[part 1 of 2: packages /MICROSAR/Dem_swc/DataTypes to /MICROSAR/Dem_swc/ComponentTypes]
AUTOSAR XML (schema 4-3-0)
package /MICROSAR/Dem_swc/DataTypes
  29 x impl type:
    Dem_EventIdType: range raw 1..65535, implementation-data-type=uint16
    Dem_RatioIdType: range raw 1..65535, implementation-data-type=uint16
    Dem_DTCStatusMaskType: range raw 0..255, implementation-data-type=uint8
    Dem_OperationCycleIdType: range raw 0..255, implementation-data-type=uint8
    Dem_DTCGroupType: range raw 0..16777215, implementation-data-type=uint32
    Dem_MaxDataValueType: category=ARRAY, sw-calibration-access=READ-ONLY
      element Dem_MaxDataValueTypeElement: array-size=18, array-size-semantics=FIXED-SIZE, implementation-data-type=uint8
    Dem_EventStatusType: compu {0=DEM_EVENT_STATUS_PASSED, 1=DEM_EVENT_STATUS_FAILED, 2=DEM_EVENT_STATUS_PREPASSED, 3=DEM_EVENT_STATUS_PREFAILED, 4=DEM_EVENT_STATUS_FDC_THRESHOLD_REACHED, 5=DEM_EVENT_STATUS_PASSED_CONDITIONS_NOT_FULFILLED, 6=DEM_EVENT_STATUS_FAILED_CONDITIONS_NOT_FULFILLED, 7=DEM_EVENT_STATUS_PREPASSED_CONDITIONS_NOT_FULFILLED, 8=DEM_EVENT_STATUS_PREFAILED_CONDITIONS_NOT_FULFILLED}, implementation-data-type=uint8
    Dem_InitMonitorReasonType: compu {1=DEM_INIT_MONITOR_CLEAR, 2=DEM_INIT_MONITOR_RESTART, 3=DEM_INIT_MONITOR_REENABLED, 4=DEM_INIT_MONITOR_STORAGE_REENABLED}, implementation-data-type=uint8
    Dem_DTCOriginType: compu {1=DEM_DTC_ORIGIN_PRIMARY_MEMORY, 2=DEM_DTC_ORIGIN_MIRROR_MEMORY, 3=DEM_DTC_ORIGIN_PERMANENT_MEMORY, 4=DEM_DTC_ORIGIN_OBD_RELEVANT_MEMORY, 5=DEM_DTC_ORIGIN_SECONDARY_MEMORY, 5=DEM_DTC_ORIGIN_USERDEFINED_MEMORY_10, 5=DEM_DTC_ORIGIN_USERDEFINED_MEMORY_11, 5=DEM_DTC_ORIGIN_USERDEFINED_MEMORY_12, 5=DEM_DTC_ORIGIN_USERDEFINED_MEMORY_13, 5=DEM_DTC_ORIGIN_USERDEFINED_MEMORY_14, 5=DEM_DTC_ORIGIN_USERDEFINED_MEMORY_15, 5=DEM_DTC_ORIGIN_USERDEFINED_MEMORY_16, 5=DEM_DTC_ORIGIN_USERDEFINED_MEMORY_17, 5=DEM_DTC_ORIGIN_USERDEFINED_MEMORY_18, 5=DEM_DTC_ORIGIN_USERDEFINED_MEMORY_19, 5=DEM_DTC_ORIGIN_USERDEFINED_MEMORY_1A, 5=DEM_DTC_ORIGIN_USERDEFINED_MEMORY_1B, 5=DEM_DTC_ORIGIN_USERDEFINED_MEMORY_1C, 5=DEM_DTC_ORIGIN_USERDEFINED_MEMORY_1D, 5=DEM_DTC_ORIGIN_USERDEFINED_MEMORY_1E, 5=DEM_DTC_ORIGIN_USERDEFINED_MEMORY_1F, 5=DEM_DTC_ORIGIN_USERDEFINED_MEMORY_20, 5=DEM_DTC_ORIGIN_USERDEFINED_MEMORY_21, 5=DEM_DTC_ORIGIN_USERDEFINED_MEMORY_22, 5=DEM_DTC_ORIGIN_USERDEFINED_MEMORY_23, 5=DEM_DTC_ORIGIN_USERDEFINED_MEMORY_24, 5=DEM_DTC_ORIGIN_USERDEFINED_MEMORY_25, 5=DEM_DTC_ORIGIN_USERDEFINED_MEMORY_26, 5=DEM_DTC_ORIGIN_USERDEFINED_MEMORY_27, 5=DEM_DTC_ORIGIN_USERDEFINED_MEMORY_28, 5=DEM_DTC_ORIGIN_USERDEFINED_MEMORY_29, 5=DEM_DTC_ORIGIN_USERDEFINED_MEMORY_2A, 5=DEM_DTC_ORIGIN_USERDEFINED_MEMORY_2B, 5=DEM_DTC_ORIGIN_USERDEFINED_MEMORY_2C, 5=DEM_DTC_ORIGIN_USERDEFINED_MEMORY_2D, 5=DEM_DTC_ORIGIN_USERDEFINED_MEMORY_2E, 5=DEM_DTC_ORIGIN_USERDEFINED_MEMORY_2F, 5=DEM_DTC_ORIGIN_USERDEFINED_MEMORY_30, 5=DEM_DTC_ORIGIN_USERDEFINED_MEMORY_31, 5=DEM_DTC_ORIGIN_USERDEFINED_MEMORY_32, 5=DEM_DTC_ORIGIN_USERDEFINED_MEMORY_33, 5=DEM_DTC_ORIGIN_USERDEFINED_MEMORY_34, 5=DEM_DTC_ORIGIN_USERDEFINED_MEMORY_35, 5=DEM_DTC_ORIGIN_USERDEFINED_MEMORY_36, 5=DEM_DTC_ORIGIN_USERDEFINED_MEMORY_37, 5=DEM_DTC_ORIGIN_USERDEFINED_MEMORY_38, 5=DEM_DTC_ORIGIN_USERDEFINED_MEMORY_39, 5=DEM_DTC_ORIGIN_USERDEFINED_MEMORY_3A, 5=DEM_DTC_ORIGIN_USERDEFINED_MEMORY_3B, 5=DEM_DTC_ORIGIN_USERDEFINED_MEMORY_3C, 5=DEM_DTC_ORIGIN_USERDEFINED_MEMORY_3D, 5=DEM_DTC_ORIGIN_USERDEFINED_MEMORY_3E, 5=DEM_DTC_ORIGIN_USERDEFINED_MEMORY_3F, 5=DEM_DTC_ORIGIN_USERDEFINED_MEMORY_40, 5=DEM_DTC_ORIGIN_USERDEFINED_MEMORY_41, 5=DEM_DTC_ORIGIN_USERDEFINED_MEMORY_42, 5=DEM_DTC_ORIGIN_USERDEFINED_MEMORY_43, 5=DEM_DTC_ORIGIN_USERDEFINED_MEMORY_44, 5=DEM_DTC_ORIGIN_USERDEFINED_MEMORY_45, 5=DEM_DTC_ORIGIN_USERDEFINED_MEMORY_46, 5=DEM_DTC_ORIGIN_USERDEFINED_MEMORY_47, 5=DEM_DTC_ORIGIN_USERDEFINED_MEMORY_48, 5=DEM_DTC_ORIGIN_USERDEFINED_MEMORY_49, 5=DEM_DTC_ORIGIN_USERDEFINED_MEMORY_4A, 5=DEM_DTC_ORIGIN_USERDEFINED_MEMORY_4B, 5=DEM_DTC_ORIGIN_USERDEFINED_MEMORY_4C, 5=DEM_DTC_ORIGIN_USERDEFINED_MEMORY_4D, 5=DEM_DTC_ORIGIN_USERDEFINED_MEMORY_4E, 5=DEM_DTC_ORIGIN_USERDEFINED_MEMORY_4F, 5=DEM_DTC_ORIGIN_USERDEFINED_MEMORY_50, 5=DEM_DTC_ORIGIN_USERDEFINED_MEMORY_51, 5=DEM_DTC_ORIGIN_USERDEFINED_MEMORY_52, 5=DEM_DTC_ORIGIN_USERDEFINED_MEMORY_53, 5=DEM_DTC_ORIGIN_USERDEFINED_MEMORY_54, 5=DEM_DTC_ORIGIN_USERDEFINED_MEMORY_55, 5=DEM_DTC_ORIGIN_USERDEFINED_MEMORY_56, 5=DEM_DTC_ORIGIN_USERDEFINED_MEMORY_57, 5=DEM_DTC_ORIGIN_USERDEFINED_MEMORY_58, 5=DEM_DTC_ORIGIN_USERDEFINED_MEMORY_59, 5=DEM_DTC_ORIGIN_USERDEFINED_MEMORY_5A, 5=DEM_DTC_ORIGIN_USERDEFINED_MEMORY_5B, 5=DEM_DTC_ORIGIN_USERDEFINED_MEMORY_5C, 5=DEM_DTC_ORIGIN_USERDEFINED_MEMORY_5D, 5=DEM_DTC_ORIGIN_USERDEFINED_MEMORY_5E, 5=DEM_DTC_ORIGIN_USERDEFINED_MEMORY_5F, 5=DEM_DTC_ORIGIN_USERDEFINED_MEMORY_60, 5=DEM_DTC_ORIGIN_USERDEFINED_MEMORY_61, 5=DEM_DTC_ORIGIN_USERDEFINED_MEMORY_62, 5=DEM_DTC_ORIGIN_USERDEFINED_MEMORY_63, 5=DEM_DTC_ORIGIN_USERDEFINED_MEMORY_64, 5=DEM_DTC_ORIGIN_USERDEFINED_MEMORY_65, 5=DEM_DTC_ORIGIN_USERDEFINED_MEMORY_66, 5=DEM_DTC_ORIGIN_USERDEFINED_MEMORY_67, 5=DEM_DTC_ORIGIN_USERDEFINED_MEMORY_68, 5=DEM_DTC_ORIGIN_USERDEFINED_MEMORY_69, 5=DEM_DTC_ORIGIN_USERDEFINED_MEMORY_6A, 5=DEM_DTC_ORIGIN_USERDEFINED_MEMORY_6B, 5=DEM_DTC_ORIGIN_USERDEFINED_MEMORY_6C, 5=DEM_DTC_ORIGIN_USERDEFINED_MEMORY_6D, 5=DEM_DTC_ORIGIN_USERDEFINED_MEMORY_6E, 5=DEM_DTC_ORIGIN_USERDEFINED_MEMORY_6F, 5=DEM_DTC_ORIGIN_USERDEFINED_MEMORY_70, 5=DEM_DTC_ORIGIN_USERDEFINED_MEMORY_71, 5=DEM_DTC_ORIGIN_USERDEFINED_MEMORY_72, 5=DEM_DTC_ORIGIN_USERDEFINED_MEMORY_73, 5=DEM_DTC_ORIGIN_USERDEFINED_MEMORY_74, 5=DEM_DTC_ORIGIN_USERDEFINED_MEMORY_75, 5=DEM_DTC_ORIGIN_USERDEFINED_MEMORY_76, 5=DEM_DTC_ORIGIN_USERDEFINED_MEMORY_77, 5=DEM_DTC_ORIGIN_USERDEFINED_MEMORY_78, 5=DEM_DTC_ORIGIN_USERDEFINED_MEMORY_79, 5=DEM_DTC_ORIGIN_USERDEFINED_MEMORY_7A, 5=DEM_DTC_ORIGIN_USERDEFINED_MEMORY_7B, 5=DEM_DTC_ORIGIN_USERDEFINED_MEMORY_7C, 5=DEM_DTC_ORIGIN_USERDEFINED_MEMORY_7D, 5=DEM_DTC_ORIGIN_USERDEFINED_MEMORY_7E, 5=DEM_DTC_ORIGIN_USERDEFINED_MEMORY_7F, 5=DEM_DTC_ORIGIN_USERDEFINED_MEMORY_80, 5=DEM_DTC_ORIGIN_USERDEFINED_MEMORY_81, 5=DEM_DTC_ORIGIN_USERDEFINED_MEMORY_82, 5=DEM_DTC_ORIGIN_USERDEFINED_MEMORY_83, 5=DEM_DTC_ORIGIN_USERDEFINED_MEMORY_84, 5=DEM_DTC_ORIGIN_USERDEFINED_MEMORY_85, 5=DEM_DTC_ORIGIN_USERDEFINED_MEMORY_86, 5=DEM_DTC_ORIGIN_USERDEFINED_MEMORY_87, 5=DEM_DTC_ORIGIN_USERDEFINED_MEMORY_88, 5=DEM_DTC_ORIGIN_USERDEFINED_MEMORY_89, 5=DEM_DTC_ORIGIN_USERDEFINED_MEMORY_8A, 5=DEM_DTC_ORIGIN_USERDEFINED_MEMORY_8B, 5=DEM_DTC_ORIGIN_USERDEFINED_MEMORY_8C, 5=DEM_DTC_ORIGIN_USERDEFINED_MEMORY_8D, 5=DEM_DTC_ORIGIN_USERDEFINED_MEMORY_8E, 5=DEM_DTC_ORIGIN_USERDEFINED_MEMORY_8F, 5=DEM_DTC_ORIGIN_USERDEFINED_MEMORY_90, 5=DEM_DTC_ORIGIN_USERDEFINED_MEMORY_91, 5=DEM_DTC_ORIGIN_USERDEFINED_MEMORY_92, 5=DEM_DTC_ORIGIN_USERDEFINED_MEMORY_93, 5=DEM_DTC_ORIGIN_USERDEFINED_MEMORY_94, 5=DEM_DTC_ORIGIN_USERDEFINED_MEMORY_95, 5=DEM_DTC_ORIGIN_USERDEFINED_MEMORY_96, 5=DEM_DTC_ORIGIN_USERDEFINED_MEMORY_97, 5=DEM_DTC_ORIGIN_USERDEFINED_MEMORY_98, 5=DEM_DTC_ORIGIN_USERDEFINED_MEMORY_99, 5=DEM_DTC_ORIGIN_USERDEFINED_MEMORY_9A, 5=DEM_DTC_ORIGIN_USERDEFINED_MEMORY_9B, 5=DEM_DTC_ORIGIN_USERDEFINED_MEMORY_9C, 5=DEM_DTC_ORIGIN_USERDEFINED_MEMORY_9D, 5=DEM_DTC_ORIGIN_USERDEFINED_MEMORY_9E, 5=DEM_DTC_ORIGIN_USERDEFINED_MEMORY_9F, 5=DEM_DTC_ORIGIN_USERDEFINED_MEMORY_A0, 5=DEM_DTC_ORIGIN_USERDEFINED_MEMORY_A1, 5=DEM_DTC_ORIGIN_USERDEFINED_MEMORY_A2, 5=DEM_DTC_ORIGIN_USERDEFINED_MEMORY_A3, 5=DEM_DTC_ORIGIN_USERDEFINED_MEMORY_A4, 5=DEM_DTC_ORIGIN_USERDEFINED_MEMORY_A5, 5=DEM_DTC_ORIGIN_USERDEFINED_MEMORY_A6, 5=DEM_DTC_ORIGIN_USERDEFINED_MEMORY_A7, 5=DEM_DTC_ORIGIN_USERDEFINED_MEMORY_A8, 5=DEM_DTC_ORIGIN_USERDEFINED_MEMORY_A9, 5=DEM_DTC_ORIGIN_USERDEFINED_MEMORY_AA, 5=DEM_DTC_ORIGIN_USERDEFINED_MEMORY_AB, 5=DEM_DTC_ORIGIN_USERDEFINED_MEMORY_AC, 5=DEM_DTC_ORIGIN_USERDEFINED_MEMORY_AD, 5=DEM_DTC_ORIGIN_USERDEFINED_MEMORY_AE, 5=DEM_DTC_ORIGIN_USERDEFINED_MEMORY_AF, 5=DEM_DTC_ORIGIN_USERDEFINED_MEMORY_B0, 5=DEM_DTC_ORIGIN_USERDEFINED_MEMORY_B1, 5=DEM_DTC_ORIGIN_USERDEFINED_MEMORY_B2, 5=DEM_DTC_ORIGIN_USERDEFINED_MEMORY_B3, 5=DEM_DTC_ORIGIN_USERDEFINED_MEMORY_B4, 5=DEM_DTC_ORIGIN_USERDEFINED_MEMORY_B5, 5=DEM_DTC_ORIGIN_USERDEFINED_MEMORY_B6, 5=DEM_DTC_ORIGIN_USERDEFINED_MEMORY_B7, 5=DEM_DTC_ORIGIN_USERDEFINED_MEMORY_B8, 5=DEM_DTC_ORIGIN_USERDEFINED_MEMORY_B9, 5=DEM_DTC_ORIGIN_USERDEFINED_MEMORY_BA, 5=DEM_DTC_ORIGIN_USERDEFINED_MEMORY_BB, 5=DEM_DTC_ORIGIN_USERDEFINED_MEMORY_BC, 5=DEM_DTC_ORIGIN_USERDEFINED_MEMORY_BD, 5=DEM_DTC_ORIGIN_USERDEFINED_MEMORY_BE, 5=DEM_DTC_ORIGIN_USERDEFINED_MEMORY_BF, 5=DEM_DTC_ORIGIN_USERDEFINED_MEMORY_C0, 5=DEM_DTC_ORIGIN_USERDEFINED_MEMORY_C1, 5=DEM_DTC_ORIGIN_USERDEFINED_MEMORY_C2, 5=DEM_DTC_ORIGIN_USERDEFINED_MEMORY_C3, 5=DEM_DTC_ORIGIN_USERDEFINED_MEMORY_C4, 5=DEM_DTC_ORIGIN_USERDEFINED_MEMORY_C5, 5=DEM_DTC_ORIGIN_USERDEFINED_MEMORY_C6, 5=DEM_DTC_ORIGIN_USERDEFINED_MEMORY_C7, 5=DEM_DTC_ORIGIN_USERDEFINED_MEMORY_C8, 5=DEM_DTC_ORIGIN_USERDEFINED_MEMORY_C9, 5=DEM_DTC_ORIGIN_USERDEFINED_MEMORY_CA, 5=DEM_DTC_ORIGIN_USERDEFINED_MEMORY_CB, 5=DEM_DTC_ORIGIN_USERDEFINED_MEMORY_CC, 5=DEM_DTC_ORIGIN_USERDEFINED_MEMORY_CD, 5=DEM_DTC_ORIGIN_USERDEFINED_MEMORY_CE, 5=DEM_DTC_ORIGIN_USERDEFINED_MEMORY_CF, 5=DEM_DTC_ORIGIN_USERDEFINED_MEMORY_D0, 5=DEM_DTC_ORIGIN_USERDEFINED_MEMORY_D1, 5=DEM_DTC_ORIGIN_USERDEFINED_MEMORY_D2, 5=DEM_DTC_ORIGIN_USERDEFINED_MEMORY_D3, 5=DEM_DTC_ORIGIN_USERDEFINED_MEMORY_D4, 5=DEM_DTC_ORIGIN_USERDEFINED_MEMORY_D5, 5=DEM_DTC_ORIGIN_USERDEFINED_MEMORY_D6, 5=DEM_DTC_ORIGIN_USERDEFINED_MEMORY_D7, 5=DEM_DTC_ORIGIN_USERDEFINED_MEMORY_D8, 5=DEM_DTC_ORIGIN_USERDEFINED_MEMORY_D9, 5=DEM_DTC_ORIGIN_USERDEFINED_MEMORY_DA, 5=DEM_DTC_ORIGIN_USERDEFINED_MEMORY_DB, 5=DEM_DTC_ORIGIN_USERDEFINED_MEMORY_DC, 5=DEM_DTC_ORIGIN_USERDEFINED_MEMORY_DD, 5=DEM_DTC_ORIGIN_USERDEFINED_MEMORY_DE, 5=DEM_DTC_ORIGIN_USERDEFINED_MEMORY_DF, 5=DEM_DTC_ORIGIN_USERDEFINED_MEMORY_E0, 5=DEM_DTC_ORIGIN_USERDEFINED_MEMORY_E1, 5=DEM_DTC_ORIGIN_USERDEFINED_MEMORY_E2, 5=DEM_DTC_ORIGIN_USERDEFINED_MEMORY_E3, 5=DEM_DTC_ORIGIN_USERDEFINED_MEMORY_E4, 5=DEM_DTC_ORIGIN_USERDEFINED_MEMORY_E5, 5=DEM_DTC_ORIGIN_USERDEFINED_MEMORY_E6, 5=DEM_DTC_ORIGIN_USERDEFINED_MEMORY_E7, 5=DEM_DTC_ORIGIN_USERDEFINED_MEMORY_E8, 5=DEM_DTC_ORIGIN_USERDEFINED_MEMORY_E9, 5=DEM_DTC_ORIGIN_USERDEFINED_MEMORY_EA, 5=DEM_DTC_ORIGIN_USERDEFINED_MEMORY_EB, 5=DEM_DTC_ORIGIN_USERDEFINED_MEMORY_EC, 5=DEM_DTC_ORIGIN_USERDEFINED_MEMORY_ED, 5=DEM_DTC_ORIGIN_USERDEFINED_MEMORY_EE, 5=DEM_DTC_ORIGIN_USERDEFINED_MEMORY_EF, 5=DEM_DTC_ORIGIN_USERDEFINED_MEMORY_F0, 5=DEM_DTC_ORIGIN_USERDEFINED_MEMORY_F1, 5=DEM_DTC_ORIGIN_USERDEFINED_MEMORY_F2, 5=DEM_DTC_ORIGIN_USERDEFINED_MEMORY_F3, 5=DEM_DTC_ORIGIN_USERDEFINED_MEMORY_F4, 5=DEM_DTC_ORIGIN_USERDEFINED_MEMORY_F5, 5=DEM_DTC_ORIGIN_USERDEFINED_MEMORY_F6, 5=DEM_DTC_ORIGIN_USERDEFINED_MEMORY_F7, 5=DEM_DTC_ORIGIN_USERDEFINED_MEMORY_F8, 5=DEM_DTC_ORIGIN_USERDEFINED_MEMORY_F9, 5=DEM_DTC_ORIGIN_USERDEFINED_MEMORY_FA, 5=DEM_DTC_ORIGIN_USERDEFINED_MEMORY_FB, 5=DEM_DTC_ORIGIN_USERDEFINED_MEMORY_FC, 5=DEM_DTC_ORIGIN_USERDEFINED_MEMORY_FD, 5=DEM_DTC_ORIGIN_USERDEFINED_MEMORY_FE, 5=DEM_DTC_ORIGIN_USERDEFINED_MEMORY_FF}, implementation-data-type=uint16
    Dem_DTCFormatType: compu {0=DEM_DTC_FORMAT_OBD, 1=DEM_DTC_FORMAT_UDS, 2=DEM_DTC_FORMAT_J1939}, implementation-data-type=uint8
    Dem_OperationCycleStateType: compu {0=DEM_CYCLE_STATE_START, 1=DEM_CYCLE_STATE_END}, implementation-data-type=uint8
    Dem_IndicatorStatusType: compu {0=DEM_INDICATOR_OFF, 1=DEM_INDICATOR_CONTINUOUS, 2=DEM_INDICATOR_BLINKING, 3=DEM_INDICATOR_BLINK_CONT, 4=DEM_INDICATOR_SLOW_FLASH, 5=DEM_INDICATOR_FAST_FLASH, 6=DEM_INDICATOR_ON_DEMAND, 7=DEM_INDICATOR_SHORT}, implementation-data-type=uint8
    Dem_DTCKindType: compu {1=DEM_DTC_KIND_ALL_DTCS, 2=DEM_DTC_KIND_EMISSION_REL_DTCS}, implementation-data-type=uint8
    Dem_IumprDenomCondIdType: compu {1=DEM_IUMPR_GENERAL_DENOMINATOR, 2=DEM_IUMPR_DEN_COND_COLDSTART, 3=DEM_IUMPR_DEN_COND_EVAP, 4=DEM_IUMPR_DEN_COND_500MI}, implementation-data-type=uint8
    Dem_IumprDenomCondStatusType: compu {0=DEM_IUMPR_DEN_STATUS_NOT_REACHED, 1=DEM_IUMPR_DEN_STATUS_REACHED, 2=DEM_IUMPR_DEN_STATUS_INHIBITED}, implementation-data-type=uint8
    Dem_DebounceResetStatusType: compu {0=DEM_DEBOUNCE_STATUS_FREEZE, 1=DEM_DEBOUNCE_STATUS_RESET}, implementation-data-type=uint8
    Dem_IumprReadinessGroupType: compu {0=DEM_IUMPR_BOOSTPRS, 1=DEM_IUMPR_CAT1, 2=DEM_IUMPR_CAT2, 3=DEM_IUMPR_EGR, 4=DEM_IUMPR_EGSENSOR, 5=DEM_IUMPR_EVAP, 6=DEM_IUMPR_NMHCCAT, 7=DEM_IUMPR_NOXADSORB, 8=DEM_IUMPR_NOXCAT, 9=DEM_IUMPR_OXS1, 10=DEM_IUMPR_OXS2, 11=DEM_IUMPR_PMFILTER, 12=DEM_IUMPR_PRIVATE, 13=DEM_IUMPR_SAIR, 14=DEM_IUMPR_SECOXS1, 15=DEM_IUMPR_SECOXS2, 16=DEM_IUMPR_FLSYS, 255=DEM_IUMPR_ALLGROUPS}, implementation-data-type=uint8
    Dem_DTRControlType: compu {0=DEM_DTR_CTL_NORMAL, 1=DEM_DTR_CTL_NO_MAX, 2=DEM_DTR_CTL_NO_MIN, 3=DEM_DTR_CTL_RESET, 4=DEM_DTR_CTL_INVISIBLE}, implementation-data-type=uint8
    Dem_DebouncingStateType: compu {mask 1: 1=DEM_TEMPORARILY_DEFECTIVE, mask 2: 2=DEM_FINALLY_DEFECTIVE, mask 4: 4=DEM_TEMPORARILY_HEALED, mask 8: 8=DEM_TEST_COMPLETE, mask 16: 16=DEM_DTR_UPDATE}, range raw 0..255, implementation-data-type=uint8
    Dem_DTCSeverityType:
      compu {mask 255: 0=DEM_SEVERITY_NO_SEVERITY, mask 31: 2=DEM_SEVERITY_WWHOBD_CLASS_A, mask 31: 4=DEM_SEVERITY_WWHOBD_CLASS_B1, mask 31: 8=DEM_SEVERITY_WWHOBD_CLASS_B2, mask 31: 16=DEM_SEVERITY_WWHOBD_CLASS_C, mask 31: 1=DEM_SEVERITY_WWHOBD_CLASS_NO_CLASS, mask 224: 64=DEM_SEVERITY_CHECK_AT_NEXT_HALT, mask 224: 128=DEM_SEVERITY_CHECK_IMMEDIATELY, mask 224: 32=DEM_SEVERITY_MAINTENANCE_ONLY}
      range raw 0..255
      implementation-data-type=uint8
    Dem_UdsStatusByteType: compu {mask 1: 1=DEM_UDS_STATUS_TF, mask 2: 2=DEM_UDS_STATUS_TFTOC, mask 4: 4=DEM_UDS_STATUS_PDTC, mask 8: 8=DEM_UDS_STATUS_CDTC, mask 16: 16=DEM_UDS_STATUS_TNCSLC, mask 32: 32=DEM_UDS_STATUS_TFSLC, mask 64: 64=DEM_UDS_STATUS_TNCTOC, mask 128: 128=DEM_UDS_STATUS_WIR}, range raw 0..255, implementation-data-type=uint8
    Dem_MonitorStatusType: compu {mask 1: 1=DEM_MONITOR_STATUS_TF, mask 2: 2=DEM_MONITOR_STATUS_TNCTOC}, range raw 0..255, implementation-data-type=uint8
    DataArrayType_uint8_4: category=ARRAY, sw-calibration-access=READ-ONLY
      element DataArrayType_uint8_4Element: array-size=4, array-size-semantics=FIXED-SIZE, implementation-data-type=uint8
    DataArrayType_uint8_3: category=ARRAY, sw-calibration-access=READ-ONLY
      element DataArrayType_uint8_3Element: array-size=3, array-size-semantics=FIXED-SIZE, implementation-data-type=uint8
    DataArrayType_uint8_1: category=ARRAY, sw-calibration-access=READ-ONLY
      element DataArrayType_uint8_1Element: array-size=1, array-size-semantics=FIXED-SIZE, implementation-data-type=uint8
    DataArrayType_uint8_7: category=ARRAY, sw-calibration-access=READ-ONLY
      element DataArrayType_uint8_7Element: array-size=7, array-size-semantics=FIXED-SIZE, implementation-data-type=uint8
    DataArrayType_uint8_6: category=ARRAY, sw-calibration-access=READ-ONLY
      element DataArrayType_uint8_6Element: array-size=6, array-size-semantics=FIXED-SIZE, implementation-data-type=uint8
    DataArrayType_uint8_18: category=ARRAY, sw-calibration-access=READ-ONLY
      element DataArrayType_uint8_18Element: array-size=18, array-size-semantics=FIXED-SIZE, implementation-data-type=uint8
    DataArrayType_uint8_2: category=ARRAY, sw-calibration-access=READ-ONLY
      element DataArrayType_uint8_2Element: array-size=2, array-size-semantics=FIXED-SIZE, implementation-data-type=uint8
package /MICROSAR/Dem_swc/Interfaces
  25 x client server interface, all with is-service=true, service-kind=DIAGNOSTIC-EVENT-MANAGER:
    DemServices
      operation GetPostRunRequested: possible-error=DemServices/E_NOT_OK
        arg IsRequested: type=boolean, direction=OUT
      operation GetDTCStatusAvailabilityMask: possible-error=DemServices/E_NOT_OK
        arg ClientId: type=uint8, direction=IN
        arg DTCStatusMask: type=uint8, direction=OUT
      error E_NOT_OK: error-code=1
    CallbackClearEventAllowed
      operation ClearEventAllowed: possible-error=CallbackClearEventAllowed/E_NOT_OK
        arg Allowed: type=boolean, direction=OUT
      error E_NOT_OK: error-code=1
    ClearDTC
      operation ClearDTC: possible-error=[ClearDTC/E_NOT_OK, DEM_CLEAR_FAILED, DEM_PENDING, DEM_CLEAR_BUSY, DEM_CLEAR_MEMORY_ERROR, DEM_WRONG_DTC, DEM_WRONG_DTCORIGIN]
      operation SelectDTC: possible-error=[ClearDTC/E_OK, ClearDTC/E_NOT_OK]
        arg DTC: type=uint32, direction=IN
        arg DTCFormat: type=Dem_DTCFormatType, direction=IN
        arg DTCOrigin: type=Dem_DTCOriginType, direction=IN
      8 x error:
        E_OK: error-code=0
        E_NOT_OK: error-code=1
        DEM_CLEAR_FAILED: error-code=7
        DEM_PENDING: error-code=4
        DEM_CLEAR_BUSY: error-code=5
        DEM_CLEAR_MEMORY_ERROR: error-code=6
        DEM_WRONG_DTC: error-code=8
        DEM_WRONG_DTCORIGIN: error-code=9
    EnableCondition
      operation SetEnableCondition: possible-error=EnableCondition/E_NOT_OK
        arg ConditionFulfilled: type=boolean, direction=IN
      error E_NOT_OK: error-code=1
    EvMemOverflowIndication
      operation GetEventMemoryOverflow: possible-error=EvMemOverflowIndication/E_NOT_OK
        arg OverflowIndication: type=boolean, direction=OUT
      operation GetNumberOfEventMemoryEntries: possible-error=EvMemOverflowIndication/E_NOT_OK
        arg NumberOfEventMemoryEntries: type=uint8, direction=OUT
      error E_NOT_OK: error-code=1
    GeneralDiagnosticInfo
      11 x operation:
        GetEventUdsStatus: possible-error=GeneralDiagnosticInfo/E_NOT_OK
          arg EventId: type=Dem_EventIdType, direction=IN
          arg UDSStatusByte: type=Dem_UdsStatusByteType, direction=OUT
        GetEventStatus: possible-error=GeneralDiagnosticInfo/E_NOT_OK
          arg EventId: type=Dem_EventIdType, direction=IN
          arg UDSStatusByte: type=Dem_UdsStatusByteType, direction=OUT
        GetEventFailed: possible-error=GeneralDiagnosticInfo/E_NOT_OK
          arg EventId: type=Dem_EventIdType, direction=IN
          arg EventFailed: type=boolean, direction=OUT
        GetEventTested: possible-error=GeneralDiagnosticInfo/E_NOT_OK
          arg EventId: type=Dem_EventIdType, direction=IN
          arg EventTested: type=boolean, direction=OUT
        GetDTCOfEvent: possible-error=[GeneralDiagnosticInfo/E_NOT_OK, GeneralDiagnosticInfo/DEM_E_NO_DTC_AVAILABLE]
          arg EventId: type=Dem_EventIdType, direction=IN
          arg DTCFormat: type=Dem_DTCFormatType, direction=IN
          arg DTCOfEvent: type=uint32, direction=OUT
        GetFaultDetectionCounter: possible-error=[GeneralDiagnosticInfo/E_NOT_OK, GeneralDiagnosticInfo/DEM_E_NO_FDC_AVAILABLE]
          arg EventId: type=Dem_EventIdType, direction=IN
          arg FaultDetectionCounter: type=sint8, direction=OUT
        GetEventFreezeFrameDataEx: possible-error=[GeneralDiagnosticInfo/E_NOT_OK, GeneralDiagnosticInfo/DEM_BUFFER_TOO_SMALL, GeneralDiagnosticInfo/DEM_NO_SUCH_ELEMENT]
          5 x arg:
            EventId: type=Dem_EventIdType, direction=IN
            RecordNumber: type=uint8, direction=IN
            DataId: type=uint16, direction=IN
            DestBuffer: type=Dem_MaxDataValueType, direction=OUT
            BufSize: type=uint16, direction=INOUT
        GetEventExtendedDataRecordEx: possible-error=[GeneralDiagnosticInfo/E_NOT_OK, GeneralDiagnosticInfo/DEM_BUFFER_TOO_SMALL, GeneralDiagnosticInfo/DEM_NO_SUCH_ELEMENT]
          4 x arg:
            EventId: type=Dem_EventIdType, direction=IN
            RecordNumber: type=uint8, direction=IN
            DestBuffer: type=Dem_MaxDataValueType, direction=OUT
            BufSize: type=uint16, direction=INOUT
        GetEventEnableCondition: possible-error=GeneralDiagnosticInfo/E_NOT_OK
          arg EventId: type=Dem_EventIdType, direction=IN
          arg ConditionFullfilled: type=boolean, direction=OUT
        GetDebouncingOfEvent: possible-error=GeneralDiagnosticInfo/E_NOT_OK
          arg EventId: type=Dem_EventIdType, direction=IN
          arg DebouncingState: type=Dem_DebouncingStateType, direction=OUT
        GetMonitorStatus: possible-error=GeneralDiagnosticInfo/E_NOT_OK
          arg EventId: type=Dem_EventIdType, direction=IN
          arg MonitorStatus: type=Dem_MonitorStatusType, direction=OUT
      5 x error:
        E_NOT_OK: error-code=1
        DEM_E_NO_DTC_AVAILABLE: error-code=10
        DEM_E_NO_FDC_AVAILABLE: error-code=14
        DEM_BUFFER_TOO_SMALL: error-code=21
        DEM_NO_SUCH_ELEMENT: error-code=48
    OperationCycle
      operation GetOperationCycleState: possible-error=[OperationCycle/E_OK, OperationCycle/E_NOT_OK]
        arg CycleState: type=Dem_OperationCycleStateType, direction=OUT
      operation SetOperationCycleState: possible-error=[OperationCycle/E_OK, OperationCycle/E_NOT_OK]
        arg CycleState: type=Dem_OperationCycleStateType, direction=IN
      error E_OK: error-code=0
      error E_NOT_OK: error-code=1
    CSDataServices_DemDataElementClass_Systemzeit
      operation ReadData: possible-error=CSDataServices_DemDataElementClass_Systemzeit/E_NOT_OK
        arg Data: type=DataArrayType_uint8_4, direction=OUT
      error E_NOT_OK: error-code=1
    CSDataServices_DemDataElementClass_KmStand
      operation ReadData: possible-error=CSDataServices_DemDataElementClass_KmStand/E_NOT_OK
        arg Data: type=DataArrayType_uint8_3, direction=OUT
      error E_NOT_OK: error-code=1
    CSDataServices_DemDataElementClass_EthDiscardedArpEntry
      operation ReadData: possible-error=CSDataServices_DemDataElementClass_EthDiscardedArpEntry/E_NOT_OK
        arg Data: type=DataArrayType_uint8_1, direction=OUT
      error E_NOT_OK: error-code=1
    CSDataServices_DemDataElementClass_SwtVin
      operation ReadData: possible-error=CSDataServices_DemDataElementClass_SwtVin/E_NOT_OK
        arg Data: type=DataArrayType_uint8_7, direction=OUT
      error E_NOT_OK: error-code=1
    CSDataServices_DemDataElementClass_FUwBn
      operation ReadData: possible-error=CSDataServices_DemDataElementClass_FUwBn/E_NOT_OK
        arg Data: type=DataArrayType_uint8_1, direction=OUT
      error E_NOT_OK: error-code=1
    CSDataServices_DemDataElementClass_Port0LowSignalQualityStatus
      operation ReadData: possible-error=CSDataServices_DemDataElementClass_Port0LowSignalQualityStatus/E_NOT_OK
        arg Data: type=DataArrayType_uint8_1, direction=OUT
      error E_NOT_OK: error-code=1
    CSDataServices_DemDataElementClass_Port0CrcErrorCount
      operation ReadData: possible-error=CSDataServices_DemDataElementClass_Port0CrcErrorCount/E_NOT_OK
        arg Data: type=DataArrayType_uint8_1, direction=OUT
      error E_NOT_OK: error-code=1
    CSDataServices_DemDataElementClass_EthSourceMacOfDuplicateIpAddress
      operation ReadData: possible-error=CSDataServices_DemDataElementClass_EthSourceMacOfDuplicateIpAddress/E_NOT_OK
        arg Data: type=DataArrayType_uint8_6, direction=OUT
      error E_NOT_OK: error-code=1
    CSDataServices_DemDataElementClass_FileManipulated
      operation ReadData: possible-error=CSDataServices_DemDataElementClass_FileManipulated/E_NOT_OK
        arg Data: type=DataArrayType_uint8_18, direction=OUT
      error E_NOT_OK: error-code=1
    CSDataServices_DemDataElementClass_SwtFehlerwert
      operation ReadData: possible-error=CSDataServices_DemDataElementClass_SwtFehlerwert/E_NOT_OK
        arg Data: type=DataArrayType_uint8_1, direction=OUT
      error E_NOT_OK: error-code=1
    CSDataServices_DemDataElementClass_FUwTn
      operation ReadData: possible-error=CSDataServices_DemDataElementClass_FUwTn/E_NOT_OK
        arg Data: type=DataArrayType_uint8_3, direction=OUT
      error E_NOT_OK: error-code=1
    CSDataServices_DemDataElementClass_EthDroppedFrameStatus
      operation ReadData: possible-error=CSDataServices_DemDataElementClass_EthDroppedFrameStatus/E_NOT_OK
        arg Data: type=DataArrayType_uint8_1, direction=OUT
      error E_NOT_OK: error-code=1
    CSDataServices_DemDataElementClass_EthArpDiscardType
      operation ReadData: possible-error=CSDataServices_DemDataElementClass_EthArpDiscardType/E_NOT_OK
        arg Data: type=DataArrayType_uint8_1, direction=OUT
      error E_NOT_OK: error-code=1
    CSDataServices_DemDataElementClass_SwtSwid
      operation ReadData: possible-error=CSDataServices_DemDataElementClass_SwtSwid/E_NOT_OK
        arg Data: type=DataArrayType_uint8_4, direction=OUT
      error E_NOT_OK: error-code=1
    CSDataServices_DemDataElementClass_StartApplication
      operation ReadData: possible-error=CSDataServices_DemDataElementClass_StartApplication/E_NOT_OK
        arg Data: type=DataArrayType_uint8_2, direction=OUT
      error E_NOT_OK: error-code=1
    DiagnosticInfo
      11 x operation:
        GetEventUdsStatus: possible-error=DiagnosticInfo/E_NOT_OK
          arg UDSStatusByte: type=Dem_UdsStatusByteType, direction=OUT
        GetEventStatus: possible-error=DiagnosticInfo/E_NOT_OK
          arg UDSStatusByte: type=Dem_UdsStatusByteType, direction=OUT
        GetEventFailed: possible-error=DiagnosticInfo/E_NOT_OK
          arg EventFailed: type=boolean, direction=OUT
        GetEventTested: possible-error=DiagnosticInfo/E_NOT_OK
          arg EventTested: type=boolean, direction=OUT
        GetDTCOfEvent: possible-error=[DiagnosticInfo/E_NOT_OK, DiagnosticInfo/DEM_E_NO_DTC_AVAILABLE]
          arg DTCFormat: type=Dem_DTCFormatType, direction=IN
          arg DTCOfEvent: type=uint32, direction=OUT
        GetFaultDetectionCounter: possible-error=[DiagnosticInfo/E_NOT_OK, DiagnosticInfo/DEM_E_NO_FDC_AVAILABLE]
          arg FaultDetectionCounter: type=sint8, direction=OUT
        GetEventFreezeFrameDataEx: possible-error=[DiagnosticInfo/E_NOT_OK, DiagnosticInfo/DEM_BUFFER_TOO_SMALL, DiagnosticInfo/DEM_NO_SUCH_ELEMENT]
          4 x arg:
            RecordNumber: type=uint8, direction=IN
            DataId: type=uint16, direction=IN
            DestBuffer: type=Dem_MaxDataValueType, direction=OUT
            BufSize: type=uint16, direction=INOUT
        GetEventExtendedDataRecordEx: possible-error=[DiagnosticInfo/E_NOT_OK, DiagnosticInfo/DEM_BUFFER_TOO_SMALL, DiagnosticInfo/DEM_NO_SUCH_ELEMENT]
          arg RecordNumber: type=uint8, direction=IN
          arg DestBuffer: type=Dem_MaxDataValueType, direction=OUT
          arg BufSize: type=uint16, direction=INOUT
        GetEventEnableCondition: possible-error=DiagnosticInfo/E_NOT_OK
          arg ConditionFullfilled: type=boolean, direction=OUT
        GetDebouncingOfEvent: possible-error=DiagnosticInfo/E_NOT_OK
          arg DebouncingState: type=Dem_DebouncingStateType, direction=OUT
        GetMonitorStatus: possible-error=DiagnosticInfo/E_NOT_OK
          arg MonitorStatus: type=Dem_MonitorStatusType, direction=OUT
      5 x error:
        E_NOT_OK: error-code=1
        DEM_E_NO_DTC_AVAILABLE: error-code=10
        DEM_E_NO_FDC_AVAILABLE: error-code=14
        DEM_BUFFER_TOO_SMALL: error-code=21
        DEM_NO_SUCH_ELEMENT: error-code=48
    DiagnosticMonitor
      11 x operation:
        SetEventStatus: possible-error=DiagnosticMonitor/E_NOT_OK
          arg EventStatus: type=Dem_EventStatusType, direction=IN
        ResetEventStatus: possible-error=DiagnosticMonitor/E_NOT_OK
        ResetEventDebounceStatus: possible-error=DiagnosticMonitor/E_NOT_OK
          arg DebounceResetStatus: type=Dem_DebounceResetStatusType, direction=IN
        GetEventUdsStatus: possible-error=DiagnosticMonitor/E_NOT_OK
          arg UDSStatusByte: type=Dem_UdsStatusByteType, direction=OUT
        GetEventStatus: possible-error=DiagnosticMonitor/E_NOT_OK
          arg UDSStatusByte: type=Dem_UdsStatusByteType, direction=OUT
        GetEventFailed: possible-error=DiagnosticMonitor/E_NOT_OK
          arg EventFailed: type=boolean, direction=OUT
        GetEventTested: possible-error=DiagnosticMonitor/E_NOT_OK
          arg EventTested: type=boolean, direction=OUT
        GetDTCOfEvent: possible-error=[DiagnosticMonitor/E_NOT_OK, DiagnosticMonitor/DEM_E_NO_DTC_AVAILABLE]
          arg DTCFormat: type=Dem_DTCFormatType, direction=IN
          arg DTCOfEvent: type=uint32, direction=OUT
        GetFaultDetectionCounter: possible-error=[DiagnosticMonitor/E_NOT_OK, DiagnosticMonitor/DEM_E_NO_FDC_AVAILABLE]
          arg FaultDetectionCounter: type=sint8, direction=OUT
        GetEventFreezeFrameDataEx: possible-error=[DiagnosticMonitor/E_NOT_OK, DiagnosticMonitor/DEM_BUFFER_TOO_SMALL, DiagnosticMonitor/DEM_NO_SUCH_ELEMENT]
          4 x arg:
            RecordNumber: type=uint8, direction=IN
            DataId: type=uint16, direction=IN
            DestBuffer: type=Dem_MaxDataValueType, direction=OUT
            BufSize: type=uint16, direction=INOUT
        GetEventExtendedDataRecordEx: possible-error=[DiagnosticMonitor/E_NOT_OK, DiagnosticMonitor/DEM_BUFFER_TOO_SMALL, DiagnosticMonitor/DEM_NO_SUCH_ELEMENT]
          arg RecordNumber: type=uint8, direction=IN
          arg DestBuffer: type=Dem_MaxDataValueType, direction=OUT
          arg BufSize: type=uint16, direction=INOUT
      5 x error:
        E_NOT_OK: error-code=1
        DEM_E_NO_DTC_AVAILABLE: error-code=10
        DEM_E_NO_FDC_AVAILABLE: error-code=14
        DEM_BUFFER_TOO_SMALL: error-code=21
        DEM_NO_SUCH_ELEMENT: error-code=48
    GeneralCallbackEventDataChanged
      operation EventDataChanged
        arg EventId: type=Dem_EventIdType, direction=IN
package /MICROSAR/Dem_swc/ComponentTypes
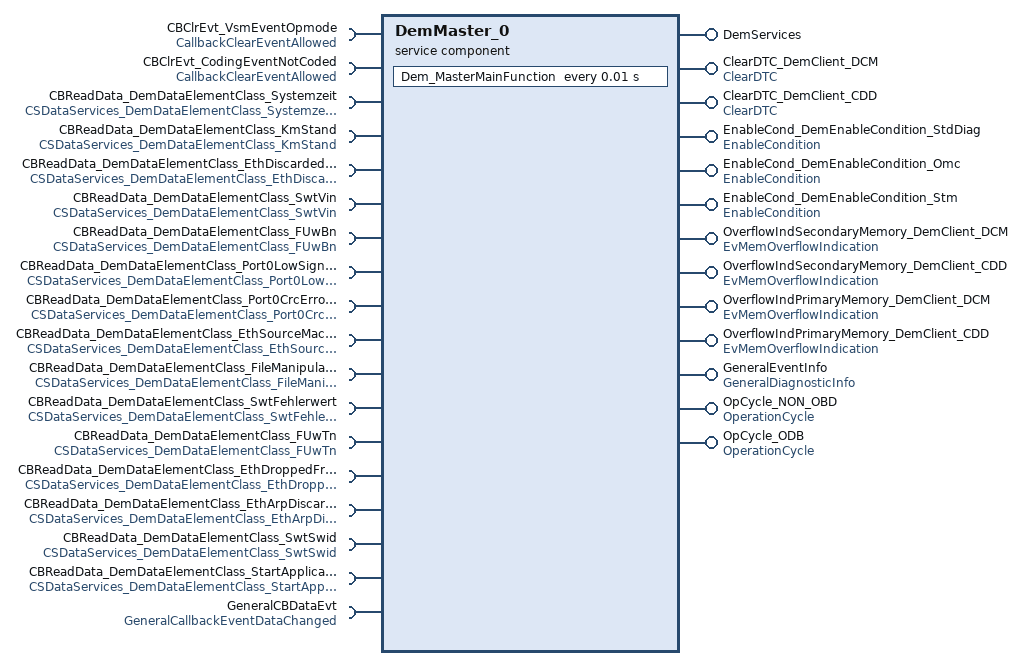
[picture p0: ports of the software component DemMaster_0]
  service sw component type DemMaster_0: category=SERVICE_COMPONENT
    provide port DemServices: provided-interface=DemServices
    require port CBClrEvt_VsmEventOpmode: required-interface=CallbackClearEventAllowed
    require port CBClrEvt_CodingEventNotCoded: required-interface=CallbackClearEventAllowed
    12 x provide port:
      ClearDTC_DemClient_DCM: provided-interface=ClearDTC
      ClearDTC_DemClient_CDD: provided-interface=ClearDTC
      EnableCond_DemEnableCondition_StdDiag: provided-interface=EnableCondition
      EnableCond_DemEnableCondition_Omc: provided-interface=EnableCondition
      EnableCond_DemEnableCondition_Stm: provided-interface=EnableCondition
      OverflowIndSecondaryMemory_DemClient_DCM: provided-interface=EvMemOverflowIndication
      OverflowIndSecondaryMemory_DemClient_CDD: provided-interface=EvMemOverflowIndication
      OverflowIndPrimaryMemory_DemClient_DCM: provided-interface=EvMemOverflowIndication
      OverflowIndPrimaryMemory_DemClient_CDD: provided-interface=EvMemOverflowIndication
      GeneralEventInfo: provided-interface=GeneralDiagnosticInfo
      OpCycle_NON_OBD: provided-interface=OperationCycle
      OpCycle_ODB: provided-interface=OperationCycle
    16 x require port:
      CBReadData_DemDataElementClass_Systemzeit: required-interface=CSDataServices_DemDataElementClass_Systemzeit
      CBReadData_DemDataElementClass_KmStand: required-interface=CSDataServices_DemDataElementClass_KmStand
      CBReadData_DemDataElementClass_EthDiscardedArpEntry: required-interface=CSDataServices_DemDataElementClass_EthDiscardedArpEntry
      CBReadData_DemDataElementClass_SwtVin: required-interface=CSDataServices_DemDataElementClass_SwtVin
      CBReadData_DemDataElementClass_FUwBn: required-interface=CSDataServices_DemDataElementClass_FUwBn
      CBReadData_DemDataElementClass_Port0LowSignalQualityStatus: required-interface=CSDataServices_DemDataElementClass_Port0LowSignalQualityStatus
      CBReadData_DemDataElementClass_Port0CrcErrorCount: required-interface=CSDataServices_DemDataElementClass_Port0CrcErrorCount
      CBReadData_DemDataElementClass_EthSourceMacOfDuplicateIpAddress: required-interface=CSDataServices_DemDataElementClass_EthSourceMacOfDuplicateIpAddress
      CBReadData_DemDataElementClass_FileManipulated: required-interface=CSDataServices_DemDataElementClass_FileManipulated
      CBReadData_DemDataElementClass_SwtFehlerwert: required-interface=CSDataServices_DemDataElementClass_SwtFehlerwert
      CBReadData_DemDataElementClass_FUwTn: required-interface=CSDataServices_DemDataElementClass_FUwTn
      CBReadData_DemDataElementClass_EthDroppedFrameStatus: required-interface=CSDataServices_DemDataElementClass_EthDroppedFrameStatus
      CBReadData_DemDataElementClass_EthArpDiscardType: required-interface=CSDataServices_DemDataElementClass_EthArpDiscardType
      CBReadData_DemDataElementClass_SwtSwid: required-interface=CSDataServices_DemDataElementClass_SwtSwid
      CBReadData_DemDataElementClass_StartApplication: required-interface=CSDataServices_DemDataElementClass_StartApplication
      GeneralCBDataEvt: required-interface=GeneralCallbackEventDataChanged
    behavior DemMaster_0InternalBehavior: handle-termination-and-restart=NO-SUPPORT, included-data-type-set=data-type=[Dem_EventIdType, Dem_RatioIdType, Dem_EventStatusType, Dem_UdsStatusByteType, Dem_DTCFormatType, Dem_InitMonitorReasonType, Dem_OperationCycleStateType, Dem_DTCStatusMaskType, Dem_IndicatorStatusType, Dem_MaxDataValueType, Dem_DTCKindType, Dem_DTCGroupType, Dem_IumprDenomCondIdType, Dem_IumprDenomCondStatusType, Dem_DebounceResetStatusType, Dem_DebouncingStateType, Dem_IumprReadinessGroupType, Dem_DTRControlType, Dem_DTCSeverityType, Dem_MonitorStatusType]
      timing event Timer_Dem_MasterMainFunction: start-on-event=Dem_MasterMainFunction, period=0.01
      32 x operation invoked event:
        OpEventPostRunRequested_GetPostRunRequested_DemServices: start-on-event=PostRunRequested, operation=DemServices.GetPostRunRequested
        OpEventGetDTCStatusAvailabilityMask_GetDTCStatusAvailabilityMask_DemServices: start-on-event=GetDTCStatusAvailabilityMask, operation=DemServices.GetDTCStatusAvailabilityMask
        OpEventClearDTC_ClearDTC_ClearDTC_DemClient_DCM: start-on-event=ClearDTC, operation=ClearDTC_DemClient_DCM.ClearDTC
        OpEventClearDTC_ClearDTC_ClearDTC_DemClient_CDD: start-on-event=ClearDTC, operation=ClearDTC_DemClient_CDD.ClearDTC
        OpEventSelectDTC_SelectDTC_ClearDTC_DemClient_DCM: start-on-event=SelectDTC, operation=ClearDTC_DemClient_DCM.SelectDTC
        OpEventSelectDTC_SelectDTC_ClearDTC_DemClient_CDD: start-on-event=SelectDTC, operation=ClearDTC_DemClient_CDD.SelectDTC
        OpEventSetEnableCondition_SetEnableCondition_EnableCond_DemEnableCondition_StdDiag: start-on-event=SetEnableCondition, operation=EnableCond_DemEnableCondition_StdDiag.SetEnableCondition
        OpEventSetEnableCondition_SetEnableCondition_EnableCond_DemEnableCondition_Omc: start-on-event=SetEnableCondition, operation=EnableCond_DemEnableCondition_Omc.SetEnableCondition
        OpEventSetEnableCondition_SetEnableCondition_EnableCond_DemEnableCondition_Stm: start-on-event=SetEnableCondition, operation=EnableCond_DemEnableCondition_Stm.SetEnableCondition
        OpEventGetEventMemoryOverflow_GetEventMemoryOverflow_OverflowIndSecondaryMemory_DemClient_DCM: start-on-event=GetEventMemoryOverflow, operation=OverflowIndSecondaryMemory_DemClient_DCM.GetEventMemoryOverflow
        OpEventGetEventMemoryOverflow_GetEventMemoryOverflow_OverflowIndSecondaryMemory_DemClient_CDD: start-on-event=GetEventMemoryOverflow, operation=OverflowIndSecondaryMemory_DemClient_CDD.GetEventMemoryOverflow
        OpEventGetEventMemoryOverflow_GetEventMemoryOverflow_OverflowIndPrimaryMemory_DemClient_DCM: start-on-event=GetEventMemoryOverflow, operation=OverflowIndPrimaryMemory_DemClient_DCM.GetEventMemoryOverflow
        OpEventGetEventMemoryOverflow_GetEventMemoryOverflow_OverflowIndPrimaryMemory_DemClient_CDD: start-on-event=GetEventMemoryOverflow, operation=OverflowIndPrimaryMemory_DemClient_CDD.GetEventMemoryOverflow
        OpEventGetNumberOfEventMemoryEntries_GetNumberOfEventMemoryEntries_OverflowIndSecondaryMemory_DemClient_DCM: start-on-event=GetNumberOfEventMemoryEntries, operation=OverflowIndSecondaryMemory_DemClient_DCM.GetNumberOfEventMemoryEntries
        OpEventGetNumberOfEventMemoryEntries_GetNumberOfEventMemoryEntries_OverflowIndSecondaryMemory_DemClient_CDD: start-on-event=GetNumberOfEventMemoryEntries, operation=OverflowIndSecondaryMemory_DemClient_CDD.GetNumberOfEventMemoryEntries
        OpEventGetNumberOfEventMemoryEntries_GetNumberOfEventMemoryEntries_OverflowIndPrimaryMemory_DemClient_DCM: start-on-event=GetNumberOfEventMemoryEntries, operation=OverflowIndPrimaryMemory_DemClient_DCM.GetNumberOfEventMemoryEntries
        OpEventGetNumberOfEventMemoryEntries_GetNumberOfEventMemoryEntries_OverflowIndPrimaryMemory_DemClient_CDD: start-on-event=GetNumberOfEventMemoryEntries, operation=OverflowIndPrimaryMemory_DemClient_CDD.GetNumberOfEventMemoryEntries
        OpEventGetEventUdsStatus_GetEventUdsStatus_GeneralEventInfo: start-on-event=DemMaster_0InternalBehavior/GetEventUdsStatus, operation=GeneralEventInfo.GetEventUdsStatus
        OpEventGetEventStatus_GetEventStatus_GeneralEventInfo: start-on-event=DemMaster_0InternalBehavior/GetEventStatus, operation=GeneralEventInfo.GetEventStatus
        OpEventGetEventFailed_GetEventFailed_GeneralEventInfo: start-on-event=DemMaster_0InternalBehavior/GetEventFailed, operation=GeneralEventInfo.GetEventFailed
        OpEventGetEventTested_GetEventTested_GeneralEventInfo: start-on-event=DemMaster_0InternalBehavior/GetEventTested, operation=GeneralEventInfo.GetEventTested
        OpEventGetDTCOfEvent_GetDTCOfEvent_GeneralEventInfo: start-on-event=DemMaster_0InternalBehavior/GetDTCOfEvent, operation=GeneralEventInfo.GetDTCOfEvent
        OpEventGetFaultDetectionCounter_GetFaultDetectionCounter_GeneralEventInfo: start-on-event=DemMaster_0InternalBehavior/GetFaultDetectionCounter, operation=GeneralEventInfo.GetFaultDetectionCounter
        OpEventGetEventFreezeFrameDataEx_GetEventFreezeFrameDataEx_GeneralEventInfo: start-on-event=DemMaster_0InternalBehavior/GetEventFreezeFrameDataEx, operation=GeneralEventInfo.GetEventFreezeFrameDataEx
        OpEventGetEventExtendedDataRecordEx_GetEventExtendedDataRecordEx_GeneralEventInfo: start-on-event=DemMaster_0InternalBehavior/GetEventExtendedDataRecordEx, operation=GeneralEventInfo.GetEventExtendedDataRecordEx
        OpEventGetEventEnableCondition_GetEventEnableCondition_GeneralEventInfo: start-on-event=DemMaster_0InternalBehavior/GetEventEnableCondition, operation=GeneralEventInfo.GetEventEnableCondition
        OpEventGetDebouncingOfEvent_GetDebouncingOfEvent_GeneralEventInfo: start-on-event=DemMaster_0InternalBehavior/GetDebouncingOfEvent, operation=GeneralEventInfo.GetDebouncingOfEvent
        OpEventGetMonitorStatus_GetMonitorStatus_GeneralEventInfo: start-on-event=DemMaster_0InternalBehavior/GetMonitorStatus, operation=GeneralEventInfo.GetMonitorStatus
        OpEventGetOperationCycleState_GetOperationCycleState_OpCycle_NON_OBD: start-on-event=GetOperationCycleState, operation=OpCycle_NON_OBD.GetOperationCycleState
        OpEventGetOperationCycleState_GetOperationCycleState_OpCycle_ODB: start-on-event=GetOperationCycleState, operation=OpCycle_ODB.GetOperationCycleState
        OpEventSetOperationCycleState_SetOperationCycleState_OpCycle_NON_OBD: start-on-event=SetOperationCycleState, operation=OpCycle_NON_OBD.SetOperationCycleState
        OpEventSetOperationCycleState_SetOperationCycleState_OpCycle_ODB: start-on-event=SetOperationCycleState, operation=OpCycle_ODB.SetOperationCycleState
      port-api-options:
        enable-take-address=true, indirect-api=false, port=DemServices
        enable-take-address=true, indirect-api=false, port=CBClrEvt_VsmEventOpmode
        enable-take-address=true, indirect-api=false, port=CBClrEvt_CodingEventNotCoded
        {enable-take-address=true, indirect-api=false, port-defined-argument-value{value=1, value-type=uint8}, port=ClearDTC_DemClient_DCM}
        {enable-take-address=true, indirect-api=false, port-defined-argument-value{value=0, value-type=uint8}, port=ClearDTC_DemClient_CDD}
        {enable-take-address=true, indirect-api=false, port-defined-argument-value{value=2, value-type=uint8}, port=EnableCond_DemEnableCondition_StdDiag}
        {enable-take-address=true, indirect-api=false, port-defined-argument-value{value=1, value-type=uint8}, port=EnableCond_DemEnableCondition_Omc}
        {enable-take-address=true, indirect-api=false, port-defined-argument-value{value=3, value-type=uint8}, port=EnableCond_DemEnableCondition_Stm}
        {enable-take-address=true, indirect-api=false, port-arg-values=[{value=1, value-type=uint8}, {value=5, value-type=Dem_DTCOriginType}], port=OverflowIndSecondaryMemory_DemClient_DCM}
        {enable-take-address=true, indirect-api=false, port-arg-values=[{value=0, value-type=uint8}, {value=5, value-type=Dem_DTCOriginType}], port=OverflowIndSecondaryMemory_DemClient_CDD}
        {enable-take-address=true, indirect-api=false, port-arg-values=[{value=1, value-type=uint8}, {value=1, value-type=Dem_DTCOriginType}], port=OverflowIndPrimaryMemory_DemClient_DCM}
        {enable-take-address=true, indirect-api=false, port-arg-values=[{value=0, value-type=uint8}, {value=1, value-type=Dem_DTCOriginType}], port=OverflowIndPrimaryMemory_DemClient_CDD}
        enable-take-address=true, indirect-api=false, port=DemMaster_0/GeneralEventInfo
        {enable-take-address=true, indirect-api=false, port-defined-argument-value{value=0, value-type=Dem_OperationCycleIdType}, port=OpCycle_NON_OBD}
        {enable-take-address=true, indirect-api=false, port-defined-argument-value{value=1, value-type=Dem_OperationCycleIdType}, port=OpCycle_ODB}
        enable-take-address=true, indirect-api=false, port=CBReadData_DemDataElementClass_Systemzeit
        enable-take-address=true, indirect-api=false, port=CBReadData_DemDataElementClass_KmStand
        enable-take-address=true, indirect-api=false, port=CBReadData_DemDataElementClass_EthDiscardedArpEntry
        enable-take-address=true, indirect-api=false, port=CBReadData_DemDataElementClass_SwtVin
        enable-take-address=true, indirect-api=false, port=CBReadData_DemDataElementClass_FUwBn
        enable-take-address=true, indirect-api=false, port=CBReadData_DemDataElementClass_Port0LowSignalQualityStatus
        enable-take-address=true, indirect-api=false, port=CBReadData_DemDataElementClass_Port0CrcErrorCount
        enable-take-address=true, indirect-api=false, port=CBReadData_DemDataElementClass_EthSourceMacOfDuplicateIpAddress
        enable-take-address=true, indirect-api=false, port=CBReadData_DemDataElementClass_FileManipulated
        enable-take-address=true, indirect-api=false, port=CBReadData_DemDataElementClass_SwtFehlerwert
        enable-take-address=true, indirect-api=false, port=CBReadData_DemDataElementClass_FUwTn
        enable-take-address=true, indirect-api=false, port=CBReadData_DemDataElementClass_EthDroppedFrameStatus
        enable-take-address=true, indirect-api=false, port=CBReadData_DemDataElementClass_EthArpDiscardType
        enable-take-address=true, indirect-api=false, port=CBReadData_DemDataElementClass_SwtSwid
        enable-take-address=true, indirect-api=false, port=CBReadData_DemDataElementClass_StartApplication
        enable-take-address=true, indirect-api=false, port=GeneralCBDataEvt
      21 x runnable:
        Dem_MasterMainFunction
          18 x sync call, all with timeout=0:
            OpServerCallDem_MasterMainFunction_ClearEventAllowed_CBClrEvt_VsmEventOpmode: operation=CBClrEvt_VsmEventOpmode.ClearEventAllowed
            OpServerCallDem_MasterMainFunction_ClearEventAllowed_CBClrEvt_CodingEventNotCoded: operation=CBClrEvt_CodingEventNotCoded.ClearEventAllowed
            OpServerCallDem_MasterMainFunction_ReadData_CBReadData_DemDataElementClass_Systemzeit: operation=CBReadData_DemDataElementClass_Systemzeit.ReadData
            OpServerCallDem_MasterMainFunction_ReadData_CBReadData_DemDataElementClass_KmStand: operation=CBReadData_DemDataElementClass_KmStand.ReadData
            OpServerCallDem_MasterMainFunction_ReadData_CBReadData_DemDataElementClass_EthDiscardedArpEntry: operation=CBReadData_DemDataElementClass_EthDiscardedArpEntry.ReadData
            OpServerCallDem_MasterMainFunction_ReadData_CBReadData_DemDataElementClass_SwtVin: operation=CBReadData_DemDataElementClass_SwtVin.ReadData
            OpServerCallDem_MasterMainFunction_ReadData_CBReadData_DemDataElementClass_FUwBn: operation=CBReadData_DemDataElementClass_FUwBn.ReadData
            OpServerCallDem_MasterMainFunction_ReadData_CBReadData_DemDataElementClass_Port0LowSignalQualityStatus: operation=CBReadData_DemDataElementClass_Port0LowSignalQualityStatus.ReadData
            OpServerCallDem_MasterMainFunction_ReadData_CBReadData_DemDataElementClass_Port0CrcErrorCount: operation=CBReadData_DemDataElementClass_Port0CrcErrorCount.ReadData
            OpServerCallDem_MasterMainFunction_ReadData_CBReadData_DemDataElementClass_EthSourceMacOfDuplicateIpAddress: operation=CBReadData_DemDataElementClass_EthSourceMacOfDuplicateIpAddress.ReadData
            OpServerCallDem_MasterMainFunction_ReadData_CBReadData_DemDataElementClass_FileManipulated: operation=CBReadData_DemDataElementClass_FileManipulated.ReadData
            OpServerCallDem_MasterMainFunction_ReadData_CBReadData_DemDataElementClass_SwtFehlerwert: operation=CBReadData_DemDataElementClass_SwtFehlerwert.ReadData
            OpServerCallDem_MasterMainFunction_ReadData_CBReadData_DemDataElementClass_FUwTn: operation=CBReadData_DemDataElementClass_FUwTn.ReadData
            OpServerCallDem_MasterMainFunction_ReadData_CBReadData_DemDataElementClass_EthDroppedFrameStatus: operation=CBReadData_DemDataElementClass_EthDroppedFrameStatus.ReadData
            OpServerCallDem_MasterMainFunction_ReadData_CBReadData_DemDataElementClass_EthArpDiscardType: operation=CBReadData_DemDataElementClass_EthArpDiscardType.ReadData
            OpServerCallDem_MasterMainFunction_ReadData_CBReadData_DemDataElementClass_SwtSwid: operation=CBReadData_DemDataElementClass_SwtSwid.ReadData
            OpServerCallDem_MasterMainFunction_ReadData_CBReadData_DemDataElementClass_StartApplication: operation=CBReadData_DemDataElementClass_StartApplication.ReadData
            OpServerCallDem_MasterMainFunction_EventDataChanged_GeneralCBDataEvt: operation=GeneralCBDataEvt.EventDataChanged
        PostRunRequested: can-be-invoked-concurrently=true, symbol=Dem_PostRunRequested
        GetDTCStatusAvailabilityMask: can-be-invoked-concurrently=true, symbol=Dem_GetDTCStatusAvailabilityMask
        ClearDTC: can-be-invoked-concurrently=true, symbol=Dem_ClearDTC
        SelectDTC: can-be-invoked-concurrently=true, symbol=Dem_SelectDTC
        SetEnableCondition: can-be-invoked-concurrently=true, symbol=Dem_SetEnableCondition
        GetEventMemoryOverflow: can-be-invoked-concurrently=true, symbol=Dem_GetEventMemoryOverflow
        GetNumberOfEventMemoryEntries: can-be-invoked-concurrently=true, symbol=Dem_GetNumberOfEventMemoryEntries
        GetEventUdsStatus: can-be-invoked-concurrently=true, symbol=Dem_GetEventUdsStatus
        GetEventStatus: can-be-invoked-concurrently=true, symbol=Dem_GetEventUdsStatus
        GetEventFailed: can-be-invoked-concurrently=true, symbol=Dem_GetEventFailed
        GetEventTested: can-be-invoked-concurrently=true, symbol=Dem_GetEventTested
        GetDTCOfEvent: can-be-invoked-concurrently=true, symbol=Dem_GetDTCOfEvent
        GetFaultDetectionCounter: can-be-invoked-concurrently=true, symbol=Dem_GetFaultDetectionCounter
        GetEventFreezeFrameDataEx: can-be-invoked-concurrently=true, symbol=Dem_GetEventFreezeFrameDataEx
        GetEventExtendedDataRecordEx: can-be-invoked-concurrently=true, symbol=Dem_GetEventExtendedDataRecordEx
        GetEventEnableCondition: can-be-invoked-concurrently=true, symbol=Dem_GetEventEnableCondition
        GetDebouncingOfEvent: can-be-invoked-concurrently=true, symbol=Dem_GetDebouncingOfEvent
        GetMonitorStatus: can-be-invoked-concurrently=true, symbol=Dem_GetMonitorStatus
        GetOperationCycleState: can-be-invoked-concurrently=true, symbol=Dem_GetOperationCycleState
        SetOperationCycleState: can-be-invoked-concurrently=true, symbol=Dem_SetOperationCycleState
  swc implementation DemMaster_0Implementation: programming-language=C, behavior=DemMaster_0InternalBehavior
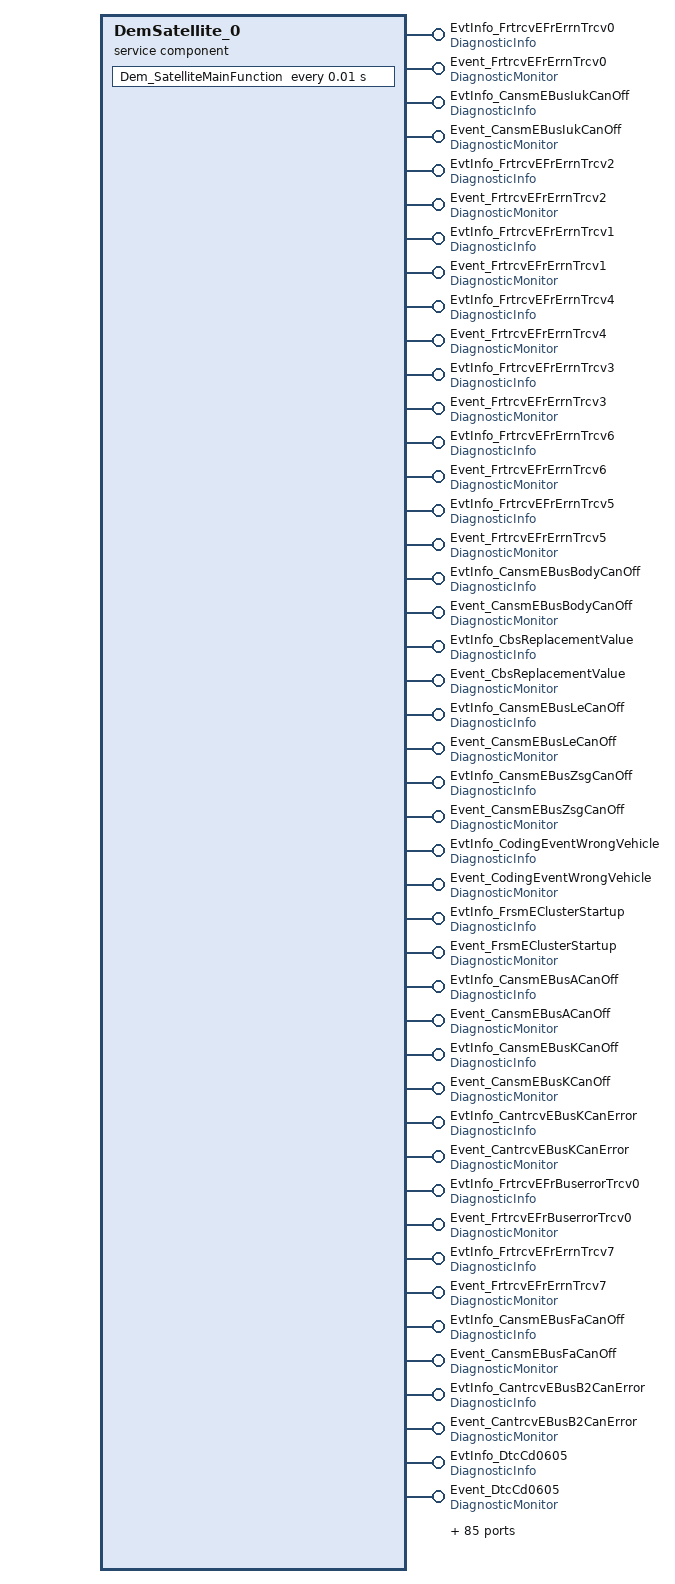
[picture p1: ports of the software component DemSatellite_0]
  service sw component type DemSatellite_0: category=SERVICE_COMPONENT
    129 x provide port:
      EvtInfo_FrtrcvEFrErrnTrcv0: provided-interface=DiagnosticInfo
      Event_FrtrcvEFrErrnTrcv0: provided-interface=DiagnosticMonitor
      EvtInfo_CansmEBusIukCanOff: provided-interface=DiagnosticInfo
      Event_CansmEBusIukCanOff: provided-interface=DiagnosticMonitor
      EvtInfo_FrtrcvEFrErrnTrcv2: provided-interface=DiagnosticInfo
      Event_FrtrcvEFrErrnTrcv2: provided-interface=DiagnosticMonitor
      EvtInfo_FrtrcvEFrErrnTrcv1: provided-interface=DiagnosticInfo
      Event_FrtrcvEFrErrnTrcv1: provided-interface=DiagnosticMonitor
      EvtInfo_FrtrcvEFrErrnTrcv4: provided-interface=DiagnosticInfo
      Event_FrtrcvEFrErrnTrcv4: provided-interface=DiagnosticMonitor
      EvtInfo_FrtrcvEFrErrnTrcv3: provided-interface=DiagnosticInfo
      Event_FrtrcvEFrErrnTrcv3: provided-interface=DiagnosticMonitor
      EvtInfo_FrtrcvEFrErrnTrcv6: provided-interface=DiagnosticInfo
      Event_FrtrcvEFrErrnTrcv6: provided-interface=DiagnosticMonitor
      EvtInfo_FrtrcvEFrErrnTrcv5: provided-interface=DiagnosticInfo
      Event_FrtrcvEFrErrnTrcv5: provided-interface=DiagnosticMonitor
      EvtInfo_CansmEBusBodyCanOff: provided-interface=DiagnosticInfo
      Event_CansmEBusBodyCanOff: provided-interface=DiagnosticMonitor
      EvtInfo_CbsReplacementValue: provided-interface=DiagnosticInfo
      Event_CbsReplacementValue: provided-interface=DiagnosticMonitor
      EvtInfo_CansmEBusLeCanOff: provided-interface=DiagnosticInfo
      Event_CansmEBusLeCanOff: provided-interface=DiagnosticMonitor
      EvtInfo_CansmEBusZsgCanOff: provided-interface=DiagnosticInfo
      Event_CansmEBusZsgCanOff: provided-interface=DiagnosticMonitor
      EvtInfo_CodingEventWrongVehicle: provided-interface=DiagnosticInfo
      Event_CodingEventWrongVehicle: provided-interface=DiagnosticMonitor
      EvtInfo_FrsmEClusterStartup: provided-interface=DiagnosticInfo
      Event_FrsmEClusterStartup: provided-interface=DiagnosticMonitor
      EvtInfo_CansmEBusACanOff: provided-interface=DiagnosticInfo
      Event_CansmEBusACanOff: provided-interface=DiagnosticMonitor
      EvtInfo_CansmEBusKCanOff: provided-interface=DiagnosticInfo
      Event_CansmEBusKCanOff: provided-interface=DiagnosticMonitor
      EvtInfo_CantrcvEBusKCanError: provided-interface=DiagnosticInfo
      Event_CantrcvEBusKCanError: provided-interface=DiagnosticMonitor
      EvtInfo_FrtrcvEFrBuserrorTrcv0: provided-interface=DiagnosticInfo
      Event_FrtrcvEFrBuserrorTrcv0: provided-interface=DiagnosticMonitor
      EvtInfo_FrtrcvEFrErrnTrcv7: provided-interface=DiagnosticInfo
      Event_FrtrcvEFrErrnTrcv7: provided-interface=DiagnosticMonitor
      EvtInfo_CansmEBusFaCanOff: provided-interface=DiagnosticInfo
      Event_CansmEBusFaCanOff: provided-interface=DiagnosticMonitor
      EvtInfo_CantrcvEBusB2CanError: provided-interface=DiagnosticInfo
      Event_CantrcvEBusB2CanError: provided-interface=DiagnosticMonitor
      EvtInfo_DtcCd0605: provided-interface=DiagnosticInfo
      Event_DtcCd0605: provided-interface=DiagnosticMonitor
      EvtInfo_DtcCd0606: provided-interface=DiagnosticInfo
      Event_DtcCd0606: provided-interface=DiagnosticMonitor
      EvtInfo_DtcCd0607: provided-interface=DiagnosticInfo
      Event_DtcCd0607: provided-interface=DiagnosticMonitor
      EvtInfo_PiaEIoError: provided-interface=DiagnosticInfo
      Event_PiaEIoError: provided-interface=DiagnosticMonitor
      EvtInfo_DtcCd0601: provided-interface=DiagnosticInfo
      Event_DtcCd0601: provided-interface=DiagnosticMonitor
      EvtInfo_SwtExternalCheckFailure: provided-interface=DiagnosticInfo
      Event_SwtExternalCheckFailure: provided-interface=DiagnosticMonitor
      EvtInfo_CantrcvEBusBodyCanError: provided-interface=DiagnosticInfo
      Event_CantrcvEBusBodyCanError: provided-interface=DiagnosticMonitor
      EvtInfo_CantrcvEBusIukError: provided-interface=DiagnosticInfo
      Event_CantrcvEBusIukError: provided-interface=DiagnosticMonitor
      EvtInfo_SwtInternalCheckFailure: provided-interface=DiagnosticInfo
      Event_SwtInternalCheckFailure: provided-interface=DiagnosticMonitor
      EvtInfo_DmTestAppl: provided-interface=DiagnosticInfo
      Event_DmTestAppl: provided-interface=DiagnosticMonitor
      EvtInfo_Dtc000032: provided-interface=DiagnosticInfo
      Event_Dtc000032: provided-interface=DiagnosticMonitor
      EvtInfo_Dtc000031: provided-interface=DiagnosticInfo
      Event_Dtc000031: provided-interface=DiagnosticMonitor
      EvtInfo_FrsmEClusterSyncLoss: provided-interface=DiagnosticInfo
      Event_FrsmEClusterSyncLoss: provided-interface=DiagnosticMonitor
      EvtInfo_Dtc000030: provided-interface=DiagnosticInfo
      Event_Dtc000030: provided-interface=DiagnosticMonitor
      EvtInfo_Dtc000034: provided-interface=DiagnosticInfo
      Event_Dtc000034: provided-interface=DiagnosticMonitor
      EvtInfo_Dtc000033: provided-interface=DiagnosticInfo
      Event_Dtc000033: provided-interface=DiagnosticMonitor
      EvtInfo_Undervoltage: provided-interface=DiagnosticInfo
      Event_Undervoltage: provided-interface=DiagnosticMonitor
      EvtInfo_CodingEventTransactionFailed: provided-interface=DiagnosticInfo
      Event_CodingEventTransactionFailed: provided-interface=DiagnosticMonitor
      EvtInfo_FrifENitChA: provided-interface=DiagnosticInfo
      Event_FrifENitChA: provided-interface=DiagnosticMonitor
      EvtInfo_CansmEBusLpCanOff: provided-interface=DiagnosticInfo
      Event_CansmEBusLpCanOff: provided-interface=DiagnosticMonitor
      EvtInfo_NVM_E_HARDWARE: provided-interface=DiagnosticInfo
      EvtInfo_VsmEventOpmode: provided-interface=DiagnosticInfo
      Event_VsmEventOpmode: provided-interface=DiagnosticMonitor
      EvtInfo_LIN_E_TIMEOUT: provided-interface=DiagnosticInfo
      EvtInfo_CantrcvEBusACanError: provided-interface=DiagnosticInfo
      Event_CantrcvEBusACanError: provided-interface=DiagnosticMonitor
      EvtInfo_UDPNM_E_TCPIP_TRANSMIT_ERROR: provided-interface=DiagnosticInfo
      EvtInfo_DmTestCom: provided-interface=DiagnosticInfo
      Event_DmTestCom: provided-interface=DiagnosticMonitor
      EvtInfo_CodingEventSignatureError: provided-interface=DiagnosticInfo
      Event_CodingEventSignatureError: provided-interface=DiagnosticMonitor
      EvtInfo_CodingEventUnqualifiedData: provided-interface=DiagnosticInfo
      Event_CodingEventUnqualifiedData: provided-interface=DiagnosticMonitor
      EvtInfo_CodingEventInvalidData: provided-interface=DiagnosticInfo
      Event_CodingEventInvalidData: provided-interface=DiagnosticMonitor
      EvtInfo_CansmEBusB2CanOff: provided-interface=DiagnosticInfo
      Event_CansmEBusB2CanOff: provided-interface=DiagnosticMonitor
      EvtInfo_Overvoltage: provided-interface=DiagnosticInfo
      Event_Overvoltage: provided-interface=DiagnosticMonitor
      EvtInfo_CodingEventNotCoded: provided-interface=DiagnosticInfo
      Event_CodingEventNotCoded: provided-interface=DiagnosticMonitor
      EvtInfo_FrifEAcsChA: provided-interface=DiagnosticInfo
      Event_FrifEAcsChA: provided-interface=DiagnosticMonitor
      EvtInfo_CantrcvEBusFaCanError: provided-interface=DiagnosticInfo
      Event_CantrcvEBusFaCanError: provided-interface=DiagnosticMonitor
      EvtInfo_CantrcvEBusLeCanError: provided-interface=DiagnosticInfo
      Event_CantrcvEBusLeCanError: provided-interface=DiagnosticMonitor
      EvtInfo_CantrcvEBusLpCanError: provided-interface=DiagnosticInfo
      Event_CantrcvEBusLpCanError: provided-interface=DiagnosticMonitor
      EvtInfo_CantrcvEBusZsgCanError: provided-interface=DiagnosticInfo
      Event_CantrcvEBusZsgCanError: provided-interface=DiagnosticMonitor
      EvtInfo_EthSignalQualityLow: provided-interface=DiagnosticInfo
      Event_EthSignalQualityLow: provided-interface=DiagnosticMonitor
      EvtInfo_DemEventParameter_FlsConfigSet_FLS_E_COMPARE_FAILED: provided-interface=DiagnosticInfo
      EvtInfo_DemEventParameter_FlsConfigSet_FLS_E_ERASE_FAILED: provided-interface=DiagnosticInfo
      EvtInfo_DemEventParameter_FlsConfigSet_FLS_E_READ_FAILED: provided-interface=DiagnosticInfo
      EvtInfo_DemEventParameter_FlsConfigSet_FLS_E_WRITE_FAILED: provided-interface=DiagnosticInfo
      EvtInfo_DemEventParameter_FlsConfigSet_FLS_E_READ_DED_FAILED: provided-interface=DiagnosticInfo
      EvtInfo_DemEventParameter_FlsConfigSet_FLS_E_UNEXPECTED_FLASH_ID: provided-interface=DiagnosticInfo
      EvtInfo_DemEventParameter_FlsConfigSet_MCU_E_CLOCK_FAILED: provided-interface=DiagnosticInfo
      EvtInfo_DemEventParameter_FlsConfigSet_MCU_E_HW_FAILED: provided-interface=DiagnosticInfo
      EvtInfo_DemEventParameter_FlsConfigSet_MCU_E_STARTUP_FAILED: provided-interface=DiagnosticInfo
      EvtInfo_DemEventParameter_FlsConfigSet_FLS_E_ECC_FAILED: provided-interface=DiagnosticInfo
      EvtInfo_DemEventParameter_FlsConfigSet_FLS_E_VRFY_FAILED: provided-interface=DiagnosticInfo
      EvtInfo_DemEventParameter_FlsConfigSet_FLS_E_INT_FAILED: provided-interface=DiagnosticInfo
      EvtInfo_DemEventParameter_FlsConfigSet_FLS_E_HW_FAILED: provided-interface=DiagnosticInfo
      GeneralEventInfo: provided-interface=GeneralDiagnosticInfo
    behavior DemSatellite_0InternalBehavior: handle-termination-and-restart=NO-SUPPORT, included-data-type-set=data-type=[Dem_EventIdType, Dem_RatioIdType, Dem_EventStatusType, Dem_UdsStatusByteType, Dem_DTCFormatType, Dem_InitMonitorReasonType, Dem_OperationCycleStateType, Dem_DTCStatusMaskType, Dem_IndicatorStatusType, Dem_MaxDataValueType, Dem_DTCKindType, Dem_DTCGroupType, Dem_IumprDenomCondIdType, Dem_IumprDenomCondStatusType, Dem_DebounceResetStatusType, Dem_DebouncingStateType, Dem_IumprReadinessGroupType, Dem_DTRControlType, Dem_DTCSeverityType, Dem_MonitorStatusType]
      timing event Timer_Dem_SatelliteMainFunction: start-on-event=Dem_SatelliteMainFunction, period=0.01
      1419 x operation invoked event:
        OpEventGetEventUdsStatus_GetEventUdsStatus_EvtInfo_FrtrcvEFrErrnTrcv0: start-on-event=DemSatellite_0InternalBehavior/GetEventUdsStatus, operation=EvtInfo_FrtrcvEFrErrnTrcv0.GetEventUdsStatus
        OpEventGetEventUdsStatus_GetEventUdsStatus_Event_FrtrcvEFrErrnTrcv0: start-on-event=DemSatellite_0InternalBehavior/GetEventUdsStatus, operation=Event_FrtrcvEFrErrnTrcv0.GetEventUdsStatus
        OpEventGetEventUdsStatus_GetEventUdsStatus_EvtInfo_CansmEBusIukCanOff: start-on-event=DemSatellite_0InternalBehavior/GetEventUdsStatus, operation=EvtInfo_CansmEBusIukCanOff.GetEventUdsStatus
        OpEventGetEventUdsStatus_GetEventUdsStatus_Event_CansmEBusIukCanOff: start-on-event=DemSatellite_0InternalBehavior/GetEventUdsStatus, operation=Event_CansmEBusIukCanOff.GetEventUdsStatus
        OpEventGetEventUdsStatus_GetEventUdsStatus_EvtInfo_FrtrcvEFrErrnTrcv2: start-on-event=DemSatellite_0InternalBehavior/GetEventUdsStatus, operation=EvtInfo_FrtrcvEFrErrnTrcv2.GetEventUdsStatus
        OpEventGetEventUdsStatus_GetEventUdsStatus_Event_FrtrcvEFrErrnTrcv2: start-on-event=DemSatellite_0InternalBehavior/GetEventUdsStatus, operation=Event_FrtrcvEFrErrnTrcv2.GetEventUdsStatus
        OpEventGetEventUdsStatus_GetEventUdsStatus_EvtInfo_FrtrcvEFrErrnTrcv1: start-on-event=DemSatellite_0InternalBehavior/GetEventUdsStatus, operation=EvtInfo_FrtrcvEFrErrnTrcv1.GetEventUdsStatus
        OpEventGetEventUdsStatus_GetEventUdsStatus_Event_FrtrcvEFrErrnTrcv1: start-on-event=DemSatellite_0InternalBehavior/GetEventUdsStatus, operation=Event_FrtrcvEFrErrnTrcv1.GetEventUdsStatus
        OpEventGetEventUdsStatus_GetEventUdsStatus_EvtInfo_FrtrcvEFrErrnTrcv4: start-on-event=DemSatellite_0InternalBehavior/GetEventUdsStatus, operation=EvtInfo_FrtrcvEFrErrnTrcv4.GetEventUdsStatus
        OpEventGetEventUdsStatus_GetEventUdsStatus_Event_FrtrcvEFrErrnTrcv4: start-on-event=DemSatellite_0InternalBehavior/GetEventUdsStatus, operation=Event_FrtrcvEFrErrnTrcv4.GetEventUdsStatus
        OpEventGetEventUdsStatus_GetEventUdsStatus_EvtInfo_FrtrcvEFrErrnTrcv3: start-on-event=DemSatellite_0InternalBehavior/GetEventUdsStatus, operation=EvtInfo_FrtrcvEFrErrnTrcv3.GetEventUdsStatus
        OpEventGetEventUdsStatus_GetEventUdsStatus_Event_FrtrcvEFrErrnTrcv3: start-on-event=DemSatellite_0InternalBehavior/GetEventUdsStatus, operation=Event_FrtrcvEFrErrnTrcv3.GetEventUdsStatus
        OpEventGetEventUdsStatus_GetEventUdsStatus_EvtInfo_FrtrcvEFrErrnTrcv6: start-on-event=DemSatellite_0InternalBehavior/GetEventUdsStatus, operation=EvtInfo_FrtrcvEFrErrnTrcv6.GetEventUdsStatus
        OpEventGetEventUdsStatus_GetEventUdsStatus_Event_FrtrcvEFrErrnTrcv6: start-on-event=DemSatellite_0InternalBehavior/GetEventUdsStatus, operation=Event_FrtrcvEFrErrnTrcv6.GetEventUdsStatus
        OpEventGetEventUdsStatus_GetEventUdsStatus_EvtInfo_FrtrcvEFrErrnTrcv5: start-on-event=DemSatellite_0InternalBehavior/GetEventUdsStatus, operation=EvtInfo_FrtrcvEFrErrnTrcv5.GetEventUdsStatus
        OpEventGetEventUdsStatus_GetEventUdsStatus_Event_FrtrcvEFrErrnTrcv5: start-on-event=DemSatellite_0InternalBehavior/GetEventUdsStatus, operation=Event_FrtrcvEFrErrnTrcv5.GetEventUdsStatus
        OpEventGetEventUdsStatus_GetEventUdsStatus_EvtInfo_CansmEBusBodyCanOff: start-on-event=DemSatellite_0InternalBehavior/GetEventUdsStatus, operation=EvtInfo_CansmEBusBodyCanOff.GetEventUdsStatus
        OpEventGetEventUdsStatus_GetEventUdsStatus_Event_CansmEBusBodyCanOff: start-on-event=DemSatellite_0InternalBehavior/GetEventUdsStatus, operation=Event_CansmEBusBodyCanOff.GetEventUdsStatus
        OpEventGetEventUdsStatus_GetEventUdsStatus_EvtInfo_CbsReplacementValue: start-on-event=DemSatellite_0InternalBehavior/GetEventUdsStatus, operation=EvtInfo_CbsReplacementValue.GetEventUdsStatus
        OpEventGetEventUdsStatus_GetEventUdsStatus_Event_CbsReplacementValue: start-on-event=DemSatellite_0InternalBehavior/GetEventUdsStatus, operation=Event_CbsReplacementValue.GetEventUdsStatus
        OpEventGetEventUdsStatus_GetEventUdsStatus_EvtInfo_CansmEBusLeCanOff: start-on-event=DemSatellite_0InternalBehavior/GetEventUdsStatus, operation=EvtInfo_CansmEBusLeCanOff.GetEventUdsStatus
        OpEventGetEventUdsStatus_GetEventUdsStatus_Event_CansmEBusLeCanOff: start-on-event=DemSatellite_0InternalBehavior/GetEventUdsStatus, operation=Event_CansmEBusLeCanOff.GetEventUdsStatus
        OpEventGetEventUdsStatus_GetEventUdsStatus_EvtInfo_CansmEBusZsgCanOff: start-on-event=DemSatellite_0InternalBehavior/GetEventUdsStatus, operation=EvtInfo_CansmEBusZsgCanOff.GetEventUdsStatus
        OpEventGetEventUdsStatus_GetEventUdsStatus_Event_CansmEBusZsgCanOff: start-on-event=DemSatellite_0InternalBehavior/GetEventUdsStatus, operation=Event_CansmEBusZsgCanOff.GetEventUdsStatus
        OpEventGetEventUdsStatus_GetEventUdsStatus_EvtInfo_CodingEventWrongVehicle: start-on-event=DemSatellite_0InternalBehavior/GetEventUdsStatus, operation=EvtInfo_CodingEventWrongVehicle.GetEventUdsStatus
        OpEventGetEventUdsStatus_GetEventUdsStatus_Event_CodingEventWrongVehicle: start-on-event=DemSatellite_0InternalBehavior/GetEventUdsStatus, operation=Event_CodingEventWrongVehicle.GetEventUdsStatus
        OpEventGetEventUdsStatus_GetEventUdsStatus_EvtInfo_FrsmEClusterStartup: start-on-event=DemSatellite_0InternalBehavior/GetEventUdsStatus, operation=EvtInfo_FrsmEClusterStartup.GetEventUdsStatus
        OpEventGetEventUdsStatus_GetEventUdsStatus_Event_FrsmEClusterStartup: start-on-event=DemSatellite_0InternalBehavior/GetEventUdsStatus, operation=Event_FrsmEClusterStartup.GetEventUdsStatus
        OpEventGetEventUdsStatus_GetEventUdsStatus_EvtInfo_CansmEBusACanOff: start-on-event=DemSatellite_0InternalBehavior/GetEventUdsStatus, operation=EvtInfo_CansmEBusACanOff.GetEventUdsStatus
        OpEventGetEventUdsStatus_GetEventUdsStatus_Event_CansmEBusACanOff: start-on-event=DemSatellite_0InternalBehavior/GetEventUdsStatus, operation=Event_CansmEBusACanOff.GetEventUdsStatus
        OpEventGetEventUdsStatus_GetEventUdsStatus_EvtInfo_CansmEBusKCanOff: start-on-event=DemSatellite_0InternalBehavior/GetEventUdsStatus, operation=EvtInfo_CansmEBusKCanOff.GetEventUdsStatus
        OpEventGetEventUdsStatus_GetEventUdsStatus_Event_CansmEBusKCanOff: start-on-event=DemSatellite_0InternalBehavior/GetEventUdsStatus, operation=Event_CansmEBusKCanOff.GetEventUdsStatus
        OpEventGetEventUdsStatus_GetEventUdsStatus_EvtInfo_CantrcvEBusKCanError: start-on-event=DemSatellite_0InternalBehavior/GetEventUdsStatus, operation=EvtInfo_CantrcvEBusKCanError.GetEventUdsStatus
        OpEventGetEventUdsStatus_GetEventUdsStatus_Event_CantrcvEBusKCanError: start-on-event=DemSatellite_0InternalBehavior/GetEventUdsStatus, operation=Event_CantrcvEBusKCanError.GetEventUdsStatus
        OpEventGetEventUdsStatus_GetEventUdsStatus_EvtInfo_FrtrcvEFrBuserrorTrcv0: start-on-event=DemSatellite_0InternalBehavior/GetEventUdsStatus, operation=EvtInfo_FrtrcvEFrBuserrorTrcv0.GetEventUdsStatus
        OpEventGetEventUdsStatus_GetEventUdsStatus_Event_FrtrcvEFrBuserrorTrcv0: start-on-event=DemSatellite_0InternalBehavior/GetEventUdsStatus, operation=Event_FrtrcvEFrBuserrorTrcv0.GetEventUdsStatus
        OpEventGetEventUdsStatus_GetEventUdsStatus_EvtInfo_FrtrcvEFrErrnTrcv7: start-on-event=DemSatellite_0InternalBehavior/GetEventUdsStatus, operation=EvtInfo_FrtrcvEFrErrnTrcv7.GetEventUdsStatus
        OpEventGetEventUdsStatus_GetEventUdsStatus_Event_FrtrcvEFrErrnTrcv7: start-on-event=DemSatellite_0InternalBehavior/GetEventUdsStatus, operation=Event_FrtrcvEFrErrnTrcv7.GetEventUdsStatus
        OpEventGetEventUdsStatus_GetEventUdsStatus_EvtInfo_CansmEBusFaCanOff: start-on-event=DemSatellite_0InternalBehavior/GetEventUdsStatus, operation=EvtInfo_CansmEBusFaCanOff.GetEventUdsStatus
        OpEventGetEventUdsStatus_GetEventUdsStatus_Event_CansmEBusFaCanOff: start-on-event=DemSatellite_0InternalBehavior/GetEventUdsStatus, operation=Event_CansmEBusFaCanOff.GetEventUdsStatus
        OpEventGetEventUdsStatus_GetEventUdsStatus_EvtInfo_CantrcvEBusB2CanError: start-on-event=DemSatellite_0InternalBehavior/GetEventUdsStatus, operation=EvtInfo_CantrcvEBusB2CanError.GetEventUdsStatus
        OpEventGetEventUdsStatus_GetEventUdsStatus_Event_CantrcvEBusB2CanError: start-on-event=DemSatellite_0InternalBehavior/GetEventUdsStatus, operation=Event_CantrcvEBusB2CanError.GetEventUdsStatus
        OpEventGetEventUdsStatus_GetEventUdsStatus_EvtInfo_DtcCd0605: start-on-event=DemSatellite_0InternalBehavior/GetEventUdsStatus, operation=EvtInfo_DtcCd0605.GetEventUdsStatus
        OpEventGetEventUdsStatus_GetEventUdsStatus_Event_DtcCd0605: start-on-event=DemSatellite_0InternalBehavior/GetEventUdsStatus, operation=Event_DtcCd0605.GetEventUdsStatus
        OpEventGetEventUdsStatus_GetEventUdsStatus_EvtInfo_DtcCd0606: start-on-event=DemSatellite_0InternalBehavior/GetEventUdsStatus, operation=EvtInfo_DtcCd0606.GetEventUdsStatus
        OpEventGetEventUdsStatus_GetEventUdsStatus_Event_DtcCd0606: start-on-event=DemSatellite_0InternalBehavior/GetEventUdsStatus, operation=Event_DtcCd0606.GetEventUdsStatus
        OpEventGetEventUdsStatus_GetEventUdsStatus_EvtInfo_DtcCd0607: start-on-event=DemSatellite_0InternalBehavior/GetEventUdsStatus, operation=EvtInfo_DtcCd0607.GetEventUdsStatus
        OpEventGetEventUdsStatus_GetEventUdsStatus_Event_DtcCd0607: start-on-event=DemSatellite_0InternalBehavior/GetEventUdsStatus, operation=Event_DtcCd0607.GetEventUdsStatus
        OpEventGetEventUdsStatus_GetEventUdsStatus_EvtInfo_PiaEIoError: start-on-event=DemSatellite_0InternalBehavior/GetEventUdsStatus, operation=EvtInfo_PiaEIoError.GetEventUdsStatus
        OpEventGetEventUdsStatus_GetEventUdsStatus_Event_PiaEIoError: start-on-event=DemSatellite_0InternalBehavior/GetEventUdsStatus, operation=Event_PiaEIoError.GetEventUdsStatus
        OpEventGetEventUdsStatus_GetEventUdsStatus_EvtInfo_DtcCd0601: start-on-event=DemSatellite_0InternalBehavior/GetEventUdsStatus, operation=EvtInfo_DtcCd0601.GetEventUdsStatus
        OpEventGetEventUdsStatus_GetEventUdsStatus_Event_DtcCd0601: start-on-event=DemSatellite_0InternalBehavior/GetEventUdsStatus, operation=Event_DtcCd0601.GetEventUdsStatus
        OpEventGetEventUdsStatus_GetEventUdsStatus_EvtInfo_SwtExternalCheckFailure: start-on-event=DemSatellite_0InternalBehavior/GetEventUdsStatus, operation=EvtInfo_SwtExternalCheckFailure.GetEventUdsStatus
        OpEventGetEventUdsStatus_GetEventUdsStatus_Event_SwtExternalCheckFailure: start-on-event=DemSatellite_0InternalBehavior/GetEventUdsStatus, operation=Event_SwtExternalCheckFailure.GetEventUdsStatus
        OpEventGetEventUdsStatus_GetEventUdsStatus_EvtInfo_CantrcvEBusBodyCanError: start-on-event=DemSatellite_0InternalBehavior/GetEventUdsStatus, operation=EvtInfo_CantrcvEBusBodyCanError.GetEventUdsStatus
        OpEventGetEventUdsStatus_GetEventUdsStatus_Event_CantrcvEBusBodyCanError: start-on-event=DemSatellite_0InternalBehavior/GetEventUdsStatus, operation=Event_CantrcvEBusBodyCanError.GetEventUdsStatus
        OpEventGetEventUdsStatus_GetEventUdsStatus_EvtInfo_CantrcvEBusIukError: start-on-event=DemSatellite_0InternalBehavior/GetEventUdsStatus, operation=EvtInfo_CantrcvEBusIukError.GetEventUdsStatus
        OpEventGetEventUdsStatus_GetEventUdsStatus_Event_CantrcvEBusIukError: start-on-event=DemSatellite_0InternalBehavior/GetEventUdsStatus, operation=Event_CantrcvEBusIukError.GetEventUdsStatus
        OpEventGetEventUdsStatus_GetEventUdsStatus_EvtInfo_SwtInternalCheckFailure: start-on-event=DemSatellite_0InternalBehavior/GetEventUdsStatus, operation=EvtInfo_SwtInternalCheckFailure.GetEventUdsStatus
        OpEventGetEventUdsStatus_GetEventUdsStatus_Event_SwtInternalCheckFailure: start-on-event=DemSatellite_0InternalBehavior/GetEventUdsStatus, operation=Event_SwtInternalCheckFailure.GetEventUdsStatus
        OpEventGetEventUdsStatus_GetEventUdsStatus_EvtInfo_DmTestAppl: start-on-event=DemSatellite_0InternalBehavior/GetEventUdsStatus, operation=EvtInfo_DmTestAppl.GetEventUdsStatus
        OpEventGetEventUdsStatus_GetEventUdsStatus_Event_DmTestAppl: start-on-event=DemSatellite_0InternalBehavior/GetEventUdsStatus, operation=Event_DmTestAppl.GetEventUdsStatus
        OpEventGetEventUdsStatus_GetEventUdsStatus_EvtInfo_Dtc000032: start-on-event=DemSatellite_0InternalBehavior/GetEventUdsStatus, operation=EvtInfo_Dtc000032.GetEventUdsStatus
        OpEventGetEventUdsStatus_GetEventUdsStatus_Event_Dtc000032: start-on-event=DemSatellite_0InternalBehavior/GetEventUdsStatus, operation=Event_Dtc000032.GetEventUdsStatus
        OpEventGetEventUdsStatus_GetEventUdsStatus_EvtInfo_Dtc000031: start-on-event=DemSatellite_0InternalBehavior/GetEventUdsStatus, operation=EvtInfo_Dtc000031.GetEventUdsStatus
        OpEventGetEventUdsStatus_GetEventUdsStatus_Event_Dtc000031: start-on-event=DemSatellite_0InternalBehavior/GetEventUdsStatus, operation=Event_Dtc000031.GetEventUdsStatus
        OpEventGetEventUdsStatus_GetEventUdsStatus_EvtInfo_FrsmEClusterSyncLoss: start-on-event=DemSatellite_0InternalBehavior/GetEventUdsStatus, operation=EvtInfo_FrsmEClusterSyncLoss.GetEventUdsStatus
        OpEventGetEventUdsStatus_GetEventUdsStatus_Event_FrsmEClusterSyncLoss: start-on-event=DemSatellite_0InternalBehavior/GetEventUdsStatus, operation=Event_FrsmEClusterSyncLoss.GetEventUdsStatus
        OpEventGetEventUdsStatus_GetEventUdsStatus_EvtInfo_Dtc000030: start-on-event=DemSatellite_0InternalBehavior/GetEventUdsStatus, operation=EvtInfo_Dtc000030.GetEventUdsStatus
        OpEventGetEventUdsStatus_GetEventUdsStatus_Event_Dtc000030: start-on-event=DemSatellite_0InternalBehavior/GetEventUdsStatus, operation=Event_Dtc000030.GetEventUdsStatus
        OpEventGetEventUdsStatus_GetEventUdsStatus_EvtInfo_Dtc000034: start-on-event=DemSatellite_0InternalBehavior/GetEventUdsStatus, operation=EvtInfo_Dtc000034.GetEventUdsStatus
        OpEventGetEventUdsStatus_GetEventUdsStatus_Event_Dtc000034: start-on-event=DemSatellite_0InternalBehavior/GetEventUdsStatus, operation=Event_Dtc000034.GetEventUdsStatus
        OpEventGetEventUdsStatus_GetEventUdsStatus_EvtInfo_Dtc000033: start-on-event=DemSatellite_0InternalBehavior/GetEventUdsStatus, operation=EvtInfo_Dtc000033.GetEventUdsStatus
        OpEventGetEventUdsStatus_GetEventUdsStatus_Event_Dtc000033: start-on-event=DemSatellite_0InternalBehavior/GetEventUdsStatus, operation=Event_Dtc000033.GetEventUdsStatus
        OpEventGetEventUdsStatus_GetEventUdsStatus_EvtInfo_Undervoltage: start-on-event=DemSatellite_0InternalBehavior/GetEventUdsStatus, operation=EvtInfo_Undervoltage.GetEventUdsStatus
        OpEventGetEventUdsStatus_GetEventUdsStatus_Event_Undervoltage: start-on-event=DemSatellite_0InternalBehavior/GetEventUdsStatus, operation=Event_Undervoltage.GetEventUdsStatus
        OpEventGetEventUdsStatus_GetEventUdsStatus_EvtInfo_CodingEventTransactionFailed: start-on-event=DemSatellite_0InternalBehavior/GetEventUdsStatus, operation=EvtInfo_CodingEventTransactionFailed.GetEventUdsStatus
        OpEventGetEventUdsStatus_GetEventUdsStatus_Event_CodingEventTransactionFailed: start-on-event=DemSatellite_0InternalBehavior/GetEventUdsStatus, operation=Event_CodingEventTransactionFailed.GetEventUdsStatus
        OpEventGetEventUdsStatus_GetEventUdsStatus_EvtInfo_FrifENitChA: start-on-event=DemSatellite_0InternalBehavior/GetEventUdsStatus, operation=EvtInfo_FrifENitChA.GetEventUdsStatus
        OpEventGetEventUdsStatus_GetEventUdsStatus_Event_FrifENitChA: start-on-event=DemSatellite_0InternalBehavior/GetEventUdsStatus, operation=Event_FrifENitChA.GetEventUdsStatus
        OpEventGetEventUdsStatus_GetEventUdsStatus_EvtInfo_CansmEBusLpCanOff: start-on-event=DemSatellite_0InternalBehavior/GetEventUdsStatus, operation=EvtInfo_CansmEBusLpCanOff.GetEventUdsStatus
        OpEventGetEventUdsStatus_GetEventUdsStatus_Event_CansmEBusLpCanOff: start-on-event=DemSatellite_0InternalBehavior/GetEventUdsStatus, operation=Event_CansmEBusLpCanOff.GetEventUdsStatus
        OpEventGetEventUdsStatus_GetEventUdsStatus_EvtInfo_NVM_E_HARDWARE: start-on-event=DemSatellite_0InternalBehavior/GetEventUdsStatus, operation=EvtInfo_NVM_E_HARDWARE.GetEventUdsStatus
        OpEventGetEventUdsStatus_GetEventUdsStatus_EvtInfo_VsmEventOpmode: start-on-event=DemSatellite_0InternalBehavior/GetEventUdsStatus, operation=EvtInfo_VsmEventOpmode.GetEventUdsStatus
        OpEventGetEventUdsStatus_GetEventUdsStatus_Event_VsmEventOpmode: start-on-event=DemSatellite_0InternalBehavior/GetEventUdsStatus, operation=Event_VsmEventOpmode.GetEventUdsStatus
        OpEventGetEventUdsStatus_GetEventUdsStatus_EvtInfo_LIN_E_TIMEOUT: start-on-event=DemSatellite_0InternalBehavior/GetEventUdsStatus, operation=EvtInfo_LIN_E_TIMEOUT.GetEventUdsStatus
        OpEventGetEventUdsStatus_GetEventUdsStatus_EvtInfo_CantrcvEBusACanError: start-on-event=DemSatellite_0InternalBehavior/GetEventUdsStatus, operation=EvtInfo_CantrcvEBusACanError.GetEventUdsStatus
        OpEventGetEventUdsStatus_GetEventUdsStatus_Event_CantrcvEBusACanError: start-on-event=DemSatellite_0InternalBehavior/GetEventUdsStatus, operation=Event_CantrcvEBusACanError.GetEventUdsStatus
        OpEventGetEventUdsStatus_GetEventUdsStatus_EvtInfo_UDPNM_E_TCPIP_TRANSMIT_ERROR: start-on-event=DemSatellite_0InternalBehavior/GetEventUdsStatus, operation=EvtInfo_UDPNM_E_TCPIP_TRANSMIT_ERROR.GetEventUdsStatus
        OpEventGetEventUdsStatus_GetEventUdsStatus_EvtInfo_DmTestCom: start-on-event=DemSatellite_0InternalBehavior/GetEventUdsStatus, operation=EvtInfo_DmTestCom.GetEventUdsStatus
        OpEventGetEventUdsStatus_GetEventUdsStatus_Event_DmTestCom: start-on-event=DemSatellite_0InternalBehavior/GetEventUdsStatus, operation=Event_DmTestCom.GetEventUdsStatus
        OpEventGetEventUdsStatus_GetEventUdsStatus_EvtInfo_CodingEventSignatureError: start-on-event=DemSatellite_0InternalBehavior/GetEventUdsStatus, operation=EvtInfo_CodingEventSignatureError.GetEventUdsStatus
        OpEventGetEventUdsStatus_GetEventUdsStatus_Event_CodingEventSignatureError: start-on-event=DemSatellite_0InternalBehavior/GetEventUdsStatus, operation=Event_CodingEventSignatureError.GetEventUdsStatus
        OpEventGetEventUdsStatus_GetEventUdsStatus_EvtInfo_CodingEventUnqualifiedData: start-on-event=DemSatellite_0InternalBehavior/GetEventUdsStatus, operation=EvtInfo_CodingEventUnqualifiedData.GetEventUdsStatus
        OpEventGetEventUdsStatus_GetEventUdsStatus_Event_CodingEventUnqualifiedData: start-on-event=DemSatellite_0InternalBehavior/GetEventUdsStatus, operation=Event_CodingEventUnqualifiedData.GetEventUdsStatus
        OpEventGetEventUdsStatus_GetEventUdsStatus_EvtInfo_CodingEventInvalidData: start-on-event=DemSatellite_0InternalBehavior/GetEventUdsStatus, operation=EvtInfo_CodingEventInvalidData.GetEventUdsStatus
        OpEventGetEventUdsStatus_GetEventUdsStatus_Event_CodingEventInvalidData: start-on-event=DemSatellite_0InternalBehavior/GetEventUdsStatus, operation=Event_CodingEventInvalidData.GetEventUdsStatus
        OpEventGetEventUdsStatus_GetEventUdsStatus_EvtInfo_CansmEBusB2CanOff: start-on-event=DemSatellite_0InternalBehavior/GetEventUdsStatus, operation=EvtInfo_CansmEBusB2CanOff.GetEventUdsStatus
        OpEventGetEventUdsStatus_GetEventUdsStatus_Event_CansmEBusB2CanOff: start-on-event=DemSatellite_0InternalBehavior/GetEventUdsStatus, operation=Event_CansmEBusB2CanOff.GetEventUdsStatus
        OpEventGetEventUdsStatus_GetEventUdsStatus_EvtInfo_Overvoltage: start-on-event=DemSatellite_0InternalBehavior/GetEventUdsStatus, operation=EvtInfo_Overvoltage.GetEventUdsStatus
        OpEventGetEventUdsStatus_GetEventUdsStatus_Event_Overvoltage: start-on-event=DemSatellite_0InternalBehavior/GetEventUdsStatus, operation=Event_Overvoltage.GetEventUdsStatus
        OpEventGetEventUdsStatus_GetEventUdsStatus_EvtInfo_CodingEventNotCoded: start-on-event=DemSatellite_0InternalBehavior/GetEventUdsStatus, operation=EvtInfo_CodingEventNotCoded.GetEventUdsStatus
        OpEventGetEventUdsStatus_GetEventUdsStatus_Event_CodingEventNotCoded: start-on-event=DemSatellite_0InternalBehavior/GetEventUdsStatus, operation=Event_CodingEventNotCoded.GetEventUdsStatus
        OpEventGetEventUdsStatus_GetEventUdsStatus_EvtInfo_FrifEAcsChA: start-on-event=DemSatellite_0InternalBehavior/GetEventUdsStatus, operation=EvtInfo_FrifEAcsChA.GetEventUdsStatus
        OpEventGetEventUdsStatus_GetEventUdsStatus_Event_FrifEAcsChA: start-on-event=DemSatellite_0InternalBehavior/GetEventUdsStatus, operation=Event_FrifEAcsChA.GetEventUdsStatus
        OpEventGetEventUdsStatus_GetEventUdsStatus_EvtInfo_CantrcvEBusFaCanError: start-on-event=DemSatellite_0InternalBehavior/GetEventUdsStatus, operation=EvtInfo_CantrcvEBusFaCanError.GetEventUdsStatus
        OpEventGetEventUdsStatus_GetEventUdsStatus_Event_CantrcvEBusFaCanError: start-on-event=DemSatellite_0InternalBehavior/GetEventUdsStatus, operation=Event_CantrcvEBusFaCanError.GetEventUdsStatus
        OpEventGetEventUdsStatus_GetEventUdsStatus_EvtInfo_CantrcvEBusLeCanError: start-on-event=DemSatellite_0InternalBehavior/GetEventUdsStatus, operation=EvtInfo_CantrcvEBusLeCanError.GetEventUdsStatus
        OpEventGetEventUdsStatus_GetEventUdsStatus_Event_CantrcvEBusLeCanError: start-on-event=DemSatellite_0InternalBehavior/GetEventUdsStatus, operation=Event_CantrcvEBusLeCanError.GetEventUdsStatus
        OpEventGetEventUdsStatus_GetEventUdsStatus_EvtInfo_CantrcvEBusLpCanError: start-on-event=DemSatellite_0InternalBehavior/GetEventUdsStatus, operation=EvtInfo_CantrcvEBusLpCanError.GetEventUdsStatus
        OpEventGetEventUdsStatus_GetEventUdsStatus_Event_CantrcvEBusLpCanError: start-on-event=DemSatellite_0InternalBehavior/GetEventUdsStatus, operation=Event_CantrcvEBusLpCanError.GetEventUdsStatus
        OpEventGetEventUdsStatus_GetEventUdsStatus_EvtInfo_CantrcvEBusZsgCanError: start-on-event=DemSatellite_0InternalBehavior/GetEventUdsStatus, operation=EvtInfo_CantrcvEBusZsgCanError.GetEventUdsStatus
        OpEventGetEventUdsStatus_GetEventUdsStatus_Event_CantrcvEBusZsgCanError: start-on-event=DemSatellite_0InternalBehavior/GetEventUdsStatus, operation=Event_CantrcvEBusZsgCanError.GetEventUdsStatus
        OpEventGetEventUdsStatus_GetEventUdsStatus_EvtInfo_EthSignalQualityLow: start-on-event=DemSatellite_0InternalBehavior/GetEventUdsStatus, operation=EvtInfo_EthSignalQualityLow.GetEventUdsStatus
        OpEventGetEventUdsStatus_GetEventUdsStatus_Event_EthSignalQualityLow: start-on-event=DemSatellite_0InternalBehavior/GetEventUdsStatus, operation=Event_EthSignalQualityLow.GetEventUdsStatus
        OpEventGetEventUdsStatus_GetEventUdsStatus_EvtInfo_DemEventParameter_FlsConfigSet_FLS_E_COMPARE_FAILED: start-on-event=DemSatellite_0InternalBehavior/GetEventUdsStatus, operation=EvtInfo_DemEventParameter_FlsConfigSet_FLS_E_COMPARE_FAILED.GetEventUdsStatus
        OpEventGetEventUdsStatus_GetEventUdsStatus_EvtInfo_DemEventParameter_FlsConfigSet_FLS_E_ERASE_FAILED: start-on-event=DemSatellite_0InternalBehavior/GetEventUdsStatus, operation=EvtInfo_DemEventParameter_FlsConfigSet_FLS_E_ERASE_FAILED.GetEventUdsStatus
        OpEventGetEventUdsStatus_GetEventUdsStatus_EvtInfo_DemEventParameter_FlsConfigSet_FLS_E_READ_FAILED: start-on-event=DemSatellite_0InternalBehavior/GetEventUdsStatus, operation=EvtInfo_DemEventParameter_FlsConfigSet_FLS_E_READ_FAILED.GetEventUdsStatus
        OpEventGetEventUdsStatus_GetEventUdsStatus_EvtInfo_DemEventParameter_FlsConfigSet_FLS_E_WRITE_FAILED: start-on-event=DemSatellite_0InternalBehavior/GetEventUdsStatus, operation=EvtInfo_DemEventParameter_FlsConfigSet_FLS_E_WRITE_FAILED.GetEventUdsStatus
        OpEventGetEventUdsStatus_GetEventUdsStatus_EvtInfo_DemEventParameter_FlsConfigSet_FLS_E_READ_DED_FAILED: start-on-event=DemSatellite_0InternalBehavior/GetEventUdsStatus, operation=EvtInfo_DemEventParameter_FlsConfigSet_FLS_E_READ_DED_FAILED.GetEventUdsStatus
        OpEventGetEventUdsStatus_GetEventUdsStatus_EvtInfo_DemEventParameter_FlsConfigSet_FLS_E_UNEXPECTED_FLASH_ID: start-on-event=DemSatellite_0InternalBehavior/GetEventUdsStatus, operation=EvtInfo_DemEventParameter_FlsConfigSet_FLS_E_UNEXPECTED_FLASH_ID.GetEventUdsStatus
        OpEventGetEventUdsStatus_GetEventUdsStatus_EvtInfo_DemEventParameter_FlsConfigSet_MCU_E_CLOCK_FAILED: start-on-event=DemSatellite_0InternalBehavior/GetEventUdsStatus, operation=EvtInfo_DemEventParameter_FlsConfigSet_MCU_E_CLOCK_FAILED.GetEventUdsStatus
        OpEventGetEventUdsStatus_GetEventUdsStatus_EvtInfo_DemEventParameter_FlsConfigSet_MCU_E_HW_FAILED: start-on-event=DemSatellite_0InternalBehavior/GetEventUdsStatus, operation=EvtInfo_DemEventParameter_FlsConfigSet_MCU_E_HW_FAILED.GetEventUdsStatus
        OpEventGetEventUdsStatus_GetEventUdsStatus_EvtInfo_DemEventParameter_FlsConfigSet_MCU_E_STARTUP_FAILED: start-on-event=DemSatellite_0InternalBehavior/GetEventUdsStatus, operation=EvtInfo_DemEventParameter_FlsConfigSet_MCU_E_STARTUP_FAILED.GetEventUdsStatus
        OpEventGetEventUdsStatus_GetEventUdsStatus_EvtInfo_DemEventParameter_FlsConfigSet_FLS_E_ECC_FAILED: start-on-event=DemSatellite_0InternalBehavior/GetEventUdsStatus, operation=EvtInfo_DemEventParameter_FlsConfigSet_FLS_E_ECC_FAILED.GetEventUdsStatus
        OpEventGetEventUdsStatus_GetEventUdsStatus_EvtInfo_DemEventParameter_FlsConfigSet_FLS_E_VRFY_FAILED: start-on-event=DemSatellite_0InternalBehavior/GetEventUdsStatus, operation=EvtInfo_DemEventParameter_FlsConfigSet_FLS_E_VRFY_FAILED.GetEventUdsStatus
        OpEventGetEventUdsStatus_GetEventUdsStatus_EvtInfo_DemEventParameter_FlsConfigSet_FLS_E_INT_FAILED: start-on-event=DemSatellite_0InternalBehavior/GetEventUdsStatus, operation=EvtInfo_DemEventParameter_FlsConfigSet_FLS_E_INT_FAILED.GetEventUdsStatus
        OpEventGetEventUdsStatus_GetEventUdsStatus_EvtInfo_DemEventParameter_FlsConfigSet_FLS_E_HW_FAILED: start-on-event=DemSatellite_0InternalBehavior/GetEventUdsStatus, operation=EvtInfo_DemEventParameter_FlsConfigSet_FLS_E_HW_FAILED.GetEventUdsStatus
        OpEventGetEventUdsStatus_GetEventUdsStatus_GeneralEventInfo: start-on-event=DemSatellite_0InternalBehavior/GetEventUdsStatus, operation=GeneralEventInfo.GetEventUdsStatus
        OpEventGetEventStatus_GetEventStatus_EvtInfo_FrtrcvEFrErrnTrcv0: start-on-event=DemSatellite_0InternalBehavior/GetEventStatus, operation=EvtInfo_FrtrcvEFrErrnTrcv0.GetEventStatus
        OpEventGetEventStatus_GetEventStatus_Event_FrtrcvEFrErrnTrcv0: start-on-event=DemSatellite_0InternalBehavior/GetEventStatus, operation=Event_FrtrcvEFrErrnTrcv0.GetEventStatus
        OpEventGetEventStatus_GetEventStatus_EvtInfo_CansmEBusIukCanOff: start-on-event=DemSatellite_0InternalBehavior/GetEventStatus, operation=EvtInfo_CansmEBusIukCanOff.GetEventStatus
        OpEventGetEventStatus_GetEventStatus_Event_CansmEBusIukCanOff: start-on-event=DemSatellite_0InternalBehavior/GetEventStatus, operation=Event_CansmEBusIukCanOff.GetEventStatus
        OpEventGetEventStatus_GetEventStatus_EvtInfo_FrtrcvEFrErrnTrcv2: start-on-event=DemSatellite_0InternalBehavior/GetEventStatus, operation=EvtInfo_FrtrcvEFrErrnTrcv2.GetEventStatus
        OpEventGetEventStatus_GetEventStatus_Event_FrtrcvEFrErrnTrcv2: start-on-event=DemSatellite_0InternalBehavior/GetEventStatus, operation=Event_FrtrcvEFrErrnTrcv2.GetEventStatus
        OpEventGetEventStatus_GetEventStatus_EvtInfo_FrtrcvEFrErrnTrcv1: start-on-event=DemSatellite_0InternalBehavior/GetEventStatus, operation=EvtInfo_FrtrcvEFrErrnTrcv1.GetEventStatus
        OpEventGetEventStatus_GetEventStatus_Event_FrtrcvEFrErrnTrcv1: start-on-event=DemSatellite_0InternalBehavior/GetEventStatus, operation=Event_FrtrcvEFrErrnTrcv1.GetEventStatus
        OpEventGetEventStatus_GetEventStatus_EvtInfo_FrtrcvEFrErrnTrcv4: start-on-event=DemSatellite_0InternalBehavior/GetEventStatus, operation=EvtInfo_FrtrcvEFrErrnTrcv4.GetEventStatus
        OpEventGetEventStatus_GetEventStatus_Event_FrtrcvEFrErrnTrcv4: start-on-event=DemSatellite_0InternalBehavior/GetEventStatus, operation=Event_FrtrcvEFrErrnTrcv4.GetEventStatus
        OpEventGetEventStatus_GetEventStatus_EvtInfo_FrtrcvEFrErrnTrcv3: start-on-event=DemSatellite_0InternalBehavior/GetEventStatus, operation=EvtInfo_FrtrcvEFrErrnTrcv3.GetEventStatus
        OpEventGetEventStatus_GetEventStatus_Event_FrtrcvEFrErrnTrcv3: start-on-event=DemSatellite_0InternalBehavior/GetEventStatus, operation=Event_FrtrcvEFrErrnTrcv3.GetEventStatus
        OpEventGetEventStatus_GetEventStatus_EvtInfo_FrtrcvEFrErrnTrcv6: start-on-event=DemSatellite_0InternalBehavior/GetEventStatus, operation=EvtInfo_FrtrcvEFrErrnTrcv6.GetEventStatus
        OpEventGetEventStatus_GetEventStatus_Event_FrtrcvEFrErrnTrcv6: start-on-event=DemSatellite_0InternalBehavior/GetEventStatus, operation=Event_FrtrcvEFrErrnTrcv6.GetEventStatus
        OpEventGetEventStatus_GetEventStatus_EvtInfo_FrtrcvEFrErrnTrcv5: start-on-event=DemSatellite_0InternalBehavior/GetEventStatus, operation=EvtInfo_FrtrcvEFrErrnTrcv5.GetEventStatus
        OpEventGetEventStatus_GetEventStatus_Event_FrtrcvEFrErrnTrcv5: start-on-event=DemSatellite_0InternalBehavior/GetEventStatus, operation=Event_FrtrcvEFrErrnTrcv5.GetEventStatus
        OpEventGetEventStatus_GetEventStatus_EvtInfo_CansmEBusBodyCanOff: start-on-event=DemSatellite_0InternalBehavior/GetEventStatus, operation=EvtInfo_CansmEBusBodyCanOff.GetEventStatus
        OpEventGetEventStatus_GetEventStatus_Event_CansmEBusBodyCanOff: start-on-event=DemSatellite_0InternalBehavior/GetEventStatus, operation=Event_CansmEBusBodyCanOff.GetEventStatus
        OpEventGetEventStatus_GetEventStatus_EvtInfo_CbsReplacementValue: start-on-event=DemSatellite_0InternalBehavior/GetEventStatus, operation=EvtInfo_CbsReplacementValue.GetEventStatus
        OpEventGetEventStatus_GetEventStatus_Event_CbsReplacementValue: start-on-event=DemSatellite_0InternalBehavior/GetEventStatus, operation=Event_CbsReplacementValue.GetEventStatus
        OpEventGetEventStatus_GetEventStatus_EvtInfo_CansmEBusLeCanOff: start-on-event=DemSatellite_0InternalBehavior/GetEventStatus, operation=EvtInfo_CansmEBusLeCanOff.GetEventStatus
        OpEventGetEventStatus_GetEventStatus_Event_CansmEBusLeCanOff: start-on-event=DemSatellite_0InternalBehavior/GetEventStatus, operation=Event_CansmEBusLeCanOff.GetEventStatus
        OpEventGetEventStatus_GetEventStatus_EvtInfo_CansmEBusZsgCanOff: start-on-event=DemSatellite_0InternalBehavior/GetEventStatus, operation=EvtInfo_CansmEBusZsgCanOff.GetEventStatus
        OpEventGetEventStatus_GetEventStatus_Event_CansmEBusZsgCanOff: start-on-event=DemSatellite_0InternalBehavior/GetEventStatus, operation=Event_CansmEBusZsgCanOff.GetEventStatus
        OpEventGetEventStatus_GetEventStatus_EvtInfo_CodingEventWrongVehicle: start-on-event=DemSatellite_0InternalBehavior/GetEventStatus, operation=EvtInfo_CodingEventWrongVehicle.GetEventStatus
        OpEventGetEventStatus_GetEventStatus_Event_CodingEventWrongVehicle: start-on-event=DemSatellite_0InternalBehavior/GetEventStatus, operation=Event_CodingEventWrongVehicle.GetEventStatus
        OpEventGetEventStatus_GetEventStatus_EvtInfo_FrsmEClusterStartup: start-on-event=DemSatellite_0InternalBehavior/GetEventStatus, operation=EvtInfo_FrsmEClusterStartup.GetEventStatus
        OpEventGetEventStatus_GetEventStatus_Event_FrsmEClusterStartup: start-on-event=DemSatellite_0InternalBehavior/GetEventStatus, operation=Event_FrsmEClusterStartup.GetEventStatus
        OpEventGetEventStatus_GetEventStatus_EvtInfo_CansmEBusACanOff: start-on-event=DemSatellite_0InternalBehavior/GetEventStatus, operation=EvtInfo_CansmEBusACanOff.GetEventStatus
        OpEventGetEventStatus_GetEventStatus_Event_CansmEBusACanOff: start-on-event=DemSatellite_0InternalBehavior/GetEventStatus, operation=Event_CansmEBusACanOff.GetEventStatus
        OpEventGetEventStatus_GetEventStatus_EvtInfo_CansmEBusKCanOff: start-on-event=DemSatellite_0InternalBehavior/GetEventStatus, operation=EvtInfo_CansmEBusKCanOff.GetEventStatus
        OpEventGetEventStatus_GetEventStatus_Event_CansmEBusKCanOff: start-on-event=DemSatellite_0InternalBehavior/GetEventStatus, operation=Event_CansmEBusKCanOff.GetEventStatus
        OpEventGetEventStatus_GetEventStatus_EvtInfo_CantrcvEBusKCanError: start-on-event=DemSatellite_0InternalBehavior/GetEventStatus, operation=EvtInfo_CantrcvEBusKCanError.GetEventStatus
        OpEventGetEventStatus_GetEventStatus_Event_CantrcvEBusKCanError: start-on-event=DemSatellite_0InternalBehavior/GetEventStatus, operation=Event_CantrcvEBusKCanError.GetEventStatus
        OpEventGetEventStatus_GetEventStatus_EvtInfo_FrtrcvEFrBuserrorTrcv0: start-on-event=DemSatellite_0InternalBehavior/GetEventStatus, operation=EvtInfo_FrtrcvEFrBuserrorTrcv0.GetEventStatus
        OpEventGetEventStatus_GetEventStatus_Event_FrtrcvEFrBuserrorTrcv0: start-on-event=DemSatellite_0InternalBehavior/GetEventStatus, operation=Event_FrtrcvEFrBuserrorTrcv0.GetEventStatus
        OpEventGetEventStatus_GetEventStatus_EvtInfo_FrtrcvEFrErrnTrcv7: start-on-event=DemSatellite_0InternalBehavior/GetEventStatus, operation=EvtInfo_FrtrcvEFrErrnTrcv7.GetEventStatus
        OpEventGetEventStatus_GetEventStatus_Event_FrtrcvEFrErrnTrcv7: start-on-event=DemSatellite_0InternalBehavior/GetEventStatus, operation=Event_FrtrcvEFrErrnTrcv7.GetEventStatus
        OpEventGetEventStatus_GetEventStatus_EvtInfo_CansmEBusFaCanOff: start-on-event=DemSatellite_0InternalBehavior/GetEventStatus, operation=EvtInfo_CansmEBusFaCanOff.GetEventStatus
        OpEventGetEventStatus_GetEventStatus_Event_CansmEBusFaCanOff: start-on-event=DemSatellite_0InternalBehavior/GetEventStatus, operation=Event_CansmEBusFaCanOff.GetEventStatus
        OpEventGetEventStatus_GetEventStatus_EvtInfo_CantrcvEBusB2CanError: start-on-event=DemSatellite_0InternalBehavior/GetEventStatus, operation=EvtInfo_CantrcvEBusB2CanError.GetEventStatus
        OpEventGetEventStatus_GetEventStatus_Event_CantrcvEBusB2CanError: start-on-event=DemSatellite_0InternalBehavior/GetEventStatus, operation=Event_CantrcvEBusB2CanError.GetEventStatus
        OpEventGetEventStatus_GetEventStatus_EvtInfo_DtcCd0605: start-on-event=DemSatellite_0InternalBehavior/GetEventStatus, operation=EvtInfo_DtcCd0605.GetEventStatus
        OpEventGetEventStatus_GetEventStatus_Event_DtcCd0605: start-on-event=DemSatellite_0InternalBehavior/GetEventStatus, operation=Event_DtcCd0605.GetEventStatus
        OpEventGetEventStatus_GetEventStatus_EvtInfo_DtcCd0606: start-on-event=DemSatellite_0InternalBehavior/GetEventStatus, operation=EvtInfo_DtcCd0606.GetEventStatus
        OpEventGetEventStatus_GetEventStatus_Event_DtcCd0606: start-on-event=DemSatellite_0InternalBehavior/GetEventStatus, operation=Event_DtcCd0606.GetEventStatus
        OpEventGetEventStatus_GetEventStatus_EvtInfo_DtcCd0607: start-on-event=DemSatellite_0InternalBehavior/GetEventStatus, operation=EvtInfo_DtcCd0607.GetEventStatus
        OpEventGetEventStatus_GetEventStatus_Event_DtcCd0607: start-on-event=DemSatellite_0InternalBehavior/GetEventStatus, operation=Event_DtcCd0607.GetEventStatus
        OpEventGetEventStatus_GetEventStatus_EvtInfo_PiaEIoError: start-on-event=DemSatellite_0InternalBehavior/GetEventStatus, operation=EvtInfo_PiaEIoError.GetEventStatus
        OpEventGetEventStatus_GetEventStatus_Event_PiaEIoError: start-on-event=DemSatellite_0InternalBehavior/GetEventStatus, operation=Event_PiaEIoError.GetEventStatus
        OpEventGetEventStatus_GetEventStatus_EvtInfo_DtcCd0601: start-on-event=DemSatellite_0InternalBehavior/GetEventStatus, operation=EvtInfo_DtcCd0601.GetEventStatus
        OpEventGetEventStatus_GetEventStatus_Event_DtcCd0601: start-on-event=DemSatellite_0InternalBehavior/GetEventStatus, operation=Event_DtcCd0601.GetEventStatus
        OpEventGetEventStatus_GetEventStatus_EvtInfo_SwtExternalCheckFailure: start-on-event=DemSatellite_0InternalBehavior/GetEventStatus, operation=EvtInfo_SwtExternalCheckFailure.GetEventStatus
        OpEventGetEventStatus_GetEventStatus_Event_SwtExternalCheckFailure: start-on-event=DemSatellite_0InternalBehavior/GetEventStatus, operation=Event_SwtExternalCheckFailure.GetEventStatus
        OpEventGetEventStatus_GetEventStatus_EvtInfo_CantrcvEBusBodyCanError: start-on-event=DemSatellite_0InternalBehavior/GetEventStatus, operation=EvtInfo_CantrcvEBusBodyCanError.GetEventStatus
        OpEventGetEventStatus_GetEventStatus_Event_CantrcvEBusBodyCanError: start-on-event=DemSatellite_0InternalBehavior/GetEventStatus, operation=Event_CantrcvEBusBodyCanError.GetEventStatus
        OpEventGetEventStatus_GetEventStatus_EvtInfo_CantrcvEBusIukError: start-on-event=DemSatellite_0InternalBehavior/GetEventStatus, operation=EvtInfo_CantrcvEBusIukError.GetEventStatus
        OpEventGetEventStatus_GetEventStatus_Event_CantrcvEBusIukError: start-on-event=DemSatellite_0InternalBehavior/GetEventStatus, operation=Event_CantrcvEBusIukError.GetEventStatus
        OpEventGetEventStatus_GetEventStatus_EvtInfo_SwtInternalCheckFailure: start-on-event=DemSatellite_0InternalBehavior/GetEventStatus, operation=EvtInfo_SwtInternalCheckFailure.GetEventStatus
        OpEventGetEventStatus_GetEventStatus_Event_SwtInternalCheckFailure: start-on-event=DemSatellite_0InternalBehavior/GetEventStatus, operation=Event_SwtInternalCheckFailure.GetEventStatus
        OpEventGetEventStatus_GetEventStatus_EvtInfo_DmTestAppl: start-on-event=DemSatellite_0InternalBehavior/GetEventStatus, operation=EvtInfo_DmTestAppl.GetEventStatus
        OpEventGetEventStatus_GetEventStatus_Event_DmTestAppl: start-on-event=DemSatellite_0InternalBehavior/GetEventStatus, operation=Event_DmTestAppl.GetEventStatus
        OpEventGetEventStatus_GetEventStatus_EvtInfo_Dtc000032: start-on-event=DemSatellite_0InternalBehavior/GetEventStatus, operation=EvtInfo_Dtc000032.GetEventStatus
        OpEventGetEventStatus_GetEventStatus_Event_Dtc000032: start-on-event=DemSatellite_0InternalBehavior/GetEventStatus, operation=Event_Dtc000032.GetEventStatus
        OpEventGetEventStatus_GetEventStatus_EvtInfo_Dtc000031: start-on-event=DemSatellite_0InternalBehavior/GetEventStatus, operation=EvtInfo_Dtc000031.GetEventStatus
        OpEventGetEventStatus_GetEventStatus_Event_Dtc000031: start-on-event=DemSatellite_0InternalBehavior/GetEventStatus, operation=Event_Dtc000031.GetEventStatus
        OpEventGetEventStatus_GetEventStatus_EvtInfo_FrsmEClusterSyncLoss: start-on-event=DemSatellite_0InternalBehavior/GetEventStatus, operation=EvtInfo_FrsmEClusterSyncLoss.GetEventStatus
        OpEventGetEventStatus_GetEventStatus_Event_FrsmEClusterSyncLoss: start-on-event=DemSatellite_0InternalBehavior/GetEventStatus, operation=Event_FrsmEClusterSyncLoss.GetEventStatus
        OpEventGetEventStatus_GetEventStatus_EvtInfo_Dtc000030: start-on-event=DemSatellite_0InternalBehavior/GetEventStatus, operation=EvtInfo_Dtc000030.GetEventStatus
        OpEventGetEventStatus_GetEventStatus_Event_Dtc000030: start-on-event=DemSatellite_0InternalBehavior/GetEventStatus, operation=Event_Dtc000030.GetEventStatus
        OpEventGetEventStatus_GetEventStatus_EvtInfo_Dtc000034: start-on-event=DemSatellite_0InternalBehavior/GetEventStatus, operation=EvtInfo_Dtc000034.GetEventStatus
        OpEventGetEventStatus_GetEventStatus_Event_Dtc000034: start-on-event=DemSatellite_0InternalBehavior/GetEventStatus, operation=Event_Dtc000034.GetEventStatus
        OpEventGetEventStatus_GetEventStatus_EvtInfo_Dtc000033: start-on-event=DemSatellite_0InternalBehavior/GetEventStatus, operation=EvtInfo_Dtc000033.GetEventStatus
        OpEventGetEventStatus_GetEventStatus_Event_Dtc000033: start-on-event=DemSatellite_0InternalBehavior/GetEventStatus, operation=Event_Dtc000033.GetEventStatus
        OpEventGetEventStatus_GetEventStatus_EvtInfo_Undervoltage: start-on-event=DemSatellite_0InternalBehavior/GetEventStatus, operation=EvtInfo_Undervoltage.GetEventStatus
        OpEventGetEventStatus_GetEventStatus_Event_Undervoltage: start-on-event=DemSatellite_0InternalBehavior/GetEventStatus, operation=Event_Undervoltage.GetEventStatus
        OpEventGetEventStatus_GetEventStatus_EvtInfo_CodingEventTransactionFailed: start-on-event=DemSatellite_0InternalBehavior/GetEventStatus, operation=EvtInfo_CodingEventTransactionFailed.GetEventStatus
        OpEventGetEventStatus_GetEventStatus_Event_CodingEventTransactionFailed: start-on-event=DemSatellite_0InternalBehavior/GetEventStatus, operation=Event_CodingEventTransactionFailed.GetEventStatus
        OpEventGetEventStatus_GetEventStatus_EvtInfo_FrifENitChA: start-on-event=DemSatellite_0InternalBehavior/GetEventStatus, operation=EvtInfo_FrifENitChA.GetEventStatus
        OpEventGetEventStatus_GetEventStatus_Event_FrifENitChA: start-on-event=DemSatellite_0InternalBehavior/GetEventStatus, operation=Event_FrifENitChA.GetEventStatus
        OpEventGetEventStatus_GetEventStatus_EvtInfo_CansmEBusLpCanOff: start-on-event=DemSatellite_0InternalBehavior/GetEventStatus, operation=EvtInfo_CansmEBusLpCanOff.GetEventStatus
        OpEventGetEventStatus_GetEventStatus_Event_CansmEBusLpCanOff: start-on-event=DemSatellite_0InternalBehavior/GetEventStatus, operation=Event_CansmEBusLpCanOff.GetEventStatus
        OpEventGetEventStatus_GetEventStatus_EvtInfo_NVM_E_HARDWARE: start-on-event=DemSatellite_0InternalBehavior/GetEventStatus, operation=EvtInfo_NVM_E_HARDWARE.GetEventStatus
        OpEventGetEventStatus_GetEventStatus_EvtInfo_VsmEventOpmode: start-on-event=DemSatellite_0InternalBehavior/GetEventStatus, operation=EvtInfo_VsmEventOpmode.GetEventStatus
        OpEventGetEventStatus_GetEventStatus_Event_VsmEventOpmode: start-on-event=DemSatellite_0InternalBehavior/GetEventStatus, operation=Event_VsmEventOpmode.GetEventStatus
        OpEventGetEventStatus_GetEventStatus_EvtInfo_LIN_E_TIMEOUT: start-on-event=DemSatellite_0InternalBehavior/GetEventStatus, operation=EvtInfo_LIN_E_TIMEOUT.GetEventStatus
        OpEventGetEventStatus_GetEventStatus_EvtInfo_CantrcvEBusACanError: start-on-event=DemSatellite_0InternalBehavior/GetEventStatus, operation=EvtInfo_CantrcvEBusACanError.GetEventStatus
        OpEventGetEventStatus_GetEventStatus_Event_CantrcvEBusACanError: start-on-event=DemSatellite_0InternalBehavior/GetEventStatus, operation=Event_CantrcvEBusACanError.GetEventStatus
        OpEventGetEventStatus_GetEventStatus_EvtInfo_UDPNM_E_TCPIP_TRANSMIT_ERROR: start-on-event=DemSatellite_0InternalBehavior/GetEventStatus, operation=EvtInfo_UDPNM_E_TCPIP_TRANSMIT_ERROR.GetEventStatus
        OpEventGetEventStatus_GetEventStatus_EvtInfo_DmTestCom: start-on-event=DemSatellite_0InternalBehavior/GetEventStatus, operation=EvtInfo_DmTestCom.GetEventStatus
        OpEventGetEventStatus_GetEventStatus_Event_DmTestCom: start-on-event=DemSatellite_0InternalBehavior/GetEventStatus, operation=Event_DmTestCom.GetEventStatus
        OpEventGetEventStatus_GetEventStatus_EvtInfo_CodingEventSignatureError: start-on-event=DemSatellite_0InternalBehavior/GetEventStatus, operation=EvtInfo_CodingEventSignatureError.GetEventStatus
        OpEventGetEventStatus_GetEventStatus_Event_CodingEventSignatureError: start-on-event=DemSatellite_0InternalBehavior/GetEventStatus, operation=Event_CodingEventSignatureError.GetEventStatus
        OpEventGetEventStatus_GetEventStatus_EvtInfo_CodingEventUnqualifiedData: start-on-event=DemSatellite_0InternalBehavior/GetEventStatus, operation=EvtInfo_CodingEventUnqualifiedData.GetEventStatus
        OpEventGetEventStatus_GetEventStatus_Event_CodingEventUnqualifiedData: start-on-event=DemSatellite_0InternalBehavior/GetEventStatus, operation=Event_CodingEventUnqualifiedData.GetEventStatus
        OpEventGetEventStatus_GetEventStatus_EvtInfo_CodingEventInvalidData: start-on-event=DemSatellite_0InternalBehavior/GetEventStatus, operation=EvtInfo_CodingEventInvalidData.GetEventStatus
        OpEventGetEventStatus_GetEventStatus_Event_CodingEventInvalidData: start-on-event=DemSatellite_0InternalBehavior/GetEventStatus, operation=Event_CodingEventInvalidData.GetEventStatus
        OpEventGetEventStatus_GetEventStatus_EvtInfo_CansmEBusB2CanOff: start-on-event=DemSatellite_0InternalBehavior/GetEventStatus, operation=EvtInfo_CansmEBusB2CanOff.GetEventStatus
        OpEventGetEventStatus_GetEventStatus_Event_CansmEBusB2CanOff: start-on-event=DemSatellite_0InternalBehavior/GetEventStatus, operation=Event_CansmEBusB2CanOff.GetEventStatus
        OpEventGetEventStatus_GetEventStatus_EvtInfo_Overvoltage: start-on-event=DemSatellite_0InternalBehavior/GetEventStatus, operation=EvtInfo_Overvoltage.GetEventStatus
        OpEventGetEventStatus_GetEventStatus_Event_Overvoltage: start-on-event=DemSatellite_0InternalBehavior/GetEventStatus, operation=Event_Overvoltage.GetEventStatus
        OpEventGetEventStatus_GetEventStatus_EvtInfo_CodingEventNotCoded: start-on-event=DemSatellite_0InternalBehavior/GetEventStatus, operation=EvtInfo_CodingEventNotCoded.GetEventStatus
        OpEventGetEventStatus_GetEventStatus_Event_CodingEventNotCoded: start-on-event=DemSatellite_0InternalBehavior/GetEventStatus, operation=Event_CodingEventNotCoded.GetEventStatus
        OpEventGetEventStatus_GetEventStatus_EvtInfo_FrifEAcsChA: start-on-event=DemSatellite_0InternalBehavior/GetEventStatus, operation=EvtInfo_FrifEAcsChA.GetEventStatus
        OpEventGetEventStatus_GetEventStatus_Event_FrifEAcsChA: start-on-event=DemSatellite_0InternalBehavior/GetEventStatus, operation=Event_FrifEAcsChA.GetEventStatus
        OpEventGetEventStatus_GetEventStatus_EvtInfo_CantrcvEBusFaCanError: start-on-event=DemSatellite_0InternalBehavior/GetEventStatus, operation=EvtInfo_CantrcvEBusFaCanError.GetEventStatus
        OpEventGetEventStatus_GetEventStatus_Event_CantrcvEBusFaCanError: start-on-event=DemSatellite_0InternalBehavior/GetEventStatus, operation=Event_CantrcvEBusFaCanError.GetEventStatus
        OpEventGetEventStatus_GetEventStatus_EvtInfo_CantrcvEBusLeCanError: start-on-event=DemSatellite_0InternalBehavior/GetEventStatus, operation=EvtInfo_CantrcvEBusLeCanError.GetEventStatus
        OpEventGetEventStatus_GetEventStatus_Event_CantrcvEBusLeCanError: start-on-event=DemSatellite_0InternalBehavior/GetEventStatus, operation=Event_CantrcvEBusLeCanError.GetEventStatus
        OpEventGetEventStatus_GetEventStatus_EvtInfo_CantrcvEBusLpCanError: start-on-event=DemSatellite_0InternalBehavior/GetEventStatus, operation=EvtInfo_CantrcvEBusLpCanError.GetEventStatus
        OpEventGetEventStatus_GetEventStatus_Event_CantrcvEBusLpCanError: start-on-event=DemSatellite_0InternalBehavior/GetEventStatus, operation=Event_CantrcvEBusLpCanError.GetEventStatus
        OpEventGetEventStatus_GetEventStatus_EvtInfo_CantrcvEBusZsgCanError: start-on-event=DemSatellite_0InternalBehavior/GetEventStatus, operation=EvtInfo_CantrcvEBusZsgCanError.GetEventStatus
        OpEventGetEventStatus_GetEventStatus_Event_CantrcvEBusZsgCanError: start-on-event=DemSatellite_0InternalBehavior/GetEventStatus, operation=Event_CantrcvEBusZsgCanError.GetEventStatus
        OpEventGetEventStatus_GetEventStatus_EvtInfo_EthSignalQualityLow: start-on-event=DemSatellite_0InternalBehavior/GetEventStatus, operation=EvtInfo_EthSignalQualityLow.GetEventStatus
        OpEventGetEventStatus_GetEventStatus_Event_EthSignalQualityLow: start-on-event=DemSatellite_0InternalBehavior/GetEventStatus, operation=Event_EthSignalQualityLow.GetEventStatus
        OpEventGetEventStatus_GetEventStatus_EvtInfo_DemEventParameter_FlsConfigSet_FLS_E_COMPARE_FAILED: start-on-event=DemSatellite_0InternalBehavior/GetEventStatus, operation=EvtInfo_DemEventParameter_FlsConfigSet_FLS_E_COMPARE_FAILED.GetEventStatus
        OpEventGetEventStatus_GetEventStatus_EvtInfo_DemEventParameter_FlsConfigSet_FLS_E_ERASE_FAILED: start-on-event=DemSatellite_0InternalBehavior/GetEventStatus, operation=EvtInfo_DemEventParameter_FlsConfigSet_FLS_E_ERASE_FAILED.GetEventStatus
        OpEventGetEventStatus_GetEventStatus_EvtInfo_DemEventParameter_FlsConfigSet_FLS_E_READ_FAILED: start-on-event=DemSatellite_0InternalBehavior/GetEventStatus, operation=EvtInfo_DemEventParameter_FlsConfigSet_FLS_E_READ_FAILED.GetEventStatus
        OpEventGetEventStatus_GetEventStatus_EvtInfo_DemEventParameter_FlsConfigSet_FLS_E_WRITE_FAILED: start-on-event=DemSatellite_0InternalBehavior/GetEventStatus, operation=EvtInfo_DemEventParameter_FlsConfigSet_FLS_E_WRITE_FAILED.GetEventStatus
        OpEventGetEventStatus_GetEventStatus_EvtInfo_DemEventParameter_FlsConfigSet_FLS_E_READ_DED_FAILED: start-on-event=DemSatellite_0InternalBehavior/GetEventStatus, operation=EvtInfo_DemEventParameter_FlsConfigSet_FLS_E_READ_DED_FAILED.GetEventStatus
        OpEventGetEventStatus_GetEventStatus_EvtInfo_DemEventParameter_FlsConfigSet_FLS_E_UNEXPECTED_FLASH_ID: start-on-event=DemSatellite_0InternalBehavior/GetEventStatus, operation=EvtInfo_DemEventParameter_FlsConfigSet_FLS_E_UNEXPECTED_FLASH_ID.GetEventStatus
        OpEventGetEventStatus_GetEventStatus_EvtInfo_DemEventParameter_FlsConfigSet_MCU_E_CLOCK_FAILED: start-on-event=DemSatellite_0InternalBehavior/GetEventStatus, operation=EvtInfo_DemEventParameter_FlsConfigSet_MCU_E_CLOCK_FAILED.GetEventStatus
        OpEventGetEventStatus_GetEventStatus_EvtInfo_DemEventParameter_FlsConfigSet_MCU_E_HW_FAILED: start-on-event=DemSatellite_0InternalBehavior/GetEventStatus, operation=EvtInfo_DemEventParameter_FlsConfigSet_MCU_E_HW_FAILED.GetEventStatus
        OpEventGetEventStatus_GetEventStatus_EvtInfo_DemEventParameter_FlsConfigSet_MCU_E_STARTUP_FAILED: start-on-event=DemSatellite_0InternalBehavior/GetEventStatus, operation=EvtInfo_DemEventParameter_FlsConfigSet_MCU_E_STARTUP_FAILED.GetEventStatus
        OpEventGetEventStatus_GetEventStatus_EvtInfo_DemEventParameter_FlsConfigSet_FLS_E_ECC_FAILED: start-on-event=DemSatellite_0InternalBehavior/GetEventStatus, operation=EvtInfo_DemEventParameter_FlsConfigSet_FLS_E_ECC_FAILED.GetEventStatus
        OpEventGetEventStatus_GetEventStatus_EvtInfo_DemEventParameter_FlsConfigSet_FLS_E_VRFY_FAILED: start-on-event=DemSatellite_0InternalBehavior/GetEventStatus, operation=EvtInfo_DemEventParameter_FlsConfigSet_FLS_E_VRFY_FAILED.GetEventStatus
        OpEventGetEventStatus_GetEventStatus_EvtInfo_DemEventParameter_FlsConfigSet_FLS_E_INT_FAILED: start-on-event=DemSatellite_0InternalBehavior/GetEventStatus, operation=EvtInfo_DemEventParameter_FlsConfigSet_FLS_E_INT_FAILED.GetEventStatus
        OpEventGetEventStatus_GetEventStatus_EvtInfo_DemEventParameter_FlsConfigSet_FLS_E_HW_FAILED: start-on-event=DemSatellite_0InternalBehavior/GetEventStatus, operation=EvtInfo_DemEventParameter_FlsConfigSet_FLS_E_HW_FAILED.GetEventStatus
        OpEventGetEventStatus_GetEventStatus_GeneralEventInfo: start-on-event=DemSatellite_0InternalBehavior/GetEventStatus, operation=GeneralEventInfo.GetEventStatus
        OpEventGetEventFailed_GetEventFailed_EvtInfo_FrtrcvEFrErrnTrcv0: start-on-event=DemSatellite_0InternalBehavior/GetEventFailed, operation=EvtInfo_FrtrcvEFrErrnTrcv0.GetEventFailed
        OpEventGetEventFailed_GetEventFailed_Event_FrtrcvEFrErrnTrcv0: start-on-event=DemSatellite_0InternalBehavior/GetEventFailed, operation=Event_FrtrcvEFrErrnTrcv0.GetEventFailed
        OpEventGetEventFailed_GetEventFailed_EvtInfo_CansmEBusIukCanOff: start-on-event=DemSatellite_0InternalBehavior/GetEventFailed, operation=EvtInfo_CansmEBusIukCanOff.GetEventFailed
        OpEventGetEventFailed_GetEventFailed_Event_CansmEBusIukCanOff: start-on-event=DemSatellite_0InternalBehavior/GetEventFailed, operation=Event_CansmEBusIukCanOff.GetEventFailed
        OpEventGetEventFailed_GetEventFailed_EvtInfo_FrtrcvEFrErrnTrcv2: start-on-event=DemSatellite_0InternalBehavior/GetEventFailed, operation=EvtInfo_FrtrcvEFrErrnTrcv2.GetEventFailed
        OpEventGetEventFailed_GetEventFailed_Event_FrtrcvEFrErrnTrcv2: start-on-event=DemSatellite_0InternalBehavior/GetEventFailed, operation=Event_FrtrcvEFrErrnTrcv2.GetEventFailed
        OpEventGetEventFailed_GetEventFailed_EvtInfo_FrtrcvEFrErrnTrcv1: start-on-event=DemSatellite_0InternalBehavior/GetEventFailed, operation=EvtInfo_FrtrcvEFrErrnTrcv1.GetEventFailed
        OpEventGetEventFailed_GetEventFailed_Event_FrtrcvEFrErrnTrcv1: start-on-event=DemSatellite_0InternalBehavior/GetEventFailed, operation=Event_FrtrcvEFrErrnTrcv1.GetEventFailed
        OpEventGetEventFailed_GetEventFailed_EvtInfo_FrtrcvEFrErrnTrcv4: start-on-event=DemSatellite_0InternalBehavior/GetEventFailed, operation=EvtInfo_FrtrcvEFrErrnTrcv4.GetEventFailed
        OpEventGetEventFailed_GetEventFailed_Event_FrtrcvEFrErrnTrcv4: start-on-event=DemSatellite_0InternalBehavior/GetEventFailed, operation=Event_FrtrcvEFrErrnTrcv4.GetEventFailed
        OpEventGetEventFailed_GetEventFailed_EvtInfo_FrtrcvEFrErrnTrcv3: start-on-event=DemSatellite_0InternalBehavior/GetEventFailed, operation=EvtInfo_FrtrcvEFrErrnTrcv3.GetEventFailed
        OpEventGetEventFailed_GetEventFailed_Event_FrtrcvEFrErrnTrcv3: start-on-event=DemSatellite_0InternalBehavior/GetEventFailed, operation=Event_FrtrcvEFrErrnTrcv3.GetEventFailed
        OpEventGetEventFailed_GetEventFailed_EvtInfo_FrtrcvEFrErrnTrcv6: start-on-event=DemSatellite_0InternalBehavior/GetEventFailed, operation=EvtInfo_FrtrcvEFrErrnTrcv6.GetEventFailed
        OpEventGetEventFailed_GetEventFailed_Event_FrtrcvEFrErrnTrcv6: start-on-event=DemSatellite_0InternalBehavior/GetEventFailed, operation=Event_FrtrcvEFrErrnTrcv6.GetEventFailed
        OpEventGetEventFailed_GetEventFailed_EvtInfo_FrtrcvEFrErrnTrcv5: start-on-event=DemSatellite_0InternalBehavior/GetEventFailed, operation=EvtInfo_FrtrcvEFrErrnTrcv5.GetEventFailed
        OpEventGetEventFailed_GetEventFailed_Event_FrtrcvEFrErrnTrcv5: start-on-event=DemSatellite_0InternalBehavior/GetEventFailed, operation=Event_FrtrcvEFrErrnTrcv5.GetEventFailed
        OpEventGetEventFailed_GetEventFailed_EvtInfo_CansmEBusBodyCanOff: start-on-event=DemSatellite_0InternalBehavior/GetEventFailed, operation=EvtInfo_CansmEBusBodyCanOff.GetEventFailed
        OpEventGetEventFailed_GetEventFailed_Event_CansmEBusBodyCanOff: start-on-event=DemSatellite_0InternalBehavior/GetEventFailed, operation=Event_CansmEBusBodyCanOff.GetEventFailed
        OpEventGetEventFailed_GetEventFailed_EvtInfo_CbsReplacementValue: start-on-event=DemSatellite_0InternalBehavior/GetEventFailed, operation=EvtInfo_CbsReplacementValue.GetEventFailed
        OpEventGetEventFailed_GetEventFailed_Event_CbsReplacementValue: start-on-event=DemSatellite_0InternalBehavior/GetEventFailed, operation=Event_CbsReplacementValue.GetEventFailed
        OpEventGetEventFailed_GetEventFailed_EvtInfo_CansmEBusLeCanOff: start-on-event=DemSatellite_0InternalBehavior/GetEventFailed, operation=EvtInfo_CansmEBusLeCanOff.GetEventFailed
        OpEventGetEventFailed_GetEventFailed_Event_CansmEBusLeCanOff: start-on-event=DemSatellite_0InternalBehavior/GetEventFailed, operation=Event_CansmEBusLeCanOff.GetEventFailed
        OpEventGetEventFailed_GetEventFailed_EvtInfo_CansmEBusZsgCanOff: start-on-event=DemSatellite_0InternalBehavior/GetEventFailed, operation=EvtInfo_CansmEBusZsgCanOff.GetEventFailed
        OpEventGetEventFailed_GetEventFailed_Event_CansmEBusZsgCanOff: start-on-event=DemSatellite_0InternalBehavior/GetEventFailed, operation=Event_CansmEBusZsgCanOff.GetEventFailed
        OpEventGetEventFailed_GetEventFailed_EvtInfo_CodingEventWrongVehicle: start-on-event=DemSatellite_0InternalBehavior/GetEventFailed, operation=EvtInfo_CodingEventWrongVehicle.GetEventFailed
        OpEventGetEventFailed_GetEventFailed_Event_CodingEventWrongVehicle: start-on-event=DemSatellite_0InternalBehavior/GetEventFailed, operation=Event_CodingEventWrongVehicle.GetEventFailed
        OpEventGetEventFailed_GetEventFailed_EvtInfo_FrsmEClusterStartup: start-on-event=DemSatellite_0InternalBehavior/GetEventFailed, operation=EvtInfo_FrsmEClusterStartup.GetEventFailed
        OpEventGetEventFailed_GetEventFailed_Event_FrsmEClusterStartup: start-on-event=DemSatellite_0InternalBehavior/GetEventFailed, operation=Event_FrsmEClusterStartup.GetEventFailed
        OpEventGetEventFailed_GetEventFailed_EvtInfo_CansmEBusACanOff: start-on-event=DemSatellite_0InternalBehavior/GetEventFailed, operation=EvtInfo_CansmEBusACanOff.GetEventFailed
        OpEventGetEventFailed_GetEventFailed_Event_CansmEBusACanOff: start-on-event=DemSatellite_0InternalBehavior/GetEventFailed, operation=Event_CansmEBusACanOff.GetEventFailed
        OpEventGetEventFailed_GetEventFailed_EvtInfo_CansmEBusKCanOff: start-on-event=DemSatellite_0InternalBehavior/GetEventFailed, operation=EvtInfo_CansmEBusKCanOff.GetEventFailed
        OpEventGetEventFailed_GetEventFailed_Event_CansmEBusKCanOff: start-on-event=DemSatellite_0InternalBehavior/GetEventFailed, operation=Event_CansmEBusKCanOff.GetEventFailed
        OpEventGetEventFailed_GetEventFailed_EvtInfo_CantrcvEBusKCanError: start-on-event=DemSatellite_0InternalBehavior/GetEventFailed, operation=EvtInfo_CantrcvEBusKCanError.GetEventFailed
        OpEventGetEventFailed_GetEventFailed_Event_CantrcvEBusKCanError: start-on-event=DemSatellite_0InternalBehavior/GetEventFailed, operation=Event_CantrcvEBusKCanError.GetEventFailed
        OpEventGetEventFailed_GetEventFailed_EvtInfo_FrtrcvEFrBuserrorTrcv0: start-on-event=DemSatellite_0InternalBehavior/GetEventFailed, operation=EvtInfo_FrtrcvEFrBuserrorTrcv0.GetEventFailed
        OpEventGetEventFailed_GetEventFailed_Event_FrtrcvEFrBuserrorTrcv0: start-on-event=DemSatellite_0InternalBehavior/GetEventFailed, operation=Event_FrtrcvEFrBuserrorTrcv0.GetEventFailed
        OpEventGetEventFailed_GetEventFailed_EvtInfo_FrtrcvEFrErrnTrcv7: start-on-event=DemSatellite_0InternalBehavior/GetEventFailed, operation=EvtInfo_FrtrcvEFrErrnTrcv7.GetEventFailed
        OpEventGetEventFailed_GetEventFailed_Event_FrtrcvEFrErrnTrcv7: start-on-event=DemSatellite_0InternalBehavior/GetEventFailed, operation=Event_FrtrcvEFrErrnTrcv7.GetEventFailed
        OpEventGetEventFailed_GetEventFailed_EvtInfo_CansmEBusFaCanOff: start-on-event=DemSatellite_0InternalBehavior/GetEventFailed, operation=EvtInfo_CansmEBusFaCanOff.GetEventFailed
        OpEventGetEventFailed_GetEventFailed_Event_CansmEBusFaCanOff: start-on-event=DemSatellite_0InternalBehavior/GetEventFailed, operation=Event_CansmEBusFaCanOff.GetEventFailed
        OpEventGetEventFailed_GetEventFailed_EvtInfo_CantrcvEBusB2CanError: start-on-event=DemSatellite_0InternalBehavior/GetEventFailed, operation=EvtInfo_CantrcvEBusB2CanError.GetEventFailed
        OpEventGetEventFailed_GetEventFailed_Event_CantrcvEBusB2CanError: start-on-event=DemSatellite_0InternalBehavior/GetEventFailed, operation=Event_CantrcvEBusB2CanError.GetEventFailed
        OpEventGetEventFailed_GetEventFailed_EvtInfo_DtcCd0605: start-on-event=DemSatellite_0InternalBehavior/GetEventFailed, operation=EvtInfo_DtcCd0605.GetEventFailed
        OpEventGetEventFailed_GetEventFailed_Event_DtcCd0605: start-on-event=DemSatellite_0InternalBehavior/GetEventFailed, operation=Event_DtcCd0605.GetEventFailed
        OpEventGetEventFailed_GetEventFailed_EvtInfo_DtcCd0606: start-on-event=DemSatellite_0InternalBehavior/GetEventFailed, operation=EvtInfo_DtcCd0606.GetEventFailed
        OpEventGetEventFailed_GetEventFailed_Event_DtcCd0606: start-on-event=DemSatellite_0InternalBehavior/GetEventFailed, operation=Event_DtcCd0606.GetEventFailed
        OpEventGetEventFailed_GetEventFailed_EvtInfo_DtcCd0607: start-on-event=DemSatellite_0InternalBehavior/GetEventFailed, operation=EvtInfo_DtcCd0607.GetEventFailed
        OpEventGetEventFailed_GetEventFailed_Event_DtcCd0607: start-on-event=DemSatellite_0InternalBehavior/GetEventFailed, operation=Event_DtcCd0607.GetEventFailed
        OpEventGetEventFailed_GetEventFailed_EvtInfo_PiaEIoError: start-on-event=DemSatellite_0InternalBehavior/GetEventFailed, operation=EvtInfo_PiaEIoError.GetEventFailed
        OpEventGetEventFailed_GetEventFailed_Event_PiaEIoError: start-on-event=DemSatellite_0InternalBehavior/GetEventFailed, operation=Event_PiaEIoError.GetEventFailed
        OpEventGetEventFailed_GetEventFailed_EvtInfo_DtcCd0601: start-on-event=DemSatellite_0InternalBehavior/GetEventFailed, operation=EvtInfo_DtcCd0601.GetEventFailed
        OpEventGetEventFailed_GetEventFailed_Event_DtcCd0601: start-on-event=DemSatellite_0InternalBehavior/GetEventFailed, operation=Event_DtcCd0601.GetEventFailed
        OpEventGetEventFailed_GetEventFailed_EvtInfo_SwtExternalCheckFailure: start-on-event=DemSatellite_0InternalBehavior/GetEventFailed, operation=EvtInfo_SwtExternalCheckFailure.GetEventFailed
        OpEventGetEventFailed_GetEventFailed_Event_SwtExternalCheckFailure: start-on-event=DemSatellite_0InternalBehavior/GetEventFailed, operation=Event_SwtExternalCheckFailure.GetEventFailed
        OpEventGetEventFailed_GetEventFailed_EvtInfo_CantrcvEBusBodyCanError: start-on-event=DemSatellite_0InternalBehavior/GetEventFailed, operation=EvtInfo_CantrcvEBusBodyCanError.GetEventFailed
        OpEventGetEventFailed_GetEventFailed_Event_CantrcvEBusBodyCanError: start-on-event=DemSatellite_0InternalBehavior/GetEventFailed, operation=Event_CantrcvEBusBodyCanError.GetEventFailed
        OpEventGetEventFailed_GetEventFailed_EvtInfo_CantrcvEBusIukError: start-on-event=DemSatellite_0InternalBehavior/GetEventFailed, operation=EvtInfo_CantrcvEBusIukError.GetEventFailed
        OpEventGetEventFailed_GetEventFailed_Event_CantrcvEBusIukError: start-on-event=DemSatellite_0InternalBehavior/GetEventFailed, operation=Event_CantrcvEBusIukError.GetEventFailed
        OpEventGetEventFailed_GetEventFailed_EvtInfo_SwtInternalCheckFailure: start-on-event=DemSatellite_0InternalBehavior/GetEventFailed, operation=EvtInfo_SwtInternalCheckFailure.GetEventFailed
        OpEventGetEventFailed_GetEventFailed_Event_SwtInternalCheckFailure: start-on-event=DemSatellite_0InternalBehavior/GetEventFailed, operation=Event_SwtInternalCheckFailure.GetEventFailed
        OpEventGetEventFailed_GetEventFailed_EvtInfo_DmTestAppl: start-on-event=DemSatellite_0InternalBehavior/GetEventFailed, operation=EvtInfo_DmTestAppl.GetEventFailed
        OpEventGetEventFailed_GetEventFailed_Event_DmTestAppl: start-on-event=DemSatellite_0InternalBehavior/GetEventFailed, operation=Event_DmTestAppl.GetEventFailed
        OpEventGetEventFailed_GetEventFailed_EvtInfo_Dtc000032: start-on-event=DemSatellite_0InternalBehavior/GetEventFailed, operation=EvtInfo_Dtc000032.GetEventFailed
        OpEventGetEventFailed_GetEventFailed_Event_Dtc000032: start-on-event=DemSatellite_0InternalBehavior/GetEventFailed, operation=Event_Dtc000032.GetEventFailed
        OpEventGetEventFailed_GetEventFailed_EvtInfo_Dtc000031: start-on-event=DemSatellite_0InternalBehavior/GetEventFailed, operation=EvtInfo_Dtc000031.GetEventFailed
        OpEventGetEventFailed_GetEventFailed_Event_Dtc000031: start-on-event=DemSatellite_0InternalBehavior/GetEventFailed, operation=Event_Dtc000031.GetEventFailed
        OpEventGetEventFailed_GetEventFailed_EvtInfo_FrsmEClusterSyncLoss: start-on-event=DemSatellite_0InternalBehavior/GetEventFailed, operation=EvtInfo_FrsmEClusterSyncLoss.GetEventFailed
        OpEventGetEventFailed_GetEventFailed_Event_FrsmEClusterSyncLoss: start-on-event=DemSatellite_0InternalBehavior/GetEventFailed, operation=Event_FrsmEClusterSyncLoss.GetEventFailed
        OpEventGetEventFailed_GetEventFailed_EvtInfo_Dtc000030: start-on-event=DemSatellite_0InternalBehavior/GetEventFailed, operation=EvtInfo_Dtc000030.GetEventFailed
        OpEventGetEventFailed_GetEventFailed_Event_Dtc000030: start-on-event=DemSatellite_0InternalBehavior/GetEventFailed, operation=Event_Dtc000030.GetEventFailed
        OpEventGetEventFailed_GetEventFailed_EvtInfo_Dtc000034: start-on-event=DemSatellite_0InternalBehavior/GetEventFailed, operation=EvtInfo_Dtc000034.GetEventFailed
        OpEventGetEventFailed_GetEventFailed_Event_Dtc000034: start-on-event=DemSatellite_0InternalBehavior/GetEventFailed, operation=Event_Dtc000034.GetEventFailed
        OpEventGetEventFailed_GetEventFailed_EvtInfo_Dtc000033: start-on-event=DemSatellite_0InternalBehavior/GetEventFailed, operation=EvtInfo_Dtc000033.GetEventFailed
        OpEventGetEventFailed_GetEventFailed_Event_Dtc000033: start-on-event=DemSatellite_0InternalBehavior/GetEventFailed, operation=Event_Dtc000033.GetEventFailed
        OpEventGetEventFailed_GetEventFailed_EvtInfo_Undervoltage: start-on-event=DemSatellite_0InternalBehavior/GetEventFailed, operation=EvtInfo_Undervoltage.GetEventFailed
        OpEventGetEventFailed_GetEventFailed_Event_Undervoltage: start-on-event=DemSatellite_0InternalBehavior/GetEventFailed, operation=Event_Undervoltage.GetEventFailed
        OpEventGetEventFailed_GetEventFailed_EvtInfo_CodingEventTransactionFailed: start-on-event=DemSatellite_0InternalBehavior/GetEventFailed, operation=EvtInfo_CodingEventTransactionFailed.GetEventFailed
        OpEventGetEventFailed_GetEventFailed_Event_CodingEventTransactionFailed: start-on-event=DemSatellite_0InternalBehavior/GetEventFailed, operation=Event_CodingEventTransactionFailed.GetEventFailed
        OpEventGetEventFailed_GetEventFailed_EvtInfo_FrifENitChA: start-on-event=DemSatellite_0InternalBehavior/GetEventFailed, operation=EvtInfo_FrifENitChA.GetEventFailed
        OpEventGetEventFailed_GetEventFailed_Event_FrifENitChA: start-on-event=DemSatellite_0InternalBehavior/GetEventFailed, operation=Event_FrifENitChA.GetEventFailed
        OpEventGetEventFailed_GetEventFailed_EvtInfo_CansmEBusLpCanOff: start-on-event=DemSatellite_0InternalBehavior/GetEventFailed, operation=EvtInfo_CansmEBusLpCanOff.GetEventFailed
        OpEventGetEventFailed_GetEventFailed_Event_CansmEBusLpCanOff: start-on-event=DemSatellite_0InternalBehavior/GetEventFailed, operation=Event_CansmEBusLpCanOff.GetEventFailed
        OpEventGetEventFailed_GetEventFailed_EvtInfo_NVM_E_HARDWARE: start-on-event=DemSatellite_0InternalBehavior/GetEventFailed, operation=EvtInfo_NVM_E_HARDWARE.GetEventFailed
        OpEventGetEventFailed_GetEventFailed_EvtInfo_VsmEventOpmode: start-on-event=DemSatellite_0InternalBehavior/GetEventFailed, operation=EvtInfo_VsmEventOpmode.GetEventFailed
        OpEventGetEventFailed_GetEventFailed_Event_VsmEventOpmode: start-on-event=DemSatellite_0InternalBehavior/GetEventFailed, operation=Event_VsmEventOpmode.GetEventFailed
        OpEventGetEventFailed_GetEventFailed_EvtInfo_LIN_E_TIMEOUT: start-on-event=DemSatellite_0InternalBehavior/GetEventFailed, operation=EvtInfo_LIN_E_TIMEOUT.GetEventFailed
        OpEventGetEventFailed_GetEventFailed_EvtInfo_CantrcvEBusACanError: start-on-event=DemSatellite_0InternalBehavior/GetEventFailed, operation=EvtInfo_CantrcvEBusACanError.GetEventFailed
        OpEventGetEventFailed_GetEventFailed_Event_CantrcvEBusACanError: start-on-event=DemSatellite_0InternalBehavior/GetEventFailed, operation=Event_CantrcvEBusACanError.GetEventFailed
        OpEventGetEventFailed_GetEventFailed_EvtInfo_UDPNM_E_TCPIP_TRANSMIT_ERROR: start-on-event=DemSatellite_0InternalBehavior/GetEventFailed, operation=EvtInfo_UDPNM_E_TCPIP_TRANSMIT_ERROR.GetEventFailed
        OpEventGetEventFailed_GetEventFailed_EvtInfo_DmTestCom: start-on-event=DemSatellite_0InternalBehavior/GetEventFailed, operation=EvtInfo_DmTestCom.GetEventFailed
        OpEventGetEventFailed_GetEventFailed_Event_DmTestCom: start-on-event=DemSatellite_0InternalBehavior/GetEventFailed, operation=Event_DmTestCom.GetEventFailed
        OpEventGetEventFailed_GetEventFailed_EvtInfo_CodingEventSignatureError: start-on-event=DemSatellite_0InternalBehavior/GetEventFailed, operation=EvtInfo_CodingEventSignatureError.GetEventFailed
        OpEventGetEventFailed_GetEventFailed_Event_CodingEventSignatureError: start-on-event=DemSatellite_0InternalBehavior/GetEventFailed, operation=Event_CodingEventSignatureError.GetEventFailed
        OpEventGetEventFailed_GetEventFailed_EvtInfo_CodingEventUnqualifiedData: start-on-event=DemSatellite_0InternalBehavior/GetEventFailed, operation=EvtInfo_CodingEventUnqualifiedData.GetEventFailed
        OpEventGetEventFailed_GetEventFailed_Event_CodingEventUnqualifiedData: start-on-event=DemSatellite_0InternalBehavior/GetEventFailed, operation=Event_CodingEventUnqualifiedData.GetEventFailed
        OpEventGetEventFailed_GetEventFailed_EvtInfo_CodingEventInvalidData: start-on-event=DemSatellite_0InternalBehavior/GetEventFailed, operation=EvtInfo_CodingEventInvalidData.GetEventFailed
        OpEventGetEventFailed_GetEventFailed_Event_CodingEventInvalidData: start-on-event=DemSatellite_0InternalBehavior/GetEventFailed, operation=Event_CodingEventInvalidData.GetEventFailed
        OpEventGetEventFailed_GetEventFailed_EvtInfo_CansmEBusB2CanOff: start-on-event=DemSatellite_0InternalBehavior/GetEventFailed, operation=EvtInfo_CansmEBusB2CanOff.GetEventFailed
        OpEventGetEventFailed_GetEventFailed_Event_CansmEBusB2CanOff: start-on-event=DemSatellite_0InternalBehavior/GetEventFailed, operation=Event_CansmEBusB2CanOff.GetEventFailed
        OpEventGetEventFailed_GetEventFailed_EvtInfo_Overvoltage: start-on-event=DemSatellite_0InternalBehavior/GetEventFailed, operation=EvtInfo_Overvoltage.GetEventFailed
        OpEventGetEventFailed_GetEventFailed_Event_Overvoltage: start-on-event=DemSatellite_0InternalBehavior/GetEventFailed, operation=Event_Overvoltage.GetEventFailed
        OpEventGetEventFailed_GetEventFailed_EvtInfo_CodingEventNotCoded: start-on-event=DemSatellite_0InternalBehavior/GetEventFailed, operation=EvtInfo_CodingEventNotCoded.GetEventFailed
        OpEventGetEventFailed_GetEventFailed_Event_CodingEventNotCoded: start-on-event=DemSatellite_0InternalBehavior/GetEventFailed, operation=Event_CodingEventNotCoded.GetEventFailed
        OpEventGetEventFailed_GetEventFailed_EvtInfo_FrifEAcsChA: start-on-event=DemSatellite_0InternalBehavior/GetEventFailed, operation=EvtInfo_FrifEAcsChA.GetEventFailed
        OpEventGetEventFailed_GetEventFailed_Event_FrifEAcsChA: start-on-event=DemSatellite_0InternalBehavior/GetEventFailed, operation=Event_FrifEAcsChA.GetEventFailed
        OpEventGetEventFailed_GetEventFailed_EvtInfo_CantrcvEBusFaCanError: start-on-event=DemSatellite_0InternalBehavior/GetEventFailed, operation=EvtInfo_CantrcvEBusFaCanError.GetEventFailed
        OpEventGetEventFailed_GetEventFailed_Event_CantrcvEBusFaCanError: start-on-event=DemSatellite_0InternalBehavior/GetEventFailed, operation=Event_CantrcvEBusFaCanError.GetEventFailed
        OpEventGetEventFailed_GetEventFailed_EvtInfo_CantrcvEBusLeCanError: start-on-event=DemSatellite_0InternalBehavior/GetEventFailed, operation=EvtInfo_CantrcvEBusLeCanError.GetEventFailed
        OpEventGetEventFailed_GetEventFailed_Event_CantrcvEBusLeCanError: start-on-event=DemSatellite_0InternalBehavior/GetEventFailed, operation=Event_CantrcvEBusLeCanError.GetEventFailed
        OpEventGetEventFailed_GetEventFailed_EvtInfo_CantrcvEBusLpCanError: start-on-event=DemSatellite_0InternalBehavior/GetEventFailed, operation=EvtInfo_CantrcvEBusLpCanError.GetEventFailed
        OpEventGetEventFailed_GetEventFailed_Event_CantrcvEBusLpCanError: start-on-event=DemSatellite_0InternalBehavior/GetEventFailed, operation=Event_CantrcvEBusLpCanError.GetEventFailed
        OpEventGetEventFailed_GetEventFailed_EvtInfo_CantrcvEBusZsgCanError: start-on-event=DemSatellite_0InternalBehavior/GetEventFailed, operation=EvtInfo_CantrcvEBusZsgCanError.GetEventFailed
        OpEventGetEventFailed_GetEventFailed_Event_CantrcvEBusZsgCanError: start-on-event=DemSatellite_0InternalBehavior/GetEventFailed, operation=Event_CantrcvEBusZsgCanError.GetEventFailed
        OpEventGetEventFailed_GetEventFailed_EvtInfo_EthSignalQualityLow: start-on-event=DemSatellite_0InternalBehavior/GetEventFailed, operation=EvtInfo_EthSignalQualityLow.GetEventFailed
        OpEventGetEventFailed_GetEventFailed_Event_EthSignalQualityLow: start-on-event=DemSatellite_0InternalBehavior/GetEventFailed, operation=Event_EthSignalQualityLow.GetEventFailed
        OpEventGetEventFailed_GetEventFailed_EvtInfo_DemEventParameter_FlsConfigSet_FLS_E_COMPARE_FAILED: start-on-event=DemSatellite_0InternalBehavior/GetEventFailed, operation=EvtInfo_DemEventParameter_FlsConfigSet_FLS_E_COMPARE_FAILED.GetEventFailed
        OpEventGetEventFailed_GetEventFailed_EvtInfo_DemEventParameter_FlsConfigSet_FLS_E_ERASE_FAILED: start-on-event=DemSatellite_0InternalBehavior/GetEventFailed, operation=EvtInfo_DemEventParameter_FlsConfigSet_FLS_E_ERASE_FAILED.GetEventFailed
        OpEventGetEventFailed_GetEventFailed_EvtInfo_DemEventParameter_FlsConfigSet_FLS_E_READ_FAILED: start-on-event=DemSatellite_0InternalBehavior/GetEventFailed, operation=EvtInfo_DemEventParameter_FlsConfigSet_FLS_E_READ_FAILED.GetEventFailed
        OpEventGetEventFailed_GetEventFailed_EvtInfo_DemEventParameter_FlsConfigSet_FLS_E_WRITE_FAILED: start-on-event=DemSatellite_0InternalBehavior/GetEventFailed, operation=EvtInfo_DemEventParameter_FlsConfigSet_FLS_E_WRITE_FAILED.GetEventFailed
        OpEventGetEventFailed_GetEventFailed_EvtInfo_DemEventParameter_FlsConfigSet_FLS_E_READ_DED_FAILED: start-on-event=DemSatellite_0InternalBehavior/GetEventFailed, operation=EvtInfo_DemEventParameter_FlsConfigSet_FLS_E_READ_DED_FAILED.GetEventFailed
        OpEventGetEventFailed_GetEventFailed_EvtInfo_DemEventParameter_FlsConfigSet_FLS_E_UNEXPECTED_FLASH_ID: start-on-event=DemSatellite_0InternalBehavior/GetEventFailed, operation=EvtInfo_DemEventParameter_FlsConfigSet_FLS_E_UNEXPECTED_FLASH_ID.GetEventFailed
        OpEventGetEventFailed_GetEventFailed_EvtInfo_DemEventParameter_FlsConfigSet_MCU_E_CLOCK_FAILED: start-on-event=DemSatellite_0InternalBehavior/GetEventFailed, operation=EvtInfo_DemEventParameter_FlsConfigSet_MCU_E_CLOCK_FAILED.GetEventFailed
        OpEventGetEventFailed_GetEventFailed_EvtInfo_DemEventParameter_FlsConfigSet_MCU_E_HW_FAILED: start-on-event=DemSatellite_0InternalBehavior/GetEventFailed, operation=EvtInfo_DemEventParameter_FlsConfigSet_MCU_E_HW_FAILED.GetEventFailed
        OpEventGetEventFailed_GetEventFailed_EvtInfo_DemEventParameter_FlsConfigSet_MCU_E_STARTUP_FAILED: start-on-event=DemSatellite_0InternalBehavior/GetEventFailed, operation=EvtInfo_DemEventParameter_FlsConfigSet_MCU_E_STARTUP_FAILED.GetEventFailed
        OpEventGetEventFailed_GetEventFailed_EvtInfo_DemEventParameter_FlsConfigSet_FLS_E_ECC_FAILED: start-on-event=DemSatellite_0InternalBehavior/GetEventFailed, operation=EvtInfo_DemEventParameter_FlsConfigSet_FLS_E_ECC_FAILED.GetEventFailed
        OpEventGetEventFailed_GetEventFailed_EvtInfo_DemEventParameter_FlsConfigSet_FLS_E_VRFY_FAILED: start-on-event=DemSatellite_0InternalBehavior/GetEventFailed, operation=EvtInfo_DemEventParameter_FlsConfigSet_FLS_E_VRFY_FAILED.GetEventFailed
        OpEventGetEventFailed_GetEventFailed_EvtInfo_DemEventParameter_FlsConfigSet_FLS_E_INT_FAILED: start-on-event=DemSatellite_0InternalBehavior/GetEventFailed, operation=EvtInfo_DemEventParameter_FlsConfigSet_FLS_E_INT_FAILED.GetEventFailed
        OpEventGetEventFailed_GetEventFailed_EvtInfo_DemEventParameter_FlsConfigSet_FLS_E_HW_FAILED: start-on-event=DemSatellite_0InternalBehavior/GetEventFailed, operation=EvtInfo_DemEventParameter_FlsConfigSet_FLS_E_HW_FAILED.GetEventFailed
        OpEventGetEventFailed_GetEventFailed_GeneralEventInfo: start-on-event=DemSatellite_0InternalBehavior/GetEventFailed, operation=GeneralEventInfo.GetEventFailed
        OpEventGetEventTested_GetEventTested_EvtInfo_FrtrcvEFrErrnTrcv0: start-on-event=DemSatellite_0InternalBehavior/GetEventTested, operation=EvtInfo_FrtrcvEFrErrnTrcv0.GetEventTested
        OpEventGetEventTested_GetEventTested_Event_FrtrcvEFrErrnTrcv0: start-on-event=DemSatellite_0InternalBehavior/GetEventTested, operation=Event_FrtrcvEFrErrnTrcv0.GetEventTested
        OpEventGetEventTested_GetEventTested_EvtInfo_CansmEBusIukCanOff: start-on-event=DemSatellite_0InternalBehavior/GetEventTested, operation=EvtInfo_CansmEBusIukCanOff.GetEventTested
        OpEventGetEventTested_GetEventTested_Event_CansmEBusIukCanOff: start-on-event=DemSatellite_0InternalBehavior/GetEventTested, operation=Event_CansmEBusIukCanOff.GetEventTested
        OpEventGetEventTested_GetEventTested_EvtInfo_FrtrcvEFrErrnTrcv2: start-on-event=DemSatellite_0InternalBehavior/GetEventTested, operation=EvtInfo_FrtrcvEFrErrnTrcv2.GetEventTested
        OpEventGetEventTested_GetEventTested_Event_FrtrcvEFrErrnTrcv2: start-on-event=DemSatellite_0InternalBehavior/GetEventTested, operation=Event_FrtrcvEFrErrnTrcv2.GetEventTested
        OpEventGetEventTested_GetEventTested_EvtInfo_FrtrcvEFrErrnTrcv1: start-on-event=DemSatellite_0InternalBehavior/GetEventTested, operation=EvtInfo_FrtrcvEFrErrnTrcv1.GetEventTested
        OpEventGetEventTested_GetEventTested_Event_FrtrcvEFrErrnTrcv1: start-on-event=DemSatellite_0InternalBehavior/GetEventTested, operation=Event_FrtrcvEFrErrnTrcv1.GetEventTested
        OpEventGetEventTested_GetEventTested_EvtInfo_FrtrcvEFrErrnTrcv4: start-on-event=DemSatellite_0InternalBehavior/GetEventTested, operation=EvtInfo_FrtrcvEFrErrnTrcv4.GetEventTested
        OpEventGetEventTested_GetEventTested_Event_FrtrcvEFrErrnTrcv4: start-on-event=DemSatellite_0InternalBehavior/GetEventTested, operation=Event_FrtrcvEFrErrnTrcv4.GetEventTested
        OpEventGetEventTested_GetEventTested_EvtInfo_FrtrcvEFrErrnTrcv3: start-on-event=DemSatellite_0InternalBehavior/GetEventTested, operation=EvtInfo_FrtrcvEFrErrnTrcv3.GetEventTested
        OpEventGetEventTested_GetEventTested_Event_FrtrcvEFrErrnTrcv3: start-on-event=DemSatellite_0InternalBehavior/GetEventTested, operation=Event_FrtrcvEFrErrnTrcv3.GetEventTested
        OpEventGetEventTested_GetEventTested_EvtInfo_FrtrcvEFrErrnTrcv6: start-on-event=DemSatellite_0InternalBehavior/GetEventTested, operation=EvtInfo_FrtrcvEFrErrnTrcv6.GetEventTested
        OpEventGetEventTested_GetEventTested_Event_FrtrcvEFrErrnTrcv6: start-on-event=DemSatellite_0InternalBehavior/GetEventTested, operation=Event_FrtrcvEFrErrnTrcv6.GetEventTested
        OpEventGetEventTested_GetEventTested_EvtInfo_FrtrcvEFrErrnTrcv5: start-on-event=DemSatellite_0InternalBehavior/GetEventTested, operation=EvtInfo_FrtrcvEFrErrnTrcv5.GetEventTested
        OpEventGetEventTested_GetEventTested_Event_FrtrcvEFrErrnTrcv5: start-on-event=DemSatellite_0InternalBehavior/GetEventTested, operation=Event_FrtrcvEFrErrnTrcv5.GetEventTested
        OpEventGetEventTested_GetEventTested_EvtInfo_CansmEBusBodyCanOff: start-on-event=DemSatellite_0InternalBehavior/GetEventTested, operation=EvtInfo_CansmEBusBodyCanOff.GetEventTested
        OpEventGetEventTested_GetEventTested_Event_CansmEBusBodyCanOff: start-on-event=DemSatellite_0InternalBehavior/GetEventTested, operation=Event_CansmEBusBodyCanOff.GetEventTested
        OpEventGetEventTested_GetEventTested_EvtInfo_CbsReplacementValue: start-on-event=DemSatellite_0InternalBehavior/GetEventTested, operation=EvtInfo_CbsReplacementValue.GetEventTested
        OpEventGetEventTested_GetEventTested_Event_CbsReplacementValue: start-on-event=DemSatellite_0InternalBehavior/GetEventTested, operation=Event_CbsReplacementValue.GetEventTested
        OpEventGetEventTested_GetEventTested_EvtInfo_CansmEBusLeCanOff: start-on-event=DemSatellite_0InternalBehavior/GetEventTested, operation=EvtInfo_CansmEBusLeCanOff.GetEventTested
        OpEventGetEventTested_GetEventTested_Event_CansmEBusLeCanOff: start-on-event=DemSatellite_0InternalBehavior/GetEventTested, operation=Event_CansmEBusLeCanOff.GetEventTested
        OpEventGetEventTested_GetEventTested_EvtInfo_CansmEBusZsgCanOff: start-on-event=DemSatellite_0InternalBehavior/GetEventTested, operation=EvtInfo_CansmEBusZsgCanOff.GetEventTested
        OpEventGetEventTested_GetEventTested_Event_CansmEBusZsgCanOff: start-on-event=DemSatellite_0InternalBehavior/GetEventTested, operation=Event_CansmEBusZsgCanOff.GetEventTested
        OpEventGetEventTested_GetEventTested_EvtInfo_CodingEventWrongVehicle: start-on-event=DemSatellite_0InternalBehavior/GetEventTested, operation=EvtInfo_CodingEventWrongVehicle.GetEventTested
        OpEventGetEventTested_GetEventTested_Event_CodingEventWrongVehicle: start-on-event=DemSatellite_0InternalBehavior/GetEventTested, operation=Event_CodingEventWrongVehicle.GetEventTested
        OpEventGetEventTested_GetEventTested_EvtInfo_FrsmEClusterStartup: start-on-event=DemSatellite_0InternalBehavior/GetEventTested, operation=EvtInfo_FrsmEClusterStartup.GetEventTested
        OpEventGetEventTested_GetEventTested_Event_FrsmEClusterStartup: start-on-event=DemSatellite_0InternalBehavior/GetEventTested, operation=Event_FrsmEClusterStartup.GetEventTested
        OpEventGetEventTested_GetEventTested_EvtInfo_CansmEBusACanOff: start-on-event=DemSatellite_0InternalBehavior/GetEventTested, operation=EvtInfo_CansmEBusACanOff.GetEventTested
        OpEventGetEventTested_GetEventTested_Event_CansmEBusACanOff: start-on-event=DemSatellite_0InternalBehavior/GetEventTested, operation=Event_CansmEBusACanOff.GetEventTested
        OpEventGetEventTested_GetEventTested_EvtInfo_CansmEBusKCanOff: start-on-event=DemSatellite_0InternalBehavior/GetEventTested, operation=EvtInfo_CansmEBusKCanOff.GetEventTested
        OpEventGetEventTested_GetEventTested_Event_CansmEBusKCanOff: start-on-event=DemSatellite_0InternalBehavior/GetEventTested, operation=Event_CansmEBusKCanOff.GetEventTested
        OpEventGetEventTested_GetEventTested_EvtInfo_CantrcvEBusKCanError: start-on-event=DemSatellite_0InternalBehavior/GetEventTested, operation=EvtInfo_CantrcvEBusKCanError.GetEventTested
        OpEventGetEventTested_GetEventTested_Event_CantrcvEBusKCanError: start-on-event=DemSatellite_0InternalBehavior/GetEventTested, operation=Event_CantrcvEBusKCanError.GetEventTested
        OpEventGetEventTested_GetEventTested_EvtInfo_FrtrcvEFrBuserrorTrcv0: start-on-event=DemSatellite_0InternalBehavior/GetEventTested, operation=EvtInfo_FrtrcvEFrBuserrorTrcv0.GetEventTested
        OpEventGetEventTested_GetEventTested_Event_FrtrcvEFrBuserrorTrcv0: start-on-event=DemSatellite_0InternalBehavior/GetEventTested, operation=Event_FrtrcvEFrBuserrorTrcv0.GetEventTested
        OpEventGetEventTested_GetEventTested_EvtInfo_FrtrcvEFrErrnTrcv7: start-on-event=DemSatellite_0InternalBehavior/GetEventTested, operation=EvtInfo_FrtrcvEFrErrnTrcv7.GetEventTested
        OpEventGetEventTested_GetEventTested_Event_FrtrcvEFrErrnTrcv7: start-on-event=DemSatellite_0InternalBehavior/GetEventTested, operation=Event_FrtrcvEFrErrnTrcv7.GetEventTested
        OpEventGetEventTested_GetEventTested_EvtInfo_CansmEBusFaCanOff: start-on-event=DemSatellite_0InternalBehavior/GetEventTested, operation=EvtInfo_CansmEBusFaCanOff.GetEventTested
        OpEventGetEventTested_GetEventTested_Event_CansmEBusFaCanOff: start-on-event=DemSatellite_0InternalBehavior/GetEventTested, operation=Event_CansmEBusFaCanOff.GetEventTested
        OpEventGetEventTested_GetEventTested_EvtInfo_CantrcvEBusB2CanError: start-on-event=DemSatellite_0InternalBehavior/GetEventTested, operation=EvtInfo_CantrcvEBusB2CanError.GetEventTested
        OpEventGetEventTested_GetEventTested_Event_CantrcvEBusB2CanError: start-on-event=DemSatellite_0InternalBehavior/GetEventTested, operation=Event_CantrcvEBusB2CanError.GetEventTested
        OpEventGetEventTested_GetEventTested_EvtInfo_DtcCd0605: start-on-event=DemSatellite_0InternalBehavior/GetEventTested, operation=EvtInfo_DtcCd0605.GetEventTested
        OpEventGetEventTested_GetEventTested_Event_DtcCd0605: start-on-event=DemSatellite_0InternalBehavior/GetEventTested, operation=Event_DtcCd0605.GetEventTested
        OpEventGetEventTested_GetEventTested_EvtInfo_DtcCd0606: start-on-event=DemSatellite_0InternalBehavior/GetEventTested, operation=EvtInfo_DtcCd0606.GetEventTested
        OpEventGetEventTested_GetEventTested_Event_DtcCd0606: start-on-event=DemSatellite_0InternalBehavior/GetEventTested, operation=Event_DtcCd0606.GetEventTested
        OpEventGetEventTested_GetEventTested_EvtInfo_DtcCd0607: start-on-event=DemSatellite_0InternalBehavior/GetEventTested, operation=EvtInfo_DtcCd0607.GetEventTested
        OpEventGetEventTested_GetEventTested_Event_DtcCd0607: start-on-event=DemSatellite_0InternalBehavior/GetEventTested, operation=Event_DtcCd0607.GetEventTested
        OpEventGetEventTested_GetEventTested_EvtInfo_PiaEIoError: start-on-event=DemSatellite_0InternalBehavior/GetEventTested, operation=EvtInfo_PiaEIoError.GetEventTested
        OpEventGetEventTested_GetEventTested_Event_PiaEIoError: start-on-event=DemSatellite_0InternalBehavior/GetEventTested, operation=Event_PiaEIoError.GetEventTested
        OpEventGetEventTested_GetEventTested_EvtInfo_DtcCd0601: start-on-event=DemSatellite_0InternalBehavior/GetEventTested, operation=EvtInfo_DtcCd0601.GetEventTested
        OpEventGetEventTested_GetEventTested_Event_DtcCd0601: start-on-event=DemSatellite_0InternalBehavior/GetEventTested, operation=Event_DtcCd0601.GetEventTested
        OpEventGetEventTested_GetEventTested_EvtInfo_SwtExternalCheckFailure: start-on-event=DemSatellite_0InternalBehavior/GetEventTested, operation=EvtInfo_SwtExternalCheckFailure.GetEventTested
        OpEventGetEventTested_GetEventTested_Event_SwtExternalCheckFailure: start-on-event=DemSatellite_0InternalBehavior/GetEventTested, operation=Event_SwtExternalCheckFailure.GetEventTested
        OpEventGetEventTested_GetEventTested_EvtInfo_CantrcvEBusBodyCanError: start-on-event=DemSatellite_0InternalBehavior/GetEventTested, operation=EvtInfo_CantrcvEBusBodyCanError.GetEventTested
        OpEventGetEventTested_GetEventTested_Event_CantrcvEBusBodyCanError: start-on-event=DemSatellite_0InternalBehavior/GetEventTested, operation=Event_CantrcvEBusBodyCanError.GetEventTested
        OpEventGetEventTested_GetEventTested_EvtInfo_CantrcvEBusIukError: start-on-event=DemSatellite_0InternalBehavior/GetEventTested, operation=EvtInfo_CantrcvEBusIukError.GetEventTested
        OpEventGetEventTested_GetEventTested_Event_CantrcvEBusIukError: start-on-event=DemSatellite_0InternalBehavior/GetEventTested, operation=Event_CantrcvEBusIukError.GetEventTested
        OpEventGetEventTested_GetEventTested_EvtInfo_SwtInternalCheckFailure: start-on-event=DemSatellite_0InternalBehavior/GetEventTested, operation=EvtInfo_SwtInternalCheckFailure.GetEventTested
        OpEventGetEventTested_GetEventTested_Event_SwtInternalCheckFailure: start-on-event=DemSatellite_0InternalBehavior/GetEventTested, operation=Event_SwtInternalCheckFailure.GetEventTested
        OpEventGetEventTested_GetEventTested_EvtInfo_DmTestAppl: start-on-event=DemSatellite_0InternalBehavior/GetEventTested, operation=EvtInfo_DmTestAppl.GetEventTested
        OpEventGetEventTested_GetEventTested_Event_DmTestAppl: start-on-event=DemSatellite_0InternalBehavior/GetEventTested, operation=Event_DmTestAppl.GetEventTested
        OpEventGetEventTested_GetEventTested_EvtInfo_Dtc000032: start-on-event=DemSatellite_0InternalBehavior/GetEventTested, operation=EvtInfo_Dtc000032.GetEventTested
        OpEventGetEventTested_GetEventTested_Event_Dtc000032: start-on-event=DemSatellite_0InternalBehavior/GetEventTested, operation=Event_Dtc000032.GetEventTested
        OpEventGetEventTested_GetEventTested_EvtInfo_Dtc000031: start-on-event=DemSatellite_0InternalBehavior/GetEventTested, operation=EvtInfo_Dtc000031.GetEventTested
        OpEventGetEventTested_GetEventTested_Event_Dtc000031: start-on-event=DemSatellite_0InternalBehavior/GetEventTested, operation=Event_Dtc000031.GetEventTested
        OpEventGetEventTested_GetEventTested_EvtInfo_FrsmEClusterSyncLoss: start-on-event=DemSatellite_0InternalBehavior/GetEventTested, operation=EvtInfo_FrsmEClusterSyncLoss.GetEventTested
        OpEventGetEventTested_GetEventTested_Event_FrsmEClusterSyncLoss: start-on-event=DemSatellite_0InternalBehavior/GetEventTested, operation=Event_FrsmEClusterSyncLoss.GetEventTested
        OpEventGetEventTested_GetEventTested_EvtInfo_Dtc000030: start-on-event=DemSatellite_0InternalBehavior/GetEventTested, operation=EvtInfo_Dtc000030.GetEventTested
        OpEventGetEventTested_GetEventTested_Event_Dtc000030: start-on-event=DemSatellite_0InternalBehavior/GetEventTested, operation=Event_Dtc000030.GetEventTested
        OpEventGetEventTested_GetEventTested_EvtInfo_Dtc000034: start-on-event=DemSatellite_0InternalBehavior/GetEventTested, operation=EvtInfo_Dtc000034.GetEventTested
        OpEventGetEventTested_GetEventTested_Event_Dtc000034: start-on-event=DemSatellite_0InternalBehavior/GetEventTested, operation=Event_Dtc000034.GetEventTested
        OpEventGetEventTested_GetEventTested_EvtInfo_Dtc000033: start-on-event=DemSatellite_0InternalBehavior/GetEventTested, operation=EvtInfo_Dtc000033.GetEventTested
        OpEventGetEventTested_GetEventTested_Event_Dtc000033: start-on-event=DemSatellite_0InternalBehavior/GetEventTested, operation=Event_Dtc000033.GetEventTested
        OpEventGetEventTested_GetEventTested_EvtInfo_Undervoltage: start-on-event=DemSatellite_0InternalBehavior/GetEventTested, operation=EvtInfo_Undervoltage.GetEventTested
        OpEventGetEventTested_GetEventTested_Event_Undervoltage: start-on-event=DemSatellite_0InternalBehavior/GetEventTested, operation=Event_Undervoltage.GetEventTested
        OpEventGetEventTested_GetEventTested_EvtInfo_CodingEventTransactionFailed: start-on-event=DemSatellite_0InternalBehavior/GetEventTested, operation=EvtInfo_CodingEventTransactionFailed.GetEventTested
        OpEventGetEventTested_GetEventTested_Event_CodingEventTransactionFailed: start-on-event=DemSatellite_0InternalBehavior/GetEventTested, operation=Event_CodingEventTransactionFailed.GetEventTested
        OpEventGetEventTested_GetEventTested_EvtInfo_FrifENitChA: start-on-event=DemSatellite_0InternalBehavior/GetEventTested, operation=EvtInfo_FrifENitChA.GetEventTested
        OpEventGetEventTested_GetEventTested_Event_FrifENitChA: start-on-event=DemSatellite_0InternalBehavior/GetEventTested, operation=Event_FrifENitChA.GetEventTested
        OpEventGetEventTested_GetEventTested_EvtInfo_CansmEBusLpCanOff: start-on-event=DemSatellite_0InternalBehavior/GetEventTested, operation=EvtInfo_CansmEBusLpCanOff.GetEventTested
        OpEventGetEventTested_GetEventTested_Event_CansmEBusLpCanOff: start-on-event=DemSatellite_0InternalBehavior/GetEventTested, operation=Event_CansmEBusLpCanOff.GetEventTested
        OpEventGetEventTested_GetEventTested_EvtInfo_NVM_E_HARDWARE: start-on-event=DemSatellite_0InternalBehavior/GetEventTested, operation=EvtInfo_NVM_E_HARDWARE.GetEventTested
        OpEventGetEventTested_GetEventTested_EvtInfo_VsmEventOpmode: start-on-event=DemSatellite_0InternalBehavior/GetEventTested, operation=EvtInfo_VsmEventOpmode.GetEventTested
        OpEventGetEventTested_GetEventTested_Event_VsmEventOpmode: start-on-event=DemSatellite_0InternalBehavior/GetEventTested, operation=Event_VsmEventOpmode.GetEventTested
        OpEventGetEventTested_GetEventTested_EvtInfo_LIN_E_TIMEOUT: start-on-event=DemSatellite_0InternalBehavior/GetEventTested, operation=EvtInfo_LIN_E_TIMEOUT.GetEventTested
        OpEventGetEventTested_GetEventTested_EvtInfo_CantrcvEBusACanError: start-on-event=DemSatellite_0InternalBehavior/GetEventTested, operation=EvtInfo_CantrcvEBusACanError.GetEventTested
        OpEventGetEventTested_GetEventTested_Event_CantrcvEBusACanError: start-on-event=DemSatellite_0InternalBehavior/GetEventTested, operation=Event_CantrcvEBusACanError.GetEventTested
        OpEventGetEventTested_GetEventTested_EvtInfo_UDPNM_E_TCPIP_TRANSMIT_ERROR: start-on-event=DemSatellite_0InternalBehavior/GetEventTested, operation=EvtInfo_UDPNM_E_TCPIP_TRANSMIT_ERROR.GetEventTested
        OpEventGetEventTested_GetEventTested_EvtInfo_DmTestCom: start-on-event=DemSatellite_0InternalBehavior/GetEventTested, operation=EvtInfo_DmTestCom.GetEventTested
        OpEventGetEventTested_GetEventTested_Event_DmTestCom: start-on-event=DemSatellite_0InternalBehavior/GetEventTested, operation=Event_DmTestCom.GetEventTested
        OpEventGetEventTested_GetEventTested_EvtInfo_CodingEventSignatureError: start-on-event=DemSatellite_0InternalBehavior/GetEventTested, operation=EvtInfo_CodingEventSignatureError.GetEventTested
        OpEventGetEventTested_GetEventTested_Event_CodingEventSignatureError: start-on-event=DemSatellite_0InternalBehavior/GetEventTested, operation=Event_CodingEventSignatureError.GetEventTested
        OpEventGetEventTested_GetEventTested_EvtInfo_CodingEventUnqualifiedData: start-on-event=DemSatellite_0InternalBehavior/GetEventTested, operation=EvtInfo_CodingEventUnqualifiedData.GetEventTested
        OpEventGetEventTested_GetEventTested_Event_CodingEventUnqualifiedData: start-on-event=DemSatellite_0InternalBehavior/GetEventTested, operation=Event_CodingEventUnqualifiedData.GetEventTested
        OpEventGetEventTested_GetEventTested_EvtInfo_CodingEventInvalidData: start-on-event=DemSatellite_0InternalBehavior/GetEventTested, operation=EvtInfo_CodingEventInvalidData.GetEventTested
        OpEventGetEventTested_GetEventTested_Event_CodingEventInvalidData: start-on-event=DemSatellite_0InternalBehavior/GetEventTested, operation=Event_CodingEventInvalidData.GetEventTested
        OpEventGetEventTested_GetEventTested_EvtInfo_CansmEBusB2CanOff: start-on-event=DemSatellite_0InternalBehavior/GetEventTested, operation=EvtInfo_CansmEBusB2CanOff.GetEventTested
        OpEventGetEventTested_GetEventTested_Event_CansmEBusB2CanOff: start-on-event=DemSatellite_0InternalBehavior/GetEventTested, operation=Event_CansmEBusB2CanOff.GetEventTested
        OpEventGetEventTested_GetEventTested_EvtInfo_Overvoltage: start-on-event=DemSatellite_0InternalBehavior/GetEventTested, operation=EvtInfo_Overvoltage.GetEventTested
        OpEventGetEventTested_GetEventTested_Event_Overvoltage: start-on-event=DemSatellite_0InternalBehavior/GetEventTested, operation=Event_Overvoltage.GetEventTested
        OpEventGetEventTested_GetEventTested_EvtInfo_CodingEventNotCoded: start-on-event=DemSatellite_0InternalBehavior/GetEventTested, operation=EvtInfo_CodingEventNotCoded.GetEventTested
        OpEventGetEventTested_GetEventTested_Event_CodingEventNotCoded: start-on-event=DemSatellite_0InternalBehavior/GetEventTested, operation=Event_CodingEventNotCoded.GetEventTested
        OpEventGetEventTested_GetEventTested_EvtInfo_FrifEAcsChA: start-on-event=DemSatellite_0InternalBehavior/GetEventTested, operation=EvtInfo_FrifEAcsChA.GetEventTested
        OpEventGetEventTested_GetEventTested_Event_FrifEAcsChA: start-on-event=DemSatellite_0InternalBehavior/GetEventTested, operation=Event_FrifEAcsChA.GetEventTested
        OpEventGetEventTested_GetEventTested_EvtInfo_CantrcvEBusFaCanError: start-on-event=DemSatellite_0InternalBehavior/GetEventTested, operation=EvtInfo_CantrcvEBusFaCanError.GetEventTested
        OpEventGetEventTested_GetEventTested_Event_CantrcvEBusFaCanError: start-on-event=DemSatellite_0InternalBehavior/GetEventTested, operation=Event_CantrcvEBusFaCanError.GetEventTested
        OpEventGetEventTested_GetEventTested_EvtInfo_CantrcvEBusLeCanError: start-on-event=DemSatellite_0InternalBehavior/GetEventTested, operation=EvtInfo_CantrcvEBusLeCanError.GetEventTested
        OpEventGetEventTested_GetEventTested_Event_CantrcvEBusLeCanError: start-on-event=DemSatellite_0InternalBehavior/GetEventTested, operation=Event_CantrcvEBusLeCanError.GetEventTested
        OpEventGetEventTested_GetEventTested_EvtInfo_CantrcvEBusLpCanError: start-on-event=DemSatellite_0InternalBehavior/GetEventTested, operation=EvtInfo_CantrcvEBusLpCanError.GetEventTested
        OpEventGetEventTested_GetEventTested_Event_CantrcvEBusLpCanError: start-on-event=DemSatellite_0InternalBehavior/GetEventTested, operation=Event_CantrcvEBusLpCanError.GetEventTested
        OpEventGetEventTested_GetEventTested_EvtInfo_CantrcvEBusZsgCanError: start-on-event=DemSatellite_0InternalBehavior/GetEventTested, operation=EvtInfo_CantrcvEBusZsgCanError.GetEventTested
        OpEventGetEventTested_GetEventTested_Event_CantrcvEBusZsgCanError: start-on-event=DemSatellite_0InternalBehavior/GetEventTested, operation=Event_CantrcvEBusZsgCanError.GetEventTested
        OpEventGetEventTested_GetEventTested_EvtInfo_EthSignalQualityLow: start-on-event=DemSatellite_0InternalBehavior/GetEventTested, operation=EvtInfo_EthSignalQualityLow.GetEventTested
        OpEventGetEventTested_GetEventTested_Event_EthSignalQualityLow: start-on-event=DemSatellite_0InternalBehavior/GetEventTested, operation=Event_EthSignalQualityLow.GetEventTested
        OpEventGetEventTested_GetEventTested_EvtInfo_DemEventParameter_FlsConfigSet_FLS_E_COMPARE_FAILED: start-on-event=DemSatellite_0InternalBehavior/GetEventTested, operation=EvtInfo_DemEventParameter_FlsConfigSet_FLS_E_COMPARE_FAILED.GetEventTested
        OpEventGetEventTested_GetEventTested_EvtInfo_DemEventParameter_FlsConfigSet_FLS_E_ERASE_FAILED: start-on-event=DemSatellite_0InternalBehavior/GetEventTested, operation=EvtInfo_DemEventParameter_FlsConfigSet_FLS_E_ERASE_FAILED.GetEventTested
        OpEventGetEventTested_GetEventTested_EvtInfo_DemEventParameter_FlsConfigSet_FLS_E_READ_FAILED: start-on-event=DemSatellite_0InternalBehavior/GetEventTested, operation=EvtInfo_DemEventParameter_FlsConfigSet_FLS_E_READ_FAILED.GetEventTested
        OpEventGetEventTested_GetEventTested_EvtInfo_DemEventParameter_FlsConfigSet_FLS_E_WRITE_FAILED: start-on-event=DemSatellite_0InternalBehavior/GetEventTested, operation=EvtInfo_DemEventParameter_FlsConfigSet_FLS_E_WRITE_FAILED.GetEventTested
        OpEventGetEventTested_GetEventTested_EvtInfo_DemEventParameter_FlsConfigSet_FLS_E_READ_DED_FAILED: start-on-event=DemSatellite_0InternalBehavior/GetEventTested, operation=EvtInfo_DemEventParameter_FlsConfigSet_FLS_E_READ_DED_FAILED.GetEventTested
        OpEventGetEventTested_GetEventTested_EvtInfo_DemEventParameter_FlsConfigSet_FLS_E_UNEXPECTED_FLASH_ID: start-on-event=DemSatellite_0InternalBehavior/GetEventTested, operation=EvtInfo_DemEventParameter_FlsConfigSet_FLS_E_UNEXPECTED_FLASH_ID.GetEventTested
        OpEventGetEventTested_GetEventTested_EvtInfo_DemEventParameter_FlsConfigSet_MCU_E_CLOCK_FAILED: start-on-event=DemSatellite_0InternalBehavior/GetEventTested, operation=EvtInfo_DemEventParameter_FlsConfigSet_MCU_E_CLOCK_FAILED.GetEventTested
        OpEventGetEventTested_GetEventTested_EvtInfo_DemEventParameter_FlsConfigSet_MCU_E_HW_FAILED: start-on-event=DemSatellite_0InternalBehavior/GetEventTested, operation=EvtInfo_DemEventParameter_FlsConfigSet_MCU_E_HW_FAILED.GetEventTested
        OpEventGetEventTested_GetEventTested_EvtInfo_DemEventParameter_FlsConfigSet_MCU_E_STARTUP_FAILED: start-on-event=DemSatellite_0InternalBehavior/GetEventTested, operation=EvtInfo_DemEventParameter_FlsConfigSet_MCU_E_STARTUP_FAILED.GetEventTested
        OpEventGetEventTested_GetEventTested_EvtInfo_DemEventParameter_FlsConfigSet_FLS_E_ECC_FAILED: start-on-event=DemSatellite_0InternalBehavior/GetEventTested, operation=EvtInfo_DemEventParameter_FlsConfigSet_FLS_E_ECC_FAILED.GetEventTested
        OpEventGetEventTested_GetEventTested_EvtInfo_DemEventParameter_FlsConfigSet_FLS_E_VRFY_FAILED: start-on-event=DemSatellite_0InternalBehavior/GetEventTested, operation=EvtInfo_DemEventParameter_FlsConfigSet_FLS_E_VRFY_FAILED.GetEventTested
        OpEventGetEventTested_GetEventTested_EvtInfo_DemEventParameter_FlsConfigSet_FLS_E_INT_FAILED: start-on-event=DemSatellite_0InternalBehavior/GetEventTested, operation=EvtInfo_DemEventParameter_FlsConfigSet_FLS_E_INT_FAILED.GetEventTested
        OpEventGetEventTested_GetEventTested_EvtInfo_DemEventParameter_FlsConfigSet_FLS_E_HW_FAILED: start-on-event=DemSatellite_0InternalBehavior/GetEventTested, operation=EvtInfo_DemEventParameter_FlsConfigSet_FLS_E_HW_FAILED.GetEventTested
        OpEventGetEventTested_GetEventTested_GeneralEventInfo: start-on-event=DemSatellite_0InternalBehavior/GetEventTested, operation=GeneralEventInfo.GetEventTested
        OpEventGetDTCOfEvent_GetDTCOfEvent_EvtInfo_FrtrcvEFrErrnTrcv0: start-on-event=DemSatellite_0InternalBehavior/GetDTCOfEvent, operation=EvtInfo_FrtrcvEFrErrnTrcv0.GetDTCOfEvent
        OpEventGetDTCOfEvent_GetDTCOfEvent_Event_FrtrcvEFrErrnTrcv0: start-on-event=DemSatellite_0InternalBehavior/GetDTCOfEvent, operation=Event_FrtrcvEFrErrnTrcv0.GetDTCOfEvent
        OpEventGetDTCOfEvent_GetDTCOfEvent_EvtInfo_CansmEBusIukCanOff: start-on-event=DemSatellite_0InternalBehavior/GetDTCOfEvent, operation=EvtInfo_CansmEBusIukCanOff.GetDTCOfEvent
        OpEventGetDTCOfEvent_GetDTCOfEvent_Event_CansmEBusIukCanOff: start-on-event=DemSatellite_0InternalBehavior/GetDTCOfEvent, operation=Event_CansmEBusIukCanOff.GetDTCOfEvent
        OpEventGetDTCOfEvent_GetDTCOfEvent_EvtInfo_FrtrcvEFrErrnTrcv2: start-on-event=DemSatellite_0InternalBehavior/GetDTCOfEvent, operation=EvtInfo_FrtrcvEFrErrnTrcv2.GetDTCOfEvent
        OpEventGetDTCOfEvent_GetDTCOfEvent_Event_FrtrcvEFrErrnTrcv2: start-on-event=DemSatellite_0InternalBehavior/GetDTCOfEvent, operation=Event_FrtrcvEFrErrnTrcv2.GetDTCOfEvent
        OpEventGetDTCOfEvent_GetDTCOfEvent_EvtInfo_FrtrcvEFrErrnTrcv1: start-on-event=DemSatellite_0InternalBehavior/GetDTCOfEvent, operation=EvtInfo_FrtrcvEFrErrnTrcv1.GetDTCOfEvent
        OpEventGetDTCOfEvent_GetDTCOfEvent_Event_FrtrcvEFrErrnTrcv1: start-on-event=DemSatellite_0InternalBehavior/GetDTCOfEvent, operation=Event_FrtrcvEFrErrnTrcv1.GetDTCOfEvent
        OpEventGetDTCOfEvent_GetDTCOfEvent_EvtInfo_FrtrcvEFrErrnTrcv4: start-on-event=DemSatellite_0InternalBehavior/GetDTCOfEvent, operation=EvtInfo_FrtrcvEFrErrnTrcv4.GetDTCOfEvent
        OpEventGetDTCOfEvent_GetDTCOfEvent_Event_FrtrcvEFrErrnTrcv4: start-on-event=DemSatellite_0InternalBehavior/GetDTCOfEvent, operation=Event_FrtrcvEFrErrnTrcv4.GetDTCOfEvent
        OpEventGetDTCOfEvent_GetDTCOfEvent_EvtInfo_FrtrcvEFrErrnTrcv3: start-on-event=DemSatellite_0InternalBehavior/GetDTCOfEvent, operation=EvtInfo_FrtrcvEFrErrnTrcv3.GetDTCOfEvent
        OpEventGetDTCOfEvent_GetDTCOfEvent_Event_FrtrcvEFrErrnTrcv3: start-on-event=DemSatellite_0InternalBehavior/GetDTCOfEvent, operation=Event_FrtrcvEFrErrnTrcv3.GetDTCOfEvent
        OpEventGetDTCOfEvent_GetDTCOfEvent_EvtInfo_FrtrcvEFrErrnTrcv6: start-on-event=DemSatellite_0InternalBehavior/GetDTCOfEvent, operation=EvtInfo_FrtrcvEFrErrnTrcv6.GetDTCOfEvent
        OpEventGetDTCOfEvent_GetDTCOfEvent_Event_FrtrcvEFrErrnTrcv6: start-on-event=DemSatellite_0InternalBehavior/GetDTCOfEvent, operation=Event_FrtrcvEFrErrnTrcv6.GetDTCOfEvent
        OpEventGetDTCOfEvent_GetDTCOfEvent_EvtInfo_FrtrcvEFrErrnTrcv5: start-on-event=DemSatellite_0InternalBehavior/GetDTCOfEvent, operation=EvtInfo_FrtrcvEFrErrnTrcv5.GetDTCOfEvent
        OpEventGetDTCOfEvent_GetDTCOfEvent_Event_FrtrcvEFrErrnTrcv5: start-on-event=DemSatellite_0InternalBehavior/GetDTCOfEvent, operation=Event_FrtrcvEFrErrnTrcv5.GetDTCOfEvent
        OpEventGetDTCOfEvent_GetDTCOfEvent_EvtInfo_CansmEBusBodyCanOff: start-on-event=DemSatellite_0InternalBehavior/GetDTCOfEvent, operation=EvtInfo_CansmEBusBodyCanOff.GetDTCOfEvent
        OpEventGetDTCOfEvent_GetDTCOfEvent_Event_CansmEBusBodyCanOff: start-on-event=DemSatellite_0InternalBehavior/GetDTCOfEvent, operation=Event_CansmEBusBodyCanOff.GetDTCOfEvent
        OpEventGetDTCOfEvent_GetDTCOfEvent_EvtInfo_CbsReplacementValue: start-on-event=DemSatellite_0InternalBehavior/GetDTCOfEvent, operation=EvtInfo_CbsReplacementValue.GetDTCOfEvent
        OpEventGetDTCOfEvent_GetDTCOfEvent_Event_CbsReplacementValue: start-on-event=DemSatellite_0InternalBehavior/GetDTCOfEvent, operation=Event_CbsReplacementValue.GetDTCOfEvent
        OpEventGetDTCOfEvent_GetDTCOfEvent_EvtInfo_CansmEBusLeCanOff: start-on-event=DemSatellite_0InternalBehavior/GetDTCOfEvent, operation=EvtInfo_CansmEBusLeCanOff.GetDTCOfEvent
        OpEventGetDTCOfEvent_GetDTCOfEvent_Event_CansmEBusLeCanOff: start-on-event=DemSatellite_0InternalBehavior/GetDTCOfEvent, operation=Event_CansmEBusLeCanOff.GetDTCOfEvent
        OpEventGetDTCOfEvent_GetDTCOfEvent_EvtInfo_CansmEBusZsgCanOff: start-on-event=DemSatellite_0InternalBehavior/GetDTCOfEvent, operation=EvtInfo_CansmEBusZsgCanOff.GetDTCOfEvent
        OpEventGetDTCOfEvent_GetDTCOfEvent_Event_CansmEBusZsgCanOff: start-on-event=DemSatellite_0InternalBehavior/GetDTCOfEvent, operation=Event_CansmEBusZsgCanOff.GetDTCOfEvent
        OpEventGetDTCOfEvent_GetDTCOfEvent_EvtInfo_CodingEventWrongVehicle: start-on-event=DemSatellite_0InternalBehavior/GetDTCOfEvent, operation=EvtInfo_CodingEventWrongVehicle.GetDTCOfEvent
        OpEventGetDTCOfEvent_GetDTCOfEvent_Event_CodingEventWrongVehicle: start-on-event=DemSatellite_0InternalBehavior/GetDTCOfEvent, operation=Event_CodingEventWrongVehicle.GetDTCOfEvent
        OpEventGetDTCOfEvent_GetDTCOfEvent_EvtInfo_FrsmEClusterStartup: start-on-event=DemSatellite_0InternalBehavior/GetDTCOfEvent, operation=EvtInfo_FrsmEClusterStartup.GetDTCOfEvent
        OpEventGetDTCOfEvent_GetDTCOfEvent_Event_FrsmEClusterStartup: start-on-event=DemSatellite_0InternalBehavior/GetDTCOfEvent, operation=Event_FrsmEClusterStartup.GetDTCOfEvent
        OpEventGetDTCOfEvent_GetDTCOfEvent_EvtInfo_CansmEBusACanOff: start-on-event=DemSatellite_0InternalBehavior/GetDTCOfEvent, operation=EvtInfo_CansmEBusACanOff.GetDTCOfEvent
        OpEventGetDTCOfEvent_GetDTCOfEvent_Event_CansmEBusACanOff: start-on-event=DemSatellite_0InternalBehavior/GetDTCOfEvent, operation=Event_CansmEBusACanOff.GetDTCOfEvent
        OpEventGetDTCOfEvent_GetDTCOfEvent_EvtInfo_CansmEBusKCanOff: start-on-event=DemSatellite_0InternalBehavior/GetDTCOfEvent, operation=EvtInfo_CansmEBusKCanOff.GetDTCOfEvent
        OpEventGetDTCOfEvent_GetDTCOfEvent_Event_CansmEBusKCanOff: start-on-event=DemSatellite_0InternalBehavior/GetDTCOfEvent, operation=Event_CansmEBusKCanOff.GetDTCOfEvent
        OpEventGetDTCOfEvent_GetDTCOfEvent_EvtInfo_CantrcvEBusKCanError: start-on-event=DemSatellite_0InternalBehavior/GetDTCOfEvent, operation=EvtInfo_CantrcvEBusKCanError.GetDTCOfEvent
        OpEventGetDTCOfEvent_GetDTCOfEvent_Event_CantrcvEBusKCanError: start-on-event=DemSatellite_0InternalBehavior/GetDTCOfEvent, operation=Event_CantrcvEBusKCanError.GetDTCOfEvent
        OpEventGetDTCOfEvent_GetDTCOfEvent_EvtInfo_FrtrcvEFrBuserrorTrcv0: start-on-event=DemSatellite_0InternalBehavior/GetDTCOfEvent, operation=EvtInfo_FrtrcvEFrBuserrorTrcv0.GetDTCOfEvent
        OpEventGetDTCOfEvent_GetDTCOfEvent_Event_FrtrcvEFrBuserrorTrcv0: start-on-event=DemSatellite_0InternalBehavior/GetDTCOfEvent, operation=Event_FrtrcvEFrBuserrorTrcv0.GetDTCOfEvent
        OpEventGetDTCOfEvent_GetDTCOfEvent_EvtInfo_FrtrcvEFrErrnTrcv7: start-on-event=DemSatellite_0InternalBehavior/GetDTCOfEvent, operation=EvtInfo_FrtrcvEFrErrnTrcv7.GetDTCOfEvent
        OpEventGetDTCOfEvent_GetDTCOfEvent_Event_FrtrcvEFrErrnTrcv7: start-on-event=DemSatellite_0InternalBehavior/GetDTCOfEvent, operation=Event_FrtrcvEFrErrnTrcv7.GetDTCOfEvent
        OpEventGetDTCOfEvent_GetDTCOfEvent_EvtInfo_CansmEBusFaCanOff: start-on-event=DemSatellite_0InternalBehavior/GetDTCOfEvent, operation=EvtInfo_CansmEBusFaCanOff.GetDTCOfEvent
        OpEventGetDTCOfEvent_GetDTCOfEvent_Event_CansmEBusFaCanOff: start-on-event=DemSatellite_0InternalBehavior/GetDTCOfEvent, operation=Event_CansmEBusFaCanOff.GetDTCOfEvent
        OpEventGetDTCOfEvent_GetDTCOfEvent_EvtInfo_CantrcvEBusB2CanError: start-on-event=DemSatellite_0InternalBehavior/GetDTCOfEvent, operation=EvtInfo_CantrcvEBusB2CanError.GetDTCOfEvent
        OpEventGetDTCOfEvent_GetDTCOfEvent_Event_CantrcvEBusB2CanError: start-on-event=DemSatellite_0InternalBehavior/GetDTCOfEvent, operation=Event_CantrcvEBusB2CanError.GetDTCOfEvent
        OpEventGetDTCOfEvent_GetDTCOfEvent_EvtInfo_DtcCd0605: start-on-event=DemSatellite_0InternalBehavior/GetDTCOfEvent, operation=EvtInfo_DtcCd0605.GetDTCOfEvent
        OpEventGetDTCOfEvent_GetDTCOfEvent_Event_DtcCd0605: start-on-event=DemSatellite_0InternalBehavior/GetDTCOfEvent, operation=Event_DtcCd0605.GetDTCOfEvent
        OpEventGetDTCOfEvent_GetDTCOfEvent_EvtInfo_DtcCd0606: start-on-event=DemSatellite_0InternalBehavior/GetDTCOfEvent, operation=EvtInfo_DtcCd0606.GetDTCOfEvent
        OpEventGetDTCOfEvent_GetDTCOfEvent_Event_DtcCd0606: start-on-event=DemSatellite_0InternalBehavior/GetDTCOfEvent, operation=Event_DtcCd0606.GetDTCOfEvent
        OpEventGetDTCOfEvent_GetDTCOfEvent_EvtInfo_DtcCd0607: start-on-event=DemSatellite_0InternalBehavior/GetDTCOfEvent, operation=EvtInfo_DtcCd0607.GetDTCOfEvent
        OpEventGetDTCOfEvent_GetDTCOfEvent_Event_DtcCd0607: start-on-event=DemSatellite_0InternalBehavior/GetDTCOfEvent, operation=Event_DtcCd0607.GetDTCOfEvent
        OpEventGetDTCOfEvent_GetDTCOfEvent_EvtInfo_PiaEIoError: start-on-event=DemSatellite_0InternalBehavior/GetDTCOfEvent, operation=EvtInfo_PiaEIoError.GetDTCOfEvent
        OpEventGetDTCOfEvent_GetDTCOfEvent_Event_PiaEIoError: start-on-event=DemSatellite_0InternalBehavior/GetDTCOfEvent, operation=Event_PiaEIoError.GetDTCOfEvent
        OpEventGetDTCOfEvent_GetDTCOfEvent_EvtInfo_DtcCd0601: start-on-event=DemSatellite_0InternalBehavior/GetDTCOfEvent, operation=EvtInfo_DtcCd0601.GetDTCOfEvent
        OpEventGetDTCOfEvent_GetDTCOfEvent_Event_DtcCd0601: start-on-event=DemSatellite_0InternalBehavior/GetDTCOfEvent, operation=Event_DtcCd0601.GetDTCOfEvent
        OpEventGetDTCOfEvent_GetDTCOfEvent_EvtInfo_SwtExternalCheckFailure: start-on-event=DemSatellite_0InternalBehavior/GetDTCOfEvent, operation=EvtInfo_SwtExternalCheckFailure.GetDTCOfEvent
        OpEventGetDTCOfEvent_GetDTCOfEvent_Event_SwtExternalCheckFailure: start-on-event=DemSatellite_0InternalBehavior/GetDTCOfEvent, operation=Event_SwtExternalCheckFailure.GetDTCOfEvent
        OpEventGetDTCOfEvent_GetDTCOfEvent_EvtInfo_CantrcvEBusBodyCanError: start-on-event=DemSatellite_0InternalBehavior/GetDTCOfEvent, operation=EvtInfo_CantrcvEBusBodyCanError.GetDTCOfEvent
        OpEventGetDTCOfEvent_GetDTCOfEvent_Event_CantrcvEBusBodyCanError: start-on-event=DemSatellite_0InternalBehavior/GetDTCOfEvent, operation=Event_CantrcvEBusBodyCanError.GetDTCOfEvent
        OpEventGetDTCOfEvent_GetDTCOfEvent_EvtInfo_CantrcvEBusIukError: start-on-event=DemSatellite_0InternalBehavior/GetDTCOfEvent, operation=EvtInfo_CantrcvEBusIukError.GetDTCOfEvent
        OpEventGetDTCOfEvent_GetDTCOfEvent_Event_CantrcvEBusIukError: start-on-event=DemSatellite_0InternalBehavior/GetDTCOfEvent, operation=Event_CantrcvEBusIukError.GetDTCOfEvent
        OpEventGetDTCOfEvent_GetDTCOfEvent_EvtInfo_SwtInternalCheckFailure: start-on-event=DemSatellite_0InternalBehavior/GetDTCOfEvent, operation=EvtInfo_SwtInternalCheckFailure.GetDTCOfEvent
        OpEventGetDTCOfEvent_GetDTCOfEvent_Event_SwtInternalCheckFailure: start-on-event=DemSatellite_0InternalBehavior/GetDTCOfEvent, operation=Event_SwtInternalCheckFailure.GetDTCOfEvent
        OpEventGetDTCOfEvent_GetDTCOfEvent_EvtInfo_DmTestAppl: start-on-event=DemSatellite_0InternalBehavior/GetDTCOfEvent, operation=EvtInfo_DmTestAppl.GetDTCOfEvent
        OpEventGetDTCOfEvent_GetDTCOfEvent_Event_DmTestAppl: start-on-event=DemSatellite_0InternalBehavior/GetDTCOfEvent, operation=Event_DmTestAppl.GetDTCOfEvent
        OpEventGetDTCOfEvent_GetDTCOfEvent_EvtInfo_Dtc000032: start-on-event=DemSatellite_0InternalBehavior/GetDTCOfEvent, operation=EvtInfo_Dtc000032.GetDTCOfEvent
        OpEventGetDTCOfEvent_GetDTCOfEvent_Event_Dtc000032: start-on-event=DemSatellite_0InternalBehavior/GetDTCOfEvent, operation=Event_Dtc000032.GetDTCOfEvent
        OpEventGetDTCOfEvent_GetDTCOfEvent_EvtInfo_Dtc000031: start-on-event=DemSatellite_0InternalBehavior/GetDTCOfEvent, operation=EvtInfo_Dtc000031.GetDTCOfEvent
        OpEventGetDTCOfEvent_GetDTCOfEvent_Event_Dtc000031: start-on-event=DemSatellite_0InternalBehavior/GetDTCOfEvent, operation=Event_Dtc000031.GetDTCOfEvent
        OpEventGetDTCOfEvent_GetDTCOfEvent_EvtInfo_FrsmEClusterSyncLoss: start-on-event=DemSatellite_0InternalBehavior/GetDTCOfEvent, operation=EvtInfo_FrsmEClusterSyncLoss.GetDTCOfEvent
        OpEventGetDTCOfEvent_GetDTCOfEvent_Event_FrsmEClusterSyncLoss: start-on-event=DemSatellite_0InternalBehavior/GetDTCOfEvent, operation=Event_FrsmEClusterSyncLoss.GetDTCOfEvent
        OpEventGetDTCOfEvent_GetDTCOfEvent_EvtInfo_Dtc000030: start-on-event=DemSatellite_0InternalBehavior/GetDTCOfEvent, operation=EvtInfo_Dtc000030.GetDTCOfEvent
        OpEventGetDTCOfEvent_GetDTCOfEvent_Event_Dtc000030: start-on-event=DemSatellite_0InternalBehavior/GetDTCOfEvent, operation=Event_Dtc000030.GetDTCOfEvent
        OpEventGetDTCOfEvent_GetDTCOfEvent_EvtInfo_Dtc000034: start-on-event=DemSatellite_0InternalBehavior/GetDTCOfEvent, operation=EvtInfo_Dtc000034.GetDTCOfEvent
        OpEventGetDTCOfEvent_GetDTCOfEvent_Event_Dtc000034: start-on-event=DemSatellite_0InternalBehavior/GetDTCOfEvent, operation=Event_Dtc000034.GetDTCOfEvent
        OpEventGetDTCOfEvent_GetDTCOfEvent_EvtInfo_Dtc000033: start-on-event=DemSatellite_0InternalBehavior/GetDTCOfEvent, operation=EvtInfo_Dtc000033.GetDTCOfEvent
        OpEventGetDTCOfEvent_GetDTCOfEvent_Event_Dtc000033: start-on-event=DemSatellite_0InternalBehavior/GetDTCOfEvent, operation=Event_Dtc000033.GetDTCOfEvent
        OpEventGetDTCOfEvent_GetDTCOfEvent_EvtInfo_Undervoltage: start-on-event=DemSatellite_0InternalBehavior/GetDTCOfEvent, operation=EvtInfo_Undervoltage.GetDTCOfEvent
        OpEventGetDTCOfEvent_GetDTCOfEvent_Event_Undervoltage: start-on-event=DemSatellite_0InternalBehavior/GetDTCOfEvent, operation=Event_Undervoltage.GetDTCOfEvent
        OpEventGetDTCOfEvent_GetDTCOfEvent_EvtInfo_CodingEventTransactionFailed: start-on-event=DemSatellite_0InternalBehavior/GetDTCOfEvent, operation=EvtInfo_CodingEventTransactionFailed.GetDTCOfEvent
        OpEventGetDTCOfEvent_GetDTCOfEvent_Event_CodingEventTransactionFailed: start-on-event=DemSatellite_0InternalBehavior/GetDTCOfEvent, operation=Event_CodingEventTransactionFailed.GetDTCOfEvent
        OpEventGetDTCOfEvent_GetDTCOfEvent_EvtInfo_FrifENitChA: start-on-event=DemSatellite_0InternalBehavior/GetDTCOfEvent, operation=EvtInfo_FrifENitChA.GetDTCOfEvent
        OpEventGetDTCOfEvent_GetDTCOfEvent_Event_FrifENitChA: start-on-event=DemSatellite_0InternalBehavior/GetDTCOfEvent, operation=Event_FrifENitChA.GetDTCOfEvent
        OpEventGetDTCOfEvent_GetDTCOfEvent_EvtInfo_CansmEBusLpCanOff: start-on-event=DemSatellite_0InternalBehavior/GetDTCOfEvent, operation=EvtInfo_CansmEBusLpCanOff.GetDTCOfEvent
        OpEventGetDTCOfEvent_GetDTCOfEvent_Event_CansmEBusLpCanOff: start-on-event=DemSatellite_0InternalBehavior/GetDTCOfEvent, operation=Event_CansmEBusLpCanOff.GetDTCOfEvent
        OpEventGetDTCOfEvent_GetDTCOfEvent_EvtInfo_NVM_E_HARDWARE: start-on-event=DemSatellite_0InternalBehavior/GetDTCOfEvent, operation=EvtInfo_NVM_E_HARDWARE.GetDTCOfEvent
        OpEventGetDTCOfEvent_GetDTCOfEvent_EvtInfo_VsmEventOpmode: start-on-event=DemSatellite_0InternalBehavior/GetDTCOfEvent, operation=EvtInfo_VsmEventOpmode.GetDTCOfEvent
        OpEventGetDTCOfEvent_GetDTCOfEvent_Event_VsmEventOpmode: start-on-event=DemSatellite_0InternalBehavior/GetDTCOfEvent, operation=Event_VsmEventOpmode.GetDTCOfEvent
        OpEventGetDTCOfEvent_GetDTCOfEvent_EvtInfo_LIN_E_TIMEOUT: start-on-event=DemSatellite_0InternalBehavior/GetDTCOfEvent, operation=EvtInfo_LIN_E_TIMEOUT.GetDTCOfEvent
        OpEventGetDTCOfEvent_GetDTCOfEvent_EvtInfo_CantrcvEBusACanError: start-on-event=DemSatellite_0InternalBehavior/GetDTCOfEvent, operation=EvtInfo_CantrcvEBusACanError.GetDTCOfEvent
        OpEventGetDTCOfEvent_GetDTCOfEvent_Event_CantrcvEBusACanError: start-on-event=DemSatellite_0InternalBehavior/GetDTCOfEvent, operation=Event_CantrcvEBusACanError.GetDTCOfEvent
        OpEventGetDTCOfEvent_GetDTCOfEvent_EvtInfo_UDPNM_E_TCPIP_TRANSMIT_ERROR: start-on-event=DemSatellite_0InternalBehavior/GetDTCOfEvent, operation=EvtInfo_UDPNM_E_TCPIP_TRANSMIT_ERROR.GetDTCOfEvent
        OpEventGetDTCOfEvent_GetDTCOfEvent_EvtInfo_DmTestCom: start-on-event=DemSatellite_0InternalBehavior/GetDTCOfEvent, operation=EvtInfo_DmTestCom.GetDTCOfEvent
        OpEventGetDTCOfEvent_GetDTCOfEvent_Event_DmTestCom: start-on-event=DemSatellite_0InternalBehavior/GetDTCOfEvent, operation=Event_DmTestCom.GetDTCOfEvent
        OpEventGetDTCOfEvent_GetDTCOfEvent_EvtInfo_CodingEventSignatureError: start-on-event=DemSatellite_0InternalBehavior/GetDTCOfEvent, operation=EvtInfo_CodingEventSignatureError.GetDTCOfEvent
        OpEventGetDTCOfEvent_GetDTCOfEvent_Event_CodingEventSignatureError: start-on-event=DemSatellite_0InternalBehavior/GetDTCOfEvent, operation=Event_CodingEventSignatureError.GetDTCOfEvent
        OpEventGetDTCOfEvent_GetDTCOfEvent_EvtInfo_CodingEventUnqualifiedData: start-on-event=DemSatellite_0InternalBehavior/GetDTCOfEvent, operation=EvtInfo_CodingEventUnqualifiedData.GetDTCOfEvent
        OpEventGetDTCOfEvent_GetDTCOfEvent_Event_CodingEventUnqualifiedData: start-on-event=DemSatellite_0InternalBehavior/GetDTCOfEvent, operation=Event_CodingEventUnqualifiedData.GetDTCOfEvent
        OpEventGetDTCOfEvent_GetDTCOfEvent_EvtInfo_CodingEventInvalidData: start-on-event=DemSatellite_0InternalBehavior/GetDTCOfEvent, operation=EvtInfo_CodingEventInvalidData.GetDTCOfEvent
        OpEventGetDTCOfEvent_GetDTCOfEvent_Event_CodingEventInvalidData: start-on-event=DemSatellite_0InternalBehavior/GetDTCOfEvent, operation=Event_CodingEventInvalidData.GetDTCOfEvent
        OpEventGetDTCOfEvent_GetDTCOfEvent_EvtInfo_CansmEBusB2CanOff: start-on-event=DemSatellite_0InternalBehavior/GetDTCOfEvent, operation=EvtInfo_CansmEBusB2CanOff.GetDTCOfEvent
        OpEventGetDTCOfEvent_GetDTCOfEvent_Event_CansmEBusB2CanOff: start-on-event=DemSatellite_0InternalBehavior/GetDTCOfEvent, operation=Event_CansmEBusB2CanOff.GetDTCOfEvent
        OpEventGetDTCOfEvent_GetDTCOfEvent_EvtInfo_Overvoltage: start-on-event=DemSatellite_0InternalBehavior/GetDTCOfEvent, operation=EvtInfo_Overvoltage.GetDTCOfEvent
        OpEventGetDTCOfEvent_GetDTCOfEvent_Event_Overvoltage: start-on-event=DemSatellite_0InternalBehavior/GetDTCOfEvent, operation=Event_Overvoltage.GetDTCOfEvent
        OpEventGetDTCOfEvent_GetDTCOfEvent_EvtInfo_CodingEventNotCoded: start-on-event=DemSatellite_0InternalBehavior/GetDTCOfEvent, operation=EvtInfo_CodingEventNotCoded.GetDTCOfEvent
        OpEventGetDTCOfEvent_GetDTCOfEvent_Event_CodingEventNotCoded: start-on-event=DemSatellite_0InternalBehavior/GetDTCOfEvent, operation=Event_CodingEventNotCoded.GetDTCOfEvent
        OpEventGetDTCOfEvent_GetDTCOfEvent_EvtInfo_FrifEAcsChA: start-on-event=DemSatellite_0InternalBehavior/GetDTCOfEvent, operation=EvtInfo_FrifEAcsChA.GetDTCOfEvent
        OpEventGetDTCOfEvent_GetDTCOfEvent_Event_FrifEAcsChA: start-on-event=DemSatellite_0InternalBehavior/GetDTCOfEvent, operation=Event_FrifEAcsChA.GetDTCOfEvent
        OpEventGetDTCOfEvent_GetDTCOfEvent_EvtInfo_CantrcvEBusFaCanError: start-on-event=DemSatellite_0InternalBehavior/GetDTCOfEvent, operation=EvtInfo_CantrcvEBusFaCanError.GetDTCOfEvent
        OpEventGetDTCOfEvent_GetDTCOfEvent_Event_CantrcvEBusFaCanError: start-on-event=DemSatellite_0InternalBehavior/GetDTCOfEvent, operation=Event_CantrcvEBusFaCanError.GetDTCOfEvent
        OpEventGetDTCOfEvent_GetDTCOfEvent_EvtInfo_CantrcvEBusLeCanError: start-on-event=DemSatellite_0InternalBehavior/GetDTCOfEvent, operation=EvtInfo_CantrcvEBusLeCanError.GetDTCOfEvent
        OpEventGetDTCOfEvent_GetDTCOfEvent_Event_CantrcvEBusLeCanError: start-on-event=DemSatellite_0InternalBehavior/GetDTCOfEvent, operation=Event_CantrcvEBusLeCanError.GetDTCOfEvent
        OpEventGetDTCOfEvent_GetDTCOfEvent_EvtInfo_CantrcvEBusLpCanError: start-on-event=DemSatellite_0InternalBehavior/GetDTCOfEvent, operation=EvtInfo_CantrcvEBusLpCanError.GetDTCOfEvent
        OpEventGetDTCOfEvent_GetDTCOfEvent_Event_CantrcvEBusLpCanError: start-on-event=DemSatellite_0InternalBehavior/GetDTCOfEvent, operation=Event_CantrcvEBusLpCanError.GetDTCOfEvent
        OpEventGetDTCOfEvent_GetDTCOfEvent_EvtInfo_CantrcvEBusZsgCanError: start-on-event=DemSatellite_0InternalBehavior/GetDTCOfEvent, operation=EvtInfo_CantrcvEBusZsgCanError.GetDTCOfEvent
        OpEventGetDTCOfEvent_GetDTCOfEvent_Event_CantrcvEBusZsgCanError: start-on-event=DemSatellite_0InternalBehavior/GetDTCOfEvent, operation=Event_CantrcvEBusZsgCanError.GetDTCOfEvent
        OpEventGetDTCOfEvent_GetDTCOfEvent_EvtInfo_EthSignalQualityLow: start-on-event=DemSatellite_0InternalBehavior/GetDTCOfEvent, operation=EvtInfo_EthSignalQualityLow.GetDTCOfEvent
        OpEventGetDTCOfEvent_GetDTCOfEvent_Event_EthSignalQualityLow: start-on-event=DemSatellite_0InternalBehavior/GetDTCOfEvent, operation=Event_EthSignalQualityLow.GetDTCOfEvent
        OpEventGetDTCOfEvent_GetDTCOfEvent_EvtInfo_DemEventParameter_FlsConfigSet_FLS_E_COMPARE_FAILED: start-on-event=DemSatellite_0InternalBehavior/GetDTCOfEvent, operation=EvtInfo_DemEventParameter_FlsConfigSet_FLS_E_COMPARE_FAILED.GetDTCOfEvent
        OpEventGetDTCOfEvent_GetDTCOfEvent_EvtInfo_DemEventParameter_FlsConfigSet_FLS_E_ERASE_FAILED: start-on-event=DemSatellite_0InternalBehavior/GetDTCOfEvent, operation=EvtInfo_DemEventParameter_FlsConfigSet_FLS_E_ERASE_FAILED.GetDTCOfEvent
        OpEventGetDTCOfEvent_GetDTCOfEvent_EvtInfo_DemEventParameter_FlsConfigSet_FLS_E_READ_FAILED: start-on-event=DemSatellite_0InternalBehavior/GetDTCOfEvent, operation=EvtInfo_DemEventParameter_FlsConfigSet_FLS_E_READ_FAILED.GetDTCOfEvent
        OpEventGetDTCOfEvent_GetDTCOfEvent_EvtInfo_DemEventParameter_FlsConfigSet_FLS_E_WRITE_FAILED: start-on-event=DemSatellite_0InternalBehavior/GetDTCOfEvent, operation=EvtInfo_DemEventParameter_FlsConfigSet_FLS_E_WRITE_FAILED.GetDTCOfEvent
        OpEventGetDTCOfEvent_GetDTCOfEvent_EvtInfo_DemEventParameter_FlsConfigSet_FLS_E_READ_DED_FAILED: start-on-event=DemSatellite_0InternalBehavior/GetDTCOfEvent, operation=EvtInfo_DemEventParameter_FlsConfigSet_FLS_E_READ_DED_FAILED.GetDTCOfEvent
        OpEventGetDTCOfEvent_GetDTCOfEvent_EvtInfo_DemEventParameter_FlsConfigSet_FLS_E_UNEXPECTED_FLASH_ID: start-on-event=DemSatellite_0InternalBehavior/GetDTCOfEvent, operation=EvtInfo_DemEventParameter_FlsConfigSet_FLS_E_UNEXPECTED_FLASH_ID.GetDTCOfEvent
        OpEventGetDTCOfEvent_GetDTCOfEvent_EvtInfo_DemEventParameter_FlsConfigSet_MCU_E_CLOCK_FAILED: start-on-event=DemSatellite_0InternalBehavior/GetDTCOfEvent, operation=EvtInfo_DemEventParameter_FlsConfigSet_MCU_E_CLOCK_FAILED.GetDTCOfEvent
        OpEventGetDTCOfEvent_GetDTCOfEvent_EvtInfo_DemEventParameter_FlsConfigSet_MCU_E_HW_FAILED: start-on-event=DemSatellite_0InternalBehavior/GetDTCOfEvent, operation=EvtInfo_DemEventParameter_FlsConfigSet_MCU_E_HW_FAILED.GetDTCOfEvent
        OpEventGetDTCOfEvent_GetDTCOfEvent_EvtInfo_DemEventParameter_FlsConfigSet_MCU_E_STARTUP_FAILED: start-on-event=DemSatellite_0InternalBehavior/GetDTCOfEvent, operation=EvtInfo_DemEventParameter_FlsConfigSet_MCU_E_STARTUP_FAILED.GetDTCOfEvent
        OpEventGetDTCOfEvent_GetDTCOfEvent_EvtInfo_DemEventParameter_FlsConfigSet_FLS_E_ECC_FAILED: start-on-event=DemSatellite_0InternalBehavior/GetDTCOfEvent, operation=EvtInfo_DemEventParameter_FlsConfigSet_FLS_E_ECC_FAILED.GetDTCOfEvent
        OpEventGetDTCOfEvent_GetDTCOfEvent_EvtInfo_DemEventParameter_FlsConfigSet_FLS_E_VRFY_FAILED: start-on-event=DemSatellite_0InternalBehavior/GetDTCOfEvent, operation=EvtInfo_DemEventParameter_FlsConfigSet_FLS_E_VRFY_FAILED.GetDTCOfEvent
        OpEventGetDTCOfEvent_GetDTCOfEvent_EvtInfo_DemEventParameter_FlsConfigSet_FLS_E_INT_FAILED: start-on-event=DemSatellite_0InternalBehavior/GetDTCOfEvent, operation=EvtInfo_DemEventParameter_FlsConfigSet_FLS_E_INT_FAILED.GetDTCOfEvent
        OpEventGetDTCOfEvent_GetDTCOfEvent_EvtInfo_DemEventParameter_FlsConfigSet_FLS_E_HW_FAILED: start-on-event=DemSatellite_0InternalBehavior/GetDTCOfEvent, operation=EvtInfo_DemEventParameter_FlsConfigSet_FLS_E_HW_FAILED.GetDTCOfEvent
        OpEventGetDTCOfEvent_GetDTCOfEvent_GeneralEventInfo: start-on-event=DemSatellite_0InternalBehavior/GetDTCOfEvent, operation=GeneralEventInfo.GetDTCOfEvent
        OpEventGetFaultDetectionCounter_GetFaultDetectionCounter_EvtInfo_FrtrcvEFrErrnTrcv0: start-on-event=DemSatellite_0InternalBehavior/GetFaultDetectionCounter, operation=EvtInfo_FrtrcvEFrErrnTrcv0.GetFaultDetectionCounter
        OpEventGetFaultDetectionCounter_GetFaultDetectionCounter_Event_FrtrcvEFrErrnTrcv0: start-on-event=DemSatellite_0InternalBehavior/GetFaultDetectionCounter, operation=Event_FrtrcvEFrErrnTrcv0.GetFaultDetectionCounter
        OpEventGetFaultDetectionCounter_GetFaultDetectionCounter_EvtInfo_CansmEBusIukCanOff: start-on-event=DemSatellite_0InternalBehavior/GetFaultDetectionCounter, operation=EvtInfo_CansmEBusIukCanOff.GetFaultDetectionCounter
        OpEventGetFaultDetectionCounter_GetFaultDetectionCounter_Event_CansmEBusIukCanOff: start-on-event=DemSatellite_0InternalBehavior/GetFaultDetectionCounter, operation=Event_CansmEBusIukCanOff.GetFaultDetectionCounter
        OpEventGetFaultDetectionCounter_GetFaultDetectionCounter_EvtInfo_FrtrcvEFrErrnTrcv2: start-on-event=DemSatellite_0InternalBehavior/GetFaultDetectionCounter, operation=EvtInfo_FrtrcvEFrErrnTrcv2.GetFaultDetectionCounter
        OpEventGetFaultDetectionCounter_GetFaultDetectionCounter_Event_FrtrcvEFrErrnTrcv2: start-on-event=DemSatellite_0InternalBehavior/GetFaultDetectionCounter, operation=Event_FrtrcvEFrErrnTrcv2.GetFaultDetectionCounter
        OpEventGetFaultDetectionCounter_GetFaultDetectionCounter_EvtInfo_FrtrcvEFrErrnTrcv1: start-on-event=DemSatellite_0InternalBehavior/GetFaultDetectionCounter, operation=EvtInfo_FrtrcvEFrErrnTrcv1.GetFaultDetectionCounter
        OpEventGetFaultDetectionCounter_GetFaultDetectionCounter_Event_FrtrcvEFrErrnTrcv1: start-on-event=DemSatellite_0InternalBehavior/GetFaultDetectionCounter, operation=Event_FrtrcvEFrErrnTrcv1.GetFaultDetectionCounter
        OpEventGetFaultDetectionCounter_GetFaultDetectionCounter_EvtInfo_FrtrcvEFrErrnTrcv4: start-on-event=DemSatellite_0InternalBehavior/GetFaultDetectionCounter, operation=EvtInfo_FrtrcvEFrErrnTrcv4.GetFaultDetectionCounter
        OpEventGetFaultDetectionCounter_GetFaultDetectionCounter_Event_FrtrcvEFrErrnTrcv4: start-on-event=DemSatellite_0InternalBehavior/GetFaultDetectionCounter, operation=Event_FrtrcvEFrErrnTrcv4.GetFaultDetectionCounter
        OpEventGetFaultDetectionCounter_GetFaultDetectionCounter_EvtInfo_FrtrcvEFrErrnTrcv3: start-on-event=DemSatellite_0InternalBehavior/GetFaultDetectionCounter, operation=EvtInfo_FrtrcvEFrErrnTrcv3.GetFaultDetectionCounter
        OpEventGetFaultDetectionCounter_GetFaultDetectionCounter_Event_FrtrcvEFrErrnTrcv3: start-on-event=DemSatellite_0InternalBehavior/GetFaultDetectionCounter, operation=Event_FrtrcvEFrErrnTrcv3.GetFaultDetectionCounter
        OpEventGetFaultDetectionCounter_GetFaultDetectionCounter_EvtInfo_FrtrcvEFrErrnTrcv6: start-on-event=DemSatellite_0InternalBehavior/GetFaultDetectionCounter, operation=EvtInfo_FrtrcvEFrErrnTrcv6.GetFaultDetectionCounter
        OpEventGetFaultDetectionCounter_GetFaultDetectionCounter_Event_FrtrcvEFrErrnTrcv6: start-on-event=DemSatellite_0InternalBehavior/GetFaultDetectionCounter, operation=Event_FrtrcvEFrErrnTrcv6.GetFaultDetectionCounter
        OpEventGetFaultDetectionCounter_GetFaultDetectionCounter_EvtInfo_FrtrcvEFrErrnTrcv5: start-on-event=DemSatellite_0InternalBehavior/GetFaultDetectionCounter, operation=EvtInfo_FrtrcvEFrErrnTrcv5.GetFaultDetectionCounter
        OpEventGetFaultDetectionCounter_GetFaultDetectionCounter_Event_FrtrcvEFrErrnTrcv5: start-on-event=DemSatellite_0InternalBehavior/GetFaultDetectionCounter, operation=Event_FrtrcvEFrErrnTrcv5.GetFaultDetectionCounter
        OpEventGetFaultDetectionCounter_GetFaultDetectionCounter_EvtInfo_CansmEBusBodyCanOff: start-on-event=DemSatellite_0InternalBehavior/GetFaultDetectionCounter, operation=EvtInfo_CansmEBusBodyCanOff.GetFaultDetectionCounter
